VERSION "eCMP INFO-DIV vehicle review 2026-11-03; 125000 bit/s; PSA-RE 67f7581e7622410efdbb29c7eda3b86982b9b450; Apache-2.0"

NS_ :

BS_:

BU_: AAS AMPLI AVP BCM BGP BSG BSI BTA BTEL BTT CDC CMB CRT DIAG_TOOL EDP_C EMF FMUX IC ICSV IDVR IVC_D MATT MDS OVIP PDS_C RAD RBG SDCM VTH WLC

BO_ 1894 BSI_DiagRequestToWLC: 8 BSI
 SG_ FlowPadding5 m3 : 63|8@0+ (1,0) [0|255] "raw"  WLC
 SG_ FirstData6 m1 : 63|8@0+ (1,0) [0|255] "raw"  WLC
 SG_ UnknownData7 m4 : 63|8@0+ (1,0) [0|255] "raw"  WLC
 SG_ ConsecutiveData7 m2 : 63|8@0+ (1,0) [0|255] "raw"  WLC
 SG_ SingleData7 m0 : 63|8@0+ (1,0) [0|255] "raw"  WLC
 SG_ FlowPadding4 m3 : 55|8@0+ (1,0) [0|255] "raw"  WLC
 SG_ FirstData5 m1 : 55|8@0+ (1,0) [0|255] "raw"  WLC
 SG_ UnknownData6 m4 : 55|8@0+ (1,0) [0|255] "raw"  WLC
 SG_ ConsecutiveData6 m2 : 55|8@0+ (1,0) [0|255] "raw"  WLC
 SG_ SingleData6 m0 : 55|8@0+ (1,0) [0|255] "raw"  WLC
 SG_ FlowPadding3 m3 : 47|8@0+ (1,0) [0|255] "raw"  WLC
 SG_ FirstData4 m1 : 47|8@0+ (1,0) [0|255] "raw"  WLC
 SG_ UnknownData5 m4 : 47|8@0+ (1,0) [0|255] "raw"  WLC
 SG_ ConsecutiveData5 m2 : 47|8@0+ (1,0) [0|255] "raw"  WLC
 SG_ SingleData5 m0 : 47|8@0+ (1,0) [0|255] "raw"  WLC
 SG_ FlowPadding2 m3 : 39|8@0+ (1,0) [0|255] "raw"  WLC
 SG_ FirstData3 m1 : 39|8@0+ (1,0) [0|255] "raw"  WLC
 SG_ UnknownData4 m4 : 39|8@0+ (1,0) [0|255] "raw"  WLC
 SG_ ConsecutiveData4 m2 : 39|8@0+ (1,0) [0|255] "raw"  WLC
 SG_ SingleData4 m0 : 39|8@0+ (1,0) [0|255] "raw"  WLC
 SG_ FlowPadding1 m3 : 31|8@0+ (1,0) [0|255] "raw"  WLC
 SG_ FirstData2 m1 : 31|8@0+ (1,0) [0|255] "raw"  WLC
 SG_ UnknownData3 m4 : 31|8@0+ (1,0) [0|255] "raw"  WLC
 SG_ ConsecutiveData3 m2 : 31|8@0+ (1,0) [0|255] "raw"  WLC
 SG_ SingleData3 m0 : 31|8@0+ (1,0) [0|255] "raw"  WLC
 SG_ FirstData1 m1 : 23|8@0+ (1,0) [0|255] "raw"  WLC
 SG_ UnknownData2 m4 : 23|8@0+ (1,0) [0|255] "raw"  WLC
 SG_ ConsecutiveData2 m2 : 23|8@0+ (1,0) [0|255] "raw"  WLC
 SG_ SingleData2 m0 : 23|8@0+ (1,0) [0|255] "raw"  WLC
 SG_ SeparationTimeRaw m3 : 23|8@0+ (1,0) [0|255] "raw"  WLC
 SG_ UnknownData1 m4 : 15|8@0+ (1,0) [0|255] "raw"  WLC
 SG_ ConsecutiveData1 m2 : 15|8@0+ (1,0) [0|255] "raw"  WLC
 SG_ SingleData1 m0 : 15|8@0+ (1,0) [0|255] "raw"  WLC
 SG_ BlockSize m3 : 15|8@0+ (1,0) [0|255] "raw"  WLC
 SG_ UnknownPciLow m4 : 3|4@0+ (1,0) [0|15] "raw"  WLC
 SG_ FlowStatus m3 : 3|4@0+ (1,0) [0|15] "raw"  WLC
 SG_ ConsecutiveSequence m2 : 3|4@0+ (1,0) [0|15] "raw"  WLC
 SG_ FirstFrameLength m1 : 3|12@0+ (1,0) [0|4095] "raw"  WLC
 SG_ SingleFrameLength m0 : 3|4@0+ (1,0) [0|15] "raw"  WLC
 SG_ IsoTpFrameType M : 7|4@0+ (1,0) [0|15] ""  WLC

BO_ 1899 MDS_DiagRequestToBSI_20: 8 MDS
 SG_ FlowPadding5 m3 : 63|8@0+ (1,0) [0|255] "raw"  BSI
 SG_ FirstData6 m1 : 63|8@0+ (1,0) [0|255] "raw"  BSI
 SG_ UnknownData7 m4 : 63|8@0+ (1,0) [0|255] "raw"  BSI
 SG_ ConsecutiveData7 m2 : 63|8@0+ (1,0) [0|255] "raw"  BSI
 SG_ SingleData7 m0 : 63|8@0+ (1,0) [0|255] "raw"  BSI
 SG_ FlowPadding4 m3 : 55|8@0+ (1,0) [0|255] "raw"  BSI
 SG_ FirstData5 m1 : 55|8@0+ (1,0) [0|255] "raw"  BSI
 SG_ UnknownData6 m4 : 55|8@0+ (1,0) [0|255] "raw"  BSI
 SG_ ConsecutiveData6 m2 : 55|8@0+ (1,0) [0|255] "raw"  BSI
 SG_ SingleData6 m0 : 55|8@0+ (1,0) [0|255] "raw"  BSI
 SG_ FlowPadding3 m3 : 47|8@0+ (1,0) [0|255] "raw"  BSI
 SG_ FirstData4 m1 : 47|8@0+ (1,0) [0|255] "raw"  BSI
 SG_ UnknownData5 m4 : 47|8@0+ (1,0) [0|255] "raw"  BSI
 SG_ ConsecutiveData5 m2 : 47|8@0+ (1,0) [0|255] "raw"  BSI
 SG_ SingleData5 m0 : 47|8@0+ (1,0) [0|255] "raw"  BSI
 SG_ FlowPadding2 m3 : 39|8@0+ (1,0) [0|255] "raw"  BSI
 SG_ FirstData3 m1 : 39|8@0+ (1,0) [0|255] "raw"  BSI
 SG_ UnknownData4 m4 : 39|8@0+ (1,0) [0|255] "raw"  BSI
 SG_ ConsecutiveData4 m2 : 39|8@0+ (1,0) [0|255] "raw"  BSI
 SG_ SingleData4 m0 : 39|8@0+ (1,0) [0|255] "raw"  BSI
 SG_ FlowPadding1 m3 : 31|8@0+ (1,0) [0|255] "raw"  BSI
 SG_ FirstData2 m1 : 31|8@0+ (1,0) [0|255] "raw"  BSI
 SG_ UnknownData3 m4 : 31|8@0+ (1,0) [0|255] "raw"  BSI
 SG_ ConsecutiveData3 m2 : 31|8@0+ (1,0) [0|255] "raw"  BSI
 SG_ SingleData3 m0 : 31|8@0+ (1,0) [0|255] "raw"  BSI
 SG_ FirstData1 m1 : 23|8@0+ (1,0) [0|255] "raw"  BSI
 SG_ UnknownData2 m4 : 23|8@0+ (1,0) [0|255] "raw"  BSI
 SG_ ConsecutiveData2 m2 : 23|8@0+ (1,0) [0|255] "raw"  BSI
 SG_ SingleData2 m0 : 23|8@0+ (1,0) [0|255] "raw"  BSI
 SG_ SeparationTimeRaw m3 : 23|8@0+ (1,0) [0|255] "raw"  BSI
 SG_ UnknownData1 m4 : 15|8@0+ (1,0) [0|255] "raw"  BSI
 SG_ ConsecutiveData1 m2 : 15|8@0+ (1,0) [0|255] "raw"  BSI
 SG_ SingleData1 m0 : 15|8@0+ (1,0) [0|255] "raw"  BSI
 SG_ BlockSize m3 : 15|8@0+ (1,0) [0|255] "raw"  BSI
 SG_ UnknownPciLow m4 : 3|4@0+ (1,0) [0|15] "raw"  BSI
 SG_ FlowStatus m3 : 3|4@0+ (1,0) [0|15] "raw"  BSI
 SG_ ConsecutiveSequence m2 : 3|4@0+ (1,0) [0|15] "raw"  BSI
 SG_ FirstFrameLength m1 : 3|12@0+ (1,0) [0|4095] "raw"  BSI
 SG_ SingleFrameLength m0 : 3|4@0+ (1,0) [0|15] "raw"  BSI
 SG_ IsoTpFrameType M : 7|4@0+ (1,0) [0|15] ""  BSI

BO_ 1900 MDS_DiagRequestToBSI_21: 8 MDS
 SG_ FlowPadding5 m3 : 63|8@0+ (1,0) [0|255] "raw"  BSI
 SG_ FirstData6 m1 : 63|8@0+ (1,0) [0|255] "raw"  BSI
 SG_ UnknownData7 m4 : 63|8@0+ (1,0) [0|255] "raw"  BSI
 SG_ ConsecutiveData7 m2 : 63|8@0+ (1,0) [0|255] "raw"  BSI
 SG_ SingleData7 m0 : 63|8@0+ (1,0) [0|255] "raw"  BSI
 SG_ FlowPadding4 m3 : 55|8@0+ (1,0) [0|255] "raw"  BSI
 SG_ FirstData5 m1 : 55|8@0+ (1,0) [0|255] "raw"  BSI
 SG_ UnknownData6 m4 : 55|8@0+ (1,0) [0|255] "raw"  BSI
 SG_ ConsecutiveData6 m2 : 55|8@0+ (1,0) [0|255] "raw"  BSI
 SG_ SingleData6 m0 : 55|8@0+ (1,0) [0|255] "raw"  BSI
 SG_ FlowPadding3 m3 : 47|8@0+ (1,0) [0|255] "raw"  BSI
 SG_ FirstData4 m1 : 47|8@0+ (1,0) [0|255] "raw"  BSI
 SG_ UnknownData5 m4 : 47|8@0+ (1,0) [0|255] "raw"  BSI
 SG_ ConsecutiveData5 m2 : 47|8@0+ (1,0) [0|255] "raw"  BSI
 SG_ SingleData5 m0 : 47|8@0+ (1,0) [0|255] "raw"  BSI
 SG_ FlowPadding2 m3 : 39|8@0+ (1,0) [0|255] "raw"  BSI
 SG_ FirstData3 m1 : 39|8@0+ (1,0) [0|255] "raw"  BSI
 SG_ UnknownData4 m4 : 39|8@0+ (1,0) [0|255] "raw"  BSI
 SG_ ConsecutiveData4 m2 : 39|8@0+ (1,0) [0|255] "raw"  BSI
 SG_ SingleData4 m0 : 39|8@0+ (1,0) [0|255] "raw"  BSI
 SG_ FlowPadding1 m3 : 31|8@0+ (1,0) [0|255] "raw"  BSI
 SG_ FirstData2 m1 : 31|8@0+ (1,0) [0|255] "raw"  BSI
 SG_ UnknownData3 m4 : 31|8@0+ (1,0) [0|255] "raw"  BSI
 SG_ ConsecutiveData3 m2 : 31|8@0+ (1,0) [0|255] "raw"  BSI
 SG_ SingleData3 m0 : 31|8@0+ (1,0) [0|255] "raw"  BSI
 SG_ FirstData1 m1 : 23|8@0+ (1,0) [0|255] "raw"  BSI
 SG_ UnknownData2 m4 : 23|8@0+ (1,0) [0|255] "raw"  BSI
 SG_ ConsecutiveData2 m2 : 23|8@0+ (1,0) [0|255] "raw"  BSI
 SG_ SingleData2 m0 : 23|8@0+ (1,0) [0|255] "raw"  BSI
 SG_ SeparationTimeRaw m3 : 23|8@0+ (1,0) [0|255] "raw"  BSI
 SG_ UnknownData1 m4 : 15|8@0+ (1,0) [0|255] "raw"  BSI
 SG_ ConsecutiveData1 m2 : 15|8@0+ (1,0) [0|255] "raw"  BSI
 SG_ SingleData1 m0 : 15|8@0+ (1,0) [0|255] "raw"  BSI
 SG_ BlockSize m3 : 15|8@0+ (1,0) [0|255] "raw"  BSI
 SG_ UnknownPciLow m4 : 3|4@0+ (1,0) [0|15] "raw"  BSI
 SG_ FlowStatus m3 : 3|4@0+ (1,0) [0|15] "raw"  BSI
 SG_ ConsecutiveSequence m2 : 3|4@0+ (1,0) [0|15] "raw"  BSI
 SG_ FirstFrameLength m1 : 3|12@0+ (1,0) [0|4095] "raw"  BSI
 SG_ SingleFrameLength m0 : 3|4@0+ (1,0) [0|15] "raw"  BSI
 SG_ IsoTpFrameType M : 7|4@0+ (1,0) [0|15] ""  BSI

BO_ 1901 MDS_DiagRequestToBSI_22: 8 MDS
 SG_ FlowPadding5 m3 : 63|8@0+ (1,0) [0|255] "raw"  BSI
 SG_ FirstData6 m1 : 63|8@0+ (1,0) [0|255] "raw"  BSI
 SG_ UnknownData7 m4 : 63|8@0+ (1,0) [0|255] "raw"  BSI
 SG_ ConsecutiveData7 m2 : 63|8@0+ (1,0) [0|255] "raw"  BSI
 SG_ SingleData7 m0 : 63|8@0+ (1,0) [0|255] "raw"  BSI
 SG_ FlowPadding4 m3 : 55|8@0+ (1,0) [0|255] "raw"  BSI
 SG_ FirstData5 m1 : 55|8@0+ (1,0) [0|255] "raw"  BSI
 SG_ UnknownData6 m4 : 55|8@0+ (1,0) [0|255] "raw"  BSI
 SG_ ConsecutiveData6 m2 : 55|8@0+ (1,0) [0|255] "raw"  BSI
 SG_ SingleData6 m0 : 55|8@0+ (1,0) [0|255] "raw"  BSI
 SG_ FlowPadding3 m3 : 47|8@0+ (1,0) [0|255] "raw"  BSI
 SG_ FirstData4 m1 : 47|8@0+ (1,0) [0|255] "raw"  BSI
 SG_ UnknownData5 m4 : 47|8@0+ (1,0) [0|255] "raw"  BSI
 SG_ ConsecutiveData5 m2 : 47|8@0+ (1,0) [0|255] "raw"  BSI
 SG_ SingleData5 m0 : 47|8@0+ (1,0) [0|255] "raw"  BSI
 SG_ FlowPadding2 m3 : 39|8@0+ (1,0) [0|255] "raw"  BSI
 SG_ FirstData3 m1 : 39|8@0+ (1,0) [0|255] "raw"  BSI
 SG_ UnknownData4 m4 : 39|8@0+ (1,0) [0|255] "raw"  BSI
 SG_ ConsecutiveData4 m2 : 39|8@0+ (1,0) [0|255] "raw"  BSI
 SG_ SingleData4 m0 : 39|8@0+ (1,0) [0|255] "raw"  BSI
 SG_ FlowPadding1 m3 : 31|8@0+ (1,0) [0|255] "raw"  BSI
 SG_ FirstData2 m1 : 31|8@0+ (1,0) [0|255] "raw"  BSI
 SG_ UnknownData3 m4 : 31|8@0+ (1,0) [0|255] "raw"  BSI
 SG_ ConsecutiveData3 m2 : 31|8@0+ (1,0) [0|255] "raw"  BSI
 SG_ SingleData3 m0 : 31|8@0+ (1,0) [0|255] "raw"  BSI
 SG_ FirstData1 m1 : 23|8@0+ (1,0) [0|255] "raw"  BSI
 SG_ UnknownData2 m4 : 23|8@0+ (1,0) [0|255] "raw"  BSI
 SG_ ConsecutiveData2 m2 : 23|8@0+ (1,0) [0|255] "raw"  BSI
 SG_ SingleData2 m0 : 23|8@0+ (1,0) [0|255] "raw"  BSI
 SG_ SeparationTimeRaw m3 : 23|8@0+ (1,0) [0|255] "raw"  BSI
 SG_ UnknownData1 m4 : 15|8@0+ (1,0) [0|255] "raw"  BSI
 SG_ ConsecutiveData1 m2 : 15|8@0+ (1,0) [0|255] "raw"  BSI
 SG_ SingleData1 m0 : 15|8@0+ (1,0) [0|255] "raw"  BSI
 SG_ BlockSize m3 : 15|8@0+ (1,0) [0|255] "raw"  BSI
 SG_ UnknownPciLow m4 : 3|4@0+ (1,0) [0|15] "raw"  BSI
 SG_ FlowStatus m3 : 3|4@0+ (1,0) [0|15] "raw"  BSI
 SG_ ConsecutiveSequence m2 : 3|4@0+ (1,0) [0|15] "raw"  BSI
 SG_ FirstFrameLength m1 : 3|12@0+ (1,0) [0|4095] "raw"  BSI
 SG_ SingleFrameLength m0 : 3|4@0+ (1,0) [0|15] "raw"  BSI
 SG_ IsoTpFrameType M : 7|4@0+ (1,0) [0|15] ""  BSI

BO_ 1902 MDS_DiagRequestToBSI_23: 8 MDS
 SG_ FlowPadding5 m3 : 63|8@0+ (1,0) [0|255] "raw"  BSI
 SG_ FirstData6 m1 : 63|8@0+ (1,0) [0|255] "raw"  BSI
 SG_ UnknownData7 m4 : 63|8@0+ (1,0) [0|255] "raw"  BSI
 SG_ ConsecutiveData7 m2 : 63|8@0+ (1,0) [0|255] "raw"  BSI
 SG_ SingleData7 m0 : 63|8@0+ (1,0) [0|255] "raw"  BSI
 SG_ FlowPadding4 m3 : 55|8@0+ (1,0) [0|255] "raw"  BSI
 SG_ FirstData5 m1 : 55|8@0+ (1,0) [0|255] "raw"  BSI
 SG_ UnknownData6 m4 : 55|8@0+ (1,0) [0|255] "raw"  BSI
 SG_ ConsecutiveData6 m2 : 55|8@0+ (1,0) [0|255] "raw"  BSI
 SG_ SingleData6 m0 : 55|8@0+ (1,0) [0|255] "raw"  BSI
 SG_ FlowPadding3 m3 : 47|8@0+ (1,0) [0|255] "raw"  BSI
 SG_ FirstData4 m1 : 47|8@0+ (1,0) [0|255] "raw"  BSI
 SG_ UnknownData5 m4 : 47|8@0+ (1,0) [0|255] "raw"  BSI
 SG_ ConsecutiveData5 m2 : 47|8@0+ (1,0) [0|255] "raw"  BSI
 SG_ SingleData5 m0 : 47|8@0+ (1,0) [0|255] "raw"  BSI
 SG_ FlowPadding2 m3 : 39|8@0+ (1,0) [0|255] "raw"  BSI
 SG_ FirstData3 m1 : 39|8@0+ (1,0) [0|255] "raw"  BSI
 SG_ UnknownData4 m4 : 39|8@0+ (1,0) [0|255] "raw"  BSI
 SG_ ConsecutiveData4 m2 : 39|8@0+ (1,0) [0|255] "raw"  BSI
 SG_ SingleData4 m0 : 39|8@0+ (1,0) [0|255] "raw"  BSI
 SG_ FlowPadding1 m3 : 31|8@0+ (1,0) [0|255] "raw"  BSI
 SG_ FirstData2 m1 : 31|8@0+ (1,0) [0|255] "raw"  BSI
 SG_ UnknownData3 m4 : 31|8@0+ (1,0) [0|255] "raw"  BSI
 SG_ ConsecutiveData3 m2 : 31|8@0+ (1,0) [0|255] "raw"  BSI
 SG_ SingleData3 m0 : 31|8@0+ (1,0) [0|255] "raw"  BSI
 SG_ FirstData1 m1 : 23|8@0+ (1,0) [0|255] "raw"  BSI
 SG_ UnknownData2 m4 : 23|8@0+ (1,0) [0|255] "raw"  BSI
 SG_ ConsecutiveData2 m2 : 23|8@0+ (1,0) [0|255] "raw"  BSI
 SG_ SingleData2 m0 : 23|8@0+ (1,0) [0|255] "raw"  BSI
 SG_ SeparationTimeRaw m3 : 23|8@0+ (1,0) [0|255] "raw"  BSI
 SG_ UnknownData1 m4 : 15|8@0+ (1,0) [0|255] "raw"  BSI
 SG_ ConsecutiveData1 m2 : 15|8@0+ (1,0) [0|255] "raw"  BSI
 SG_ SingleData1 m0 : 15|8@0+ (1,0) [0|255] "raw"  BSI
 SG_ BlockSize m3 : 15|8@0+ (1,0) [0|255] "raw"  BSI
 SG_ UnknownPciLow m4 : 3|4@0+ (1,0) [0|15] "raw"  BSI
 SG_ FlowStatus m3 : 3|4@0+ (1,0) [0|15] "raw"  BSI
 SG_ ConsecutiveSequence m2 : 3|4@0+ (1,0) [0|15] "raw"  BSI
 SG_ FirstFrameLength m1 : 3|12@0+ (1,0) [0|4095] "raw"  BSI
 SG_ SingleFrameLength m0 : 3|4@0+ (1,0) [0|15] "raw"  BSI
 SG_ IsoTpFrameType M : 7|4@0+ (1,0) [0|15] ""  BSI

BO_ 1903 MDS_DiagRequestToBSI_24: 8 MDS
 SG_ FlowPadding5 m3 : 63|8@0+ (1,0) [0|255] "raw"  BSI
 SG_ FirstData6 m1 : 63|8@0+ (1,0) [0|255] "raw"  BSI
 SG_ UnknownData7 m4 : 63|8@0+ (1,0) [0|255] "raw"  BSI
 SG_ ConsecutiveData7 m2 : 63|8@0+ (1,0) [0|255] "raw"  BSI
 SG_ SingleData7 m0 : 63|8@0+ (1,0) [0|255] "raw"  BSI
 SG_ FlowPadding4 m3 : 55|8@0+ (1,0) [0|255] "raw"  BSI
 SG_ FirstData5 m1 : 55|8@0+ (1,0) [0|255] "raw"  BSI
 SG_ UnknownData6 m4 : 55|8@0+ (1,0) [0|255] "raw"  BSI
 SG_ ConsecutiveData6 m2 : 55|8@0+ (1,0) [0|255] "raw"  BSI
 SG_ SingleData6 m0 : 55|8@0+ (1,0) [0|255] "raw"  BSI
 SG_ FlowPadding3 m3 : 47|8@0+ (1,0) [0|255] "raw"  BSI
 SG_ FirstData4 m1 : 47|8@0+ (1,0) [0|255] "raw"  BSI
 SG_ UnknownData5 m4 : 47|8@0+ (1,0) [0|255] "raw"  BSI
 SG_ ConsecutiveData5 m2 : 47|8@0+ (1,0) [0|255] "raw"  BSI
 SG_ SingleData5 m0 : 47|8@0+ (1,0) [0|255] "raw"  BSI
 SG_ FlowPadding2 m3 : 39|8@0+ (1,0) [0|255] "raw"  BSI
 SG_ FirstData3 m1 : 39|8@0+ (1,0) [0|255] "raw"  BSI
 SG_ UnknownData4 m4 : 39|8@0+ (1,0) [0|255] "raw"  BSI
 SG_ ConsecutiveData4 m2 : 39|8@0+ (1,0) [0|255] "raw"  BSI
 SG_ SingleData4 m0 : 39|8@0+ (1,0) [0|255] "raw"  BSI
 SG_ FlowPadding1 m3 : 31|8@0+ (1,0) [0|255] "raw"  BSI
 SG_ FirstData2 m1 : 31|8@0+ (1,0) [0|255] "raw"  BSI
 SG_ UnknownData3 m4 : 31|8@0+ (1,0) [0|255] "raw"  BSI
 SG_ ConsecutiveData3 m2 : 31|8@0+ (1,0) [0|255] "raw"  BSI
 SG_ SingleData3 m0 : 31|8@0+ (1,0) [0|255] "raw"  BSI
 SG_ FirstData1 m1 : 23|8@0+ (1,0) [0|255] "raw"  BSI
 SG_ UnknownData2 m4 : 23|8@0+ (1,0) [0|255] "raw"  BSI
 SG_ ConsecutiveData2 m2 : 23|8@0+ (1,0) [0|255] "raw"  BSI
 SG_ SingleData2 m0 : 23|8@0+ (1,0) [0|255] "raw"  BSI
 SG_ SeparationTimeRaw m3 : 23|8@0+ (1,0) [0|255] "raw"  BSI
 SG_ UnknownData1 m4 : 15|8@0+ (1,0) [0|255] "raw"  BSI
 SG_ ConsecutiveData1 m2 : 15|8@0+ (1,0) [0|255] "raw"  BSI
 SG_ SingleData1 m0 : 15|8@0+ (1,0) [0|255] "raw"  BSI
 SG_ BlockSize m3 : 15|8@0+ (1,0) [0|255] "raw"  BSI
 SG_ UnknownPciLow m4 : 3|4@0+ (1,0) [0|15] "raw"  BSI
 SG_ FlowStatus m3 : 3|4@0+ (1,0) [0|15] "raw"  BSI
 SG_ ConsecutiveSequence m2 : 3|4@0+ (1,0) [0|15] "raw"  BSI
 SG_ FirstFrameLength m1 : 3|12@0+ (1,0) [0|4095] "raw"  BSI
 SG_ SingleFrameLength m0 : 3|4@0+ (1,0) [0|15] "raw"  BSI
 SG_ IsoTpFrameType M : 7|4@0+ (1,0) [0|15] ""  BSI

BO_ 1904 BSI_DiagRequestToVTH: 8 BSI
 SG_ FlowPadding5 m3 : 63|8@0+ (1,0) [0|255] "raw"  VTH
 SG_ FirstData6 m1 : 63|8@0+ (1,0) [0|255] "raw"  VTH
 SG_ UnknownData7 m4 : 63|8@0+ (1,0) [0|255] "raw"  VTH
 SG_ ConsecutiveData7 m2 : 63|8@0+ (1,0) [0|255] "raw"  VTH
 SG_ SingleData7 m0 : 63|8@0+ (1,0) [0|255] "raw"  VTH
 SG_ FlowPadding4 m3 : 55|8@0+ (1,0) [0|255] "raw"  VTH
 SG_ FirstData5 m1 : 55|8@0+ (1,0) [0|255] "raw"  VTH
 SG_ UnknownData6 m4 : 55|8@0+ (1,0) [0|255] "raw"  VTH
 SG_ ConsecutiveData6 m2 : 55|8@0+ (1,0) [0|255] "raw"  VTH
 SG_ SingleData6 m0 : 55|8@0+ (1,0) [0|255] "raw"  VTH
 SG_ FlowPadding3 m3 : 47|8@0+ (1,0) [0|255] "raw"  VTH
 SG_ FirstData4 m1 : 47|8@0+ (1,0) [0|255] "raw"  VTH
 SG_ UnknownData5 m4 : 47|8@0+ (1,0) [0|255] "raw"  VTH
 SG_ ConsecutiveData5 m2 : 47|8@0+ (1,0) [0|255] "raw"  VTH
 SG_ SingleData5 m0 : 47|8@0+ (1,0) [0|255] "raw"  VTH
 SG_ FlowPadding2 m3 : 39|8@0+ (1,0) [0|255] "raw"  VTH
 SG_ FirstData3 m1 : 39|8@0+ (1,0) [0|255] "raw"  VTH
 SG_ UnknownData4 m4 : 39|8@0+ (1,0) [0|255] "raw"  VTH
 SG_ ConsecutiveData4 m2 : 39|8@0+ (1,0) [0|255] "raw"  VTH
 SG_ SingleData4 m0 : 39|8@0+ (1,0) [0|255] "raw"  VTH
 SG_ FlowPadding1 m3 : 31|8@0+ (1,0) [0|255] "raw"  VTH
 SG_ FirstData2 m1 : 31|8@0+ (1,0) [0|255] "raw"  VTH
 SG_ UnknownData3 m4 : 31|8@0+ (1,0) [0|255] "raw"  VTH
 SG_ ConsecutiveData3 m2 : 31|8@0+ (1,0) [0|255] "raw"  VTH
 SG_ SingleData3 m0 : 31|8@0+ (1,0) [0|255] "raw"  VTH
 SG_ FirstData1 m1 : 23|8@0+ (1,0) [0|255] "raw"  VTH
 SG_ UnknownData2 m4 : 23|8@0+ (1,0) [0|255] "raw"  VTH
 SG_ ConsecutiveData2 m2 : 23|8@0+ (1,0) [0|255] "raw"  VTH
 SG_ SingleData2 m0 : 23|8@0+ (1,0) [0|255] "raw"  VTH
 SG_ SeparationTimeRaw m3 : 23|8@0+ (1,0) [0|255] "raw"  VTH
 SG_ UnknownData1 m4 : 15|8@0+ (1,0) [0|255] "raw"  VTH
 SG_ ConsecutiveData1 m2 : 15|8@0+ (1,0) [0|255] "raw"  VTH
 SG_ SingleData1 m0 : 15|8@0+ (1,0) [0|255] "raw"  VTH
 SG_ BlockSize m3 : 15|8@0+ (1,0) [0|255] "raw"  VTH
 SG_ UnknownPciLow m4 : 3|4@0+ (1,0) [0|15] "raw"  VTH
 SG_ FlowStatus m3 : 3|4@0+ (1,0) [0|15] "raw"  VTH
 SG_ ConsecutiveSequence m2 : 3|4@0+ (1,0) [0|15] "raw"  VTH
 SG_ FirstFrameLength m1 : 3|12@0+ (1,0) [0|4095] "raw"  VTH
 SG_ SingleFrameLength m0 : 3|4@0+ (1,0) [0|15] "raw"  VTH
 SG_ IsoTpFrameType M : 7|4@0+ (1,0) [0|15] ""  VTH

BO_ 1905 BSI_DiagRequestToCDC: 8 BSI
 SG_ FlowPadding5 m3 : 63|8@0+ (1,0) [0|255] "raw"  CDC
 SG_ FirstData6 m1 : 63|8@0+ (1,0) [0|255] "raw"  CDC
 SG_ UnknownData7 m4 : 63|8@0+ (1,0) [0|255] "raw"  CDC
 SG_ ConsecutiveData7 m2 : 63|8@0+ (1,0) [0|255] "raw"  CDC
 SG_ SingleData7 m0 : 63|8@0+ (1,0) [0|255] "raw"  CDC
 SG_ FlowPadding4 m3 : 55|8@0+ (1,0) [0|255] "raw"  CDC
 SG_ FirstData5 m1 : 55|8@0+ (1,0) [0|255] "raw"  CDC
 SG_ UnknownData6 m4 : 55|8@0+ (1,0) [0|255] "raw"  CDC
 SG_ ConsecutiveData6 m2 : 55|8@0+ (1,0) [0|255] "raw"  CDC
 SG_ SingleData6 m0 : 55|8@0+ (1,0) [0|255] "raw"  CDC
 SG_ FlowPadding3 m3 : 47|8@0+ (1,0) [0|255] "raw"  CDC
 SG_ FirstData4 m1 : 47|8@0+ (1,0) [0|255] "raw"  CDC
 SG_ UnknownData5 m4 : 47|8@0+ (1,0) [0|255] "raw"  CDC
 SG_ ConsecutiveData5 m2 : 47|8@0+ (1,0) [0|255] "raw"  CDC
 SG_ SingleData5 m0 : 47|8@0+ (1,0) [0|255] "raw"  CDC
 SG_ FlowPadding2 m3 : 39|8@0+ (1,0) [0|255] "raw"  CDC
 SG_ FirstData3 m1 : 39|8@0+ (1,0) [0|255] "raw"  CDC
 SG_ UnknownData4 m4 : 39|8@0+ (1,0) [0|255] "raw"  CDC
 SG_ ConsecutiveData4 m2 : 39|8@0+ (1,0) [0|255] "raw"  CDC
 SG_ SingleData4 m0 : 39|8@0+ (1,0) [0|255] "raw"  CDC
 SG_ FlowPadding1 m3 : 31|8@0+ (1,0) [0|255] "raw"  CDC
 SG_ FirstData2 m1 : 31|8@0+ (1,0) [0|255] "raw"  CDC
 SG_ UnknownData3 m4 : 31|8@0+ (1,0) [0|255] "raw"  CDC
 SG_ ConsecutiveData3 m2 : 31|8@0+ (1,0) [0|255] "raw"  CDC
 SG_ SingleData3 m0 : 31|8@0+ (1,0) [0|255] "raw"  CDC
 SG_ FirstData1 m1 : 23|8@0+ (1,0) [0|255] "raw"  CDC
 SG_ UnknownData2 m4 : 23|8@0+ (1,0) [0|255] "raw"  CDC
 SG_ ConsecutiveData2 m2 : 23|8@0+ (1,0) [0|255] "raw"  CDC
 SG_ SingleData2 m0 : 23|8@0+ (1,0) [0|255] "raw"  CDC
 SG_ SeparationTimeRaw m3 : 23|8@0+ (1,0) [0|255] "raw"  CDC
 SG_ UnknownData1 m4 : 15|8@0+ (1,0) [0|255] "raw"  CDC
 SG_ ConsecutiveData1 m2 : 15|8@0+ (1,0) [0|255] "raw"  CDC
 SG_ SingleData1 m0 : 15|8@0+ (1,0) [0|255] "raw"  CDC
 SG_ BlockSize m3 : 15|8@0+ (1,0) [0|255] "raw"  CDC
 SG_ UnknownPciLow m4 : 3|4@0+ (1,0) [0|15] "raw"  CDC
 SG_ FlowStatus m3 : 3|4@0+ (1,0) [0|15] "raw"  CDC
 SG_ ConsecutiveSequence m2 : 3|4@0+ (1,0) [0|15] "raw"  CDC
 SG_ FirstFrameLength m1 : 3|12@0+ (1,0) [0|4095] "raw"  CDC
 SG_ SingleFrameLength m0 : 3|4@0+ (1,0) [0|15] "raw"  CDC
 SG_ IsoTpFrameType M : 7|4@0+ (1,0) [0|15] ""  CDC

BO_ 1906 BSI_DiagRequestToMATT: 8 BSI
 SG_ FlowPadding5 m3 : 63|8@0+ (1,0) [0|255] "raw"  MATT
 SG_ FirstData6 m1 : 63|8@0+ (1,0) [0|255] "raw"  MATT
 SG_ UnknownData7 m4 : 63|8@0+ (1,0) [0|255] "raw"  MATT
 SG_ ConsecutiveData7 m2 : 63|8@0+ (1,0) [0|255] "raw"  MATT
 SG_ SingleData7 m0 : 63|8@0+ (1,0) [0|255] "raw"  MATT
 SG_ FlowPadding4 m3 : 55|8@0+ (1,0) [0|255] "raw"  MATT
 SG_ FirstData5 m1 : 55|8@0+ (1,0) [0|255] "raw"  MATT
 SG_ UnknownData6 m4 : 55|8@0+ (1,0) [0|255] "raw"  MATT
 SG_ ConsecutiveData6 m2 : 55|8@0+ (1,0) [0|255] "raw"  MATT
 SG_ SingleData6 m0 : 55|8@0+ (1,0) [0|255] "raw"  MATT
 SG_ FlowPadding3 m3 : 47|8@0+ (1,0) [0|255] "raw"  MATT
 SG_ FirstData4 m1 : 47|8@0+ (1,0) [0|255] "raw"  MATT
 SG_ UnknownData5 m4 : 47|8@0+ (1,0) [0|255] "raw"  MATT
 SG_ ConsecutiveData5 m2 : 47|8@0+ (1,0) [0|255] "raw"  MATT
 SG_ SingleData5 m0 : 47|8@0+ (1,0) [0|255] "raw"  MATT
 SG_ FlowPadding2 m3 : 39|8@0+ (1,0) [0|255] "raw"  MATT
 SG_ FirstData3 m1 : 39|8@0+ (1,0) [0|255] "raw"  MATT
 SG_ UnknownData4 m4 : 39|8@0+ (1,0) [0|255] "raw"  MATT
 SG_ ConsecutiveData4 m2 : 39|8@0+ (1,0) [0|255] "raw"  MATT
 SG_ SingleData4 m0 : 39|8@0+ (1,0) [0|255] "raw"  MATT
 SG_ FlowPadding1 m3 : 31|8@0+ (1,0) [0|255] "raw"  MATT
 SG_ FirstData2 m1 : 31|8@0+ (1,0) [0|255] "raw"  MATT
 SG_ UnknownData3 m4 : 31|8@0+ (1,0) [0|255] "raw"  MATT
 SG_ ConsecutiveData3 m2 : 31|8@0+ (1,0) [0|255] "raw"  MATT
 SG_ SingleData3 m0 : 31|8@0+ (1,0) [0|255] "raw"  MATT
 SG_ FirstData1 m1 : 23|8@0+ (1,0) [0|255] "raw"  MATT
 SG_ UnknownData2 m4 : 23|8@0+ (1,0) [0|255] "raw"  MATT
 SG_ ConsecutiveData2 m2 : 23|8@0+ (1,0) [0|255] "raw"  MATT
 SG_ SingleData2 m0 : 23|8@0+ (1,0) [0|255] "raw"  MATT
 SG_ SeparationTimeRaw m3 : 23|8@0+ (1,0) [0|255] "raw"  MATT
 SG_ UnknownData1 m4 : 15|8@0+ (1,0) [0|255] "raw"  MATT
 SG_ ConsecutiveData1 m2 : 15|8@0+ (1,0) [0|255] "raw"  MATT
 SG_ SingleData1 m0 : 15|8@0+ (1,0) [0|255] "raw"  MATT
 SG_ BlockSize m3 : 15|8@0+ (1,0) [0|255] "raw"  MATT
 SG_ UnknownPciLow m4 : 3|4@0+ (1,0) [0|15] "raw"  MATT
 SG_ FlowStatus m3 : 3|4@0+ (1,0) [0|15] "raw"  MATT
 SG_ ConsecutiveSequence m2 : 3|4@0+ (1,0) [0|15] "raw"  MATT
 SG_ FirstFrameLength m1 : 3|12@0+ (1,0) [0|4095] "raw"  MATT
 SG_ SingleFrameLength m0 : 3|4@0+ (1,0) [0|15] "raw"  MATT
 SG_ IsoTpFrameType M : 7|4@0+ (1,0) [0|15] ""  MATT

BO_ 1907 BSI_DiagRequestToAVP: 8 BSI
 SG_ FlowPadding5 m3 : 63|8@0+ (1,0) [0|255] "raw"  AVP
 SG_ FirstData6 m1 : 63|8@0+ (1,0) [0|255] "raw"  AVP
 SG_ UnknownData7 m4 : 63|8@0+ (1,0) [0|255] "raw"  AVP
 SG_ ConsecutiveData7 m2 : 63|8@0+ (1,0) [0|255] "raw"  AVP
 SG_ SingleData7 m0 : 63|8@0+ (1,0) [0|255] "raw"  AVP
 SG_ FlowPadding4 m3 : 55|8@0+ (1,0) [0|255] "raw"  AVP
 SG_ FirstData5 m1 : 55|8@0+ (1,0) [0|255] "raw"  AVP
 SG_ UnknownData6 m4 : 55|8@0+ (1,0) [0|255] "raw"  AVP
 SG_ ConsecutiveData6 m2 : 55|8@0+ (1,0) [0|255] "raw"  AVP
 SG_ SingleData6 m0 : 55|8@0+ (1,0) [0|255] "raw"  AVP
 SG_ FlowPadding3 m3 : 47|8@0+ (1,0) [0|255] "raw"  AVP
 SG_ FirstData4 m1 : 47|8@0+ (1,0) [0|255] "raw"  AVP
 SG_ UnknownData5 m4 : 47|8@0+ (1,0) [0|255] "raw"  AVP
 SG_ ConsecutiveData5 m2 : 47|8@0+ (1,0) [0|255] "raw"  AVP
 SG_ SingleData5 m0 : 47|8@0+ (1,0) [0|255] "raw"  AVP
 SG_ FlowPadding2 m3 : 39|8@0+ (1,0) [0|255] "raw"  AVP
 SG_ FirstData3 m1 : 39|8@0+ (1,0) [0|255] "raw"  AVP
 SG_ UnknownData4 m4 : 39|8@0+ (1,0) [0|255] "raw"  AVP
 SG_ ConsecutiveData4 m2 : 39|8@0+ (1,0) [0|255] "raw"  AVP
 SG_ SingleData4 m0 : 39|8@0+ (1,0) [0|255] "raw"  AVP
 SG_ FlowPadding1 m3 : 31|8@0+ (1,0) [0|255] "raw"  AVP
 SG_ FirstData2 m1 : 31|8@0+ (1,0) [0|255] "raw"  AVP
 SG_ UnknownData3 m4 : 31|8@0+ (1,0) [0|255] "raw"  AVP
 SG_ ConsecutiveData3 m2 : 31|8@0+ (1,0) [0|255] "raw"  AVP
 SG_ SingleData3 m0 : 31|8@0+ (1,0) [0|255] "raw"  AVP
 SG_ FirstData1 m1 : 23|8@0+ (1,0) [0|255] "raw"  AVP
 SG_ UnknownData2 m4 : 23|8@0+ (1,0) [0|255] "raw"  AVP
 SG_ ConsecutiveData2 m2 : 23|8@0+ (1,0) [0|255] "raw"  AVP
 SG_ SingleData2 m0 : 23|8@0+ (1,0) [0|255] "raw"  AVP
 SG_ SeparationTimeRaw m3 : 23|8@0+ (1,0) [0|255] "raw"  AVP
 SG_ UnknownData1 m4 : 15|8@0+ (1,0) [0|255] "raw"  AVP
 SG_ ConsecutiveData1 m2 : 15|8@0+ (1,0) [0|255] "raw"  AVP
 SG_ SingleData1 m0 : 15|8@0+ (1,0) [0|255] "raw"  AVP
 SG_ BlockSize m3 : 15|8@0+ (1,0) [0|255] "raw"  AVP
 SG_ UnknownPciLow m4 : 3|4@0+ (1,0) [0|15] "raw"  AVP
 SG_ FlowStatus m3 : 3|4@0+ (1,0) [0|15] "raw"  AVP
 SG_ ConsecutiveSequence m2 : 3|4@0+ (1,0) [0|15] "raw"  AVP
 SG_ FirstFrameLength m1 : 3|12@0+ (1,0) [0|4095] "raw"  AVP
 SG_ SingleFrameLength m0 : 3|4@0+ (1,0) [0|15] "raw"  AVP
 SG_ IsoTpFrameType M : 7|4@0+ (1,0) [0|15] ""  AVP

BO_ 1908 MDS_DiagRequestToBSI_25: 8 MDS
 SG_ FlowPadding5 m3 : 63|8@0+ (1,0) [0|255] "raw"  BSI
 SG_ FirstData6 m1 : 63|8@0+ (1,0) [0|255] "raw"  BSI
 SG_ UnknownData7 m4 : 63|8@0+ (1,0) [0|255] "raw"  BSI
 SG_ ConsecutiveData7 m2 : 63|8@0+ (1,0) [0|255] "raw"  BSI
 SG_ SingleData7 m0 : 63|8@0+ (1,0) [0|255] "raw"  BSI
 SG_ FlowPadding4 m3 : 55|8@0+ (1,0) [0|255] "raw"  BSI
 SG_ FirstData5 m1 : 55|8@0+ (1,0) [0|255] "raw"  BSI
 SG_ UnknownData6 m4 : 55|8@0+ (1,0) [0|255] "raw"  BSI
 SG_ ConsecutiveData6 m2 : 55|8@0+ (1,0) [0|255] "raw"  BSI
 SG_ SingleData6 m0 : 55|8@0+ (1,0) [0|255] "raw"  BSI
 SG_ FlowPadding3 m3 : 47|8@0+ (1,0) [0|255] "raw"  BSI
 SG_ FirstData4 m1 : 47|8@0+ (1,0) [0|255] "raw"  BSI
 SG_ UnknownData5 m4 : 47|8@0+ (1,0) [0|255] "raw"  BSI
 SG_ ConsecutiveData5 m2 : 47|8@0+ (1,0) [0|255] "raw"  BSI
 SG_ SingleData5 m0 : 47|8@0+ (1,0) [0|255] "raw"  BSI
 SG_ FlowPadding2 m3 : 39|8@0+ (1,0) [0|255] "raw"  BSI
 SG_ FirstData3 m1 : 39|8@0+ (1,0) [0|255] "raw"  BSI
 SG_ UnknownData4 m4 : 39|8@0+ (1,0) [0|255] "raw"  BSI
 SG_ ConsecutiveData4 m2 : 39|8@0+ (1,0) [0|255] "raw"  BSI
 SG_ SingleData4 m0 : 39|8@0+ (1,0) [0|255] "raw"  BSI
 SG_ FlowPadding1 m3 : 31|8@0+ (1,0) [0|255] "raw"  BSI
 SG_ FirstData2 m1 : 31|8@0+ (1,0) [0|255] "raw"  BSI
 SG_ UnknownData3 m4 : 31|8@0+ (1,0) [0|255] "raw"  BSI
 SG_ ConsecutiveData3 m2 : 31|8@0+ (1,0) [0|255] "raw"  BSI
 SG_ SingleData3 m0 : 31|8@0+ (1,0) [0|255] "raw"  BSI
 SG_ FirstData1 m1 : 23|8@0+ (1,0) [0|255] "raw"  BSI
 SG_ UnknownData2 m4 : 23|8@0+ (1,0) [0|255] "raw"  BSI
 SG_ ConsecutiveData2 m2 : 23|8@0+ (1,0) [0|255] "raw"  BSI
 SG_ SingleData2 m0 : 23|8@0+ (1,0) [0|255] "raw"  BSI
 SG_ SeparationTimeRaw m3 : 23|8@0+ (1,0) [0|255] "raw"  BSI
 SG_ UnknownData1 m4 : 15|8@0+ (1,0) [0|255] "raw"  BSI
 SG_ ConsecutiveData1 m2 : 15|8@0+ (1,0) [0|255] "raw"  BSI
 SG_ SingleData1 m0 : 15|8@0+ (1,0) [0|255] "raw"  BSI
 SG_ BlockSize m3 : 15|8@0+ (1,0) [0|255] "raw"  BSI
 SG_ UnknownPciLow m4 : 3|4@0+ (1,0) [0|15] "raw"  BSI
 SG_ FlowStatus m3 : 3|4@0+ (1,0) [0|15] "raw"  BSI
 SG_ ConsecutiveSequence m2 : 3|4@0+ (1,0) [0|15] "raw"  BSI
 SG_ FirstFrameLength m1 : 3|12@0+ (1,0) [0|4095] "raw"  BSI
 SG_ SingleFrameLength m0 : 3|4@0+ (1,0) [0|15] "raw"  BSI
 SG_ IsoTpFrameType M : 7|4@0+ (1,0) [0|15] ""  BSI

BO_ 1910 BSI_FaultLogArtiv: 8 BSI
 SG_ DiagnosticData : 7|64@0+ (1,0) [0|18446744073709551615] ""  BSG

BO_ 1912 MDS_DiagRequestToBSI_26: 8 MDS
 SG_ FlowPadding5 m3 : 63|8@0+ (1,0) [0|255] "raw"  BSI
 SG_ FirstData6 m1 : 63|8@0+ (1,0) [0|255] "raw"  BSI
 SG_ UnknownData7 m4 : 63|8@0+ (1,0) [0|255] "raw"  BSI
 SG_ ConsecutiveData7 m2 : 63|8@0+ (1,0) [0|255] "raw"  BSI
 SG_ SingleData7 m0 : 63|8@0+ (1,0) [0|255] "raw"  BSI
 SG_ FlowPadding4 m3 : 55|8@0+ (1,0) [0|255] "raw"  BSI
 SG_ FirstData5 m1 : 55|8@0+ (1,0) [0|255] "raw"  BSI
 SG_ UnknownData6 m4 : 55|8@0+ (1,0) [0|255] "raw"  BSI
 SG_ ConsecutiveData6 m2 : 55|8@0+ (1,0) [0|255] "raw"  BSI
 SG_ SingleData6 m0 : 55|8@0+ (1,0) [0|255] "raw"  BSI
 SG_ FlowPadding3 m3 : 47|8@0+ (1,0) [0|255] "raw"  BSI
 SG_ FirstData4 m1 : 47|8@0+ (1,0) [0|255] "raw"  BSI
 SG_ UnknownData5 m4 : 47|8@0+ (1,0) [0|255] "raw"  BSI
 SG_ ConsecutiveData5 m2 : 47|8@0+ (1,0) [0|255] "raw"  BSI
 SG_ SingleData5 m0 : 47|8@0+ (1,0) [0|255] "raw"  BSI
 SG_ FlowPadding2 m3 : 39|8@0+ (1,0) [0|255] "raw"  BSI
 SG_ FirstData3 m1 : 39|8@0+ (1,0) [0|255] "raw"  BSI
 SG_ UnknownData4 m4 : 39|8@0+ (1,0) [0|255] "raw"  BSI
 SG_ ConsecutiveData4 m2 : 39|8@0+ (1,0) [0|255] "raw"  BSI
 SG_ SingleData4 m0 : 39|8@0+ (1,0) [0|255] "raw"  BSI
 SG_ FlowPadding1 m3 : 31|8@0+ (1,0) [0|255] "raw"  BSI
 SG_ FirstData2 m1 : 31|8@0+ (1,0) [0|255] "raw"  BSI
 SG_ UnknownData3 m4 : 31|8@0+ (1,0) [0|255] "raw"  BSI
 SG_ ConsecutiveData3 m2 : 31|8@0+ (1,0) [0|255] "raw"  BSI
 SG_ SingleData3 m0 : 31|8@0+ (1,0) [0|255] "raw"  BSI
 SG_ FirstData1 m1 : 23|8@0+ (1,0) [0|255] "raw"  BSI
 SG_ UnknownData2 m4 : 23|8@0+ (1,0) [0|255] "raw"  BSI
 SG_ ConsecutiveData2 m2 : 23|8@0+ (1,0) [0|255] "raw"  BSI
 SG_ SingleData2 m0 : 23|8@0+ (1,0) [0|255] "raw"  BSI
 SG_ SeparationTimeRaw m3 : 23|8@0+ (1,0) [0|255] "raw"  BSI
 SG_ UnknownData1 m4 : 15|8@0+ (1,0) [0|255] "raw"  BSI
 SG_ ConsecutiveData1 m2 : 15|8@0+ (1,0) [0|255] "raw"  BSI
 SG_ SingleData1 m0 : 15|8@0+ (1,0) [0|255] "raw"  BSI
 SG_ BlockSize m3 : 15|8@0+ (1,0) [0|255] "raw"  BSI
 SG_ UnknownPciLow m4 : 3|4@0+ (1,0) [0|15] "raw"  BSI
 SG_ FlowStatus m3 : 3|4@0+ (1,0) [0|15] "raw"  BSI
 SG_ ConsecutiveSequence m2 : 3|4@0+ (1,0) [0|15] "raw"  BSI
 SG_ FirstFrameLength m1 : 3|12@0+ (1,0) [0|4095] "raw"  BSI
 SG_ SingleFrameLength m0 : 3|4@0+ (1,0) [0|15] "raw"  BSI
 SG_ IsoTpFrameType M : 7|4@0+ (1,0) [0|15] ""  BSI

BO_ 1915 BSI_DiagRequestToFMUX_2: 8 BSI
 SG_ FlowPadding5 m3 : 63|8@0+ (1,0) [0|255] "raw"  FMUX
 SG_ FirstData6 m1 : 63|8@0+ (1,0) [0|255] "raw"  FMUX
 SG_ UnknownData7 m4 : 63|8@0+ (1,0) [0|255] "raw"  FMUX
 SG_ ConsecutiveData7 m2 : 63|8@0+ (1,0) [0|255] "raw"  FMUX
 SG_ SingleData7 m0 : 63|8@0+ (1,0) [0|255] "raw"  FMUX
 SG_ FlowPadding4 m3 : 55|8@0+ (1,0) [0|255] "raw"  FMUX
 SG_ FirstData5 m1 : 55|8@0+ (1,0) [0|255] "raw"  FMUX
 SG_ UnknownData6 m4 : 55|8@0+ (1,0) [0|255] "raw"  FMUX
 SG_ ConsecutiveData6 m2 : 55|8@0+ (1,0) [0|255] "raw"  FMUX
 SG_ SingleData6 m0 : 55|8@0+ (1,0) [0|255] "raw"  FMUX
 SG_ FlowPadding3 m3 : 47|8@0+ (1,0) [0|255] "raw"  FMUX
 SG_ FirstData4 m1 : 47|8@0+ (1,0) [0|255] "raw"  FMUX
 SG_ UnknownData5 m4 : 47|8@0+ (1,0) [0|255] "raw"  FMUX
 SG_ ConsecutiveData5 m2 : 47|8@0+ (1,0) [0|255] "raw"  FMUX
 SG_ SingleData5 m0 : 47|8@0+ (1,0) [0|255] "raw"  FMUX
 SG_ FlowPadding2 m3 : 39|8@0+ (1,0) [0|255] "raw"  FMUX
 SG_ FirstData3 m1 : 39|8@0+ (1,0) [0|255] "raw"  FMUX
 SG_ UnknownData4 m4 : 39|8@0+ (1,0) [0|255] "raw"  FMUX
 SG_ ConsecutiveData4 m2 : 39|8@0+ (1,0) [0|255] "raw"  FMUX
 SG_ SingleData4 m0 : 39|8@0+ (1,0) [0|255] "raw"  FMUX
 SG_ FlowPadding1 m3 : 31|8@0+ (1,0) [0|255] "raw"  FMUX
 SG_ FirstData2 m1 : 31|8@0+ (1,0) [0|255] "raw"  FMUX
 SG_ UnknownData3 m4 : 31|8@0+ (1,0) [0|255] "raw"  FMUX
 SG_ ConsecutiveData3 m2 : 31|8@0+ (1,0) [0|255] "raw"  FMUX
 SG_ SingleData3 m0 : 31|8@0+ (1,0) [0|255] "raw"  FMUX
 SG_ FirstData1 m1 : 23|8@0+ (1,0) [0|255] "raw"  FMUX
 SG_ UnknownData2 m4 : 23|8@0+ (1,0) [0|255] "raw"  FMUX
 SG_ ConsecutiveData2 m2 : 23|8@0+ (1,0) [0|255] "raw"  FMUX
 SG_ SingleData2 m0 : 23|8@0+ (1,0) [0|255] "raw"  FMUX
 SG_ SeparationTimeRaw m3 : 23|8@0+ (1,0) [0|255] "raw"  FMUX
 SG_ UnknownData1 m4 : 15|8@0+ (1,0) [0|255] "raw"  FMUX
 SG_ ConsecutiveData1 m2 : 15|8@0+ (1,0) [0|255] "raw"  FMUX
 SG_ SingleData1 m0 : 15|8@0+ (1,0) [0|255] "raw"  FMUX
 SG_ BlockSize m3 : 15|8@0+ (1,0) [0|255] "raw"  FMUX
 SG_ UnknownPciLow m4 : 3|4@0+ (1,0) [0|15] "raw"  FMUX
 SG_ FlowStatus m3 : 3|4@0+ (1,0) [0|15] "raw"  FMUX
 SG_ ConsecutiveSequence m2 : 3|4@0+ (1,0) [0|15] "raw"  FMUX
 SG_ FirstFrameLength m1 : 3|12@0+ (1,0) [0|4095] "raw"  FMUX
 SG_ SingleFrameLength m0 : 3|4@0+ (1,0) [0|15] "raw"  FMUX
 SG_ IsoTpFrameType M : 7|4@0+ (1,0) [0|15] ""  FMUX

BO_ 1916 BSI_DiagRequestToMDS: 8 BSI
 SG_ FlowPadding5 m3 : 63|8@0+ (1,0) [0|255] "raw"  MDS
 SG_ FirstData6 m1 : 63|8@0+ (1,0) [0|255] "raw"  MDS
 SG_ UnknownData7 m4 : 63|8@0+ (1,0) [0|255] "raw"  MDS
 SG_ ConsecutiveData7 m2 : 63|8@0+ (1,0) [0|255] "raw"  MDS
 SG_ SingleData7 m0 : 63|8@0+ (1,0) [0|255] "raw"  MDS
 SG_ FlowPadding4 m3 : 55|8@0+ (1,0) [0|255] "raw"  MDS
 SG_ FirstData5 m1 : 55|8@0+ (1,0) [0|255] "raw"  MDS
 SG_ UnknownData6 m4 : 55|8@0+ (1,0) [0|255] "raw"  MDS
 SG_ ConsecutiveData6 m2 : 55|8@0+ (1,0) [0|255] "raw"  MDS
 SG_ SingleData6 m0 : 55|8@0+ (1,0) [0|255] "raw"  MDS
 SG_ FlowPadding3 m3 : 47|8@0+ (1,0) [0|255] "raw"  MDS
 SG_ FirstData4 m1 : 47|8@0+ (1,0) [0|255] "raw"  MDS
 SG_ UnknownData5 m4 : 47|8@0+ (1,0) [0|255] "raw"  MDS
 SG_ ConsecutiveData5 m2 : 47|8@0+ (1,0) [0|255] "raw"  MDS
 SG_ SingleData5 m0 : 47|8@0+ (1,0) [0|255] "raw"  MDS
 SG_ FlowPadding2 m3 : 39|8@0+ (1,0) [0|255] "raw"  MDS
 SG_ FirstData3 m1 : 39|8@0+ (1,0) [0|255] "raw"  MDS
 SG_ UnknownData4 m4 : 39|8@0+ (1,0) [0|255] "raw"  MDS
 SG_ ConsecutiveData4 m2 : 39|8@0+ (1,0) [0|255] "raw"  MDS
 SG_ SingleData4 m0 : 39|8@0+ (1,0) [0|255] "raw"  MDS
 SG_ FlowPadding1 m3 : 31|8@0+ (1,0) [0|255] "raw"  MDS
 SG_ FirstData2 m1 : 31|8@0+ (1,0) [0|255] "raw"  MDS
 SG_ UnknownData3 m4 : 31|8@0+ (1,0) [0|255] "raw"  MDS
 SG_ ConsecutiveData3 m2 : 31|8@0+ (1,0) [0|255] "raw"  MDS
 SG_ SingleData3 m0 : 31|8@0+ (1,0) [0|255] "raw"  MDS
 SG_ FirstData1 m1 : 23|8@0+ (1,0) [0|255] "raw"  MDS
 SG_ UnknownData2 m4 : 23|8@0+ (1,0) [0|255] "raw"  MDS
 SG_ ConsecutiveData2 m2 : 23|8@0+ (1,0) [0|255] "raw"  MDS
 SG_ SingleData2 m0 : 23|8@0+ (1,0) [0|255] "raw"  MDS
 SG_ SeparationTimeRaw m3 : 23|8@0+ (1,0) [0|255] "raw"  MDS
 SG_ UnknownData1 m4 : 15|8@0+ (1,0) [0|255] "raw"  MDS
 SG_ ConsecutiveData1 m2 : 15|8@0+ (1,0) [0|255] "raw"  MDS
 SG_ SingleData1 m0 : 15|8@0+ (1,0) [0|255] "raw"  MDS
 SG_ BlockSize m3 : 15|8@0+ (1,0) [0|255] "raw"  MDS
 SG_ UnknownPciLow m4 : 3|4@0+ (1,0) [0|15] "raw"  MDS
 SG_ FlowStatus m3 : 3|4@0+ (1,0) [0|15] "raw"  MDS
 SG_ ConsecutiveSequence m2 : 3|4@0+ (1,0) [0|15] "raw"  MDS
 SG_ FirstFrameLength m1 : 3|12@0+ (1,0) [0|4095] "raw"  MDS
 SG_ SingleFrameLength m0 : 3|4@0+ (1,0) [0|15] "raw"  MDS
 SG_ IsoTpFrameType M : 7|4@0+ (1,0) [0|15] ""  MDS

BO_ 1917 BSI_DiagRequestToAMPLI: 8 BSI
 SG_ FlowPadding5 m3 : 63|8@0+ (1,0) [0|255] "raw"  AMPLI
 SG_ FirstData6 m1 : 63|8@0+ (1,0) [0|255] "raw"  AMPLI
 SG_ UnknownData7 m4 : 63|8@0+ (1,0) [0|255] "raw"  AMPLI
 SG_ ConsecutiveData7 m2 : 63|8@0+ (1,0) [0|255] "raw"  AMPLI
 SG_ SingleData7 m0 : 63|8@0+ (1,0) [0|255] "raw"  AMPLI
 SG_ FlowPadding4 m3 : 55|8@0+ (1,0) [0|255] "raw"  AMPLI
 SG_ FirstData5 m1 : 55|8@0+ (1,0) [0|255] "raw"  AMPLI
 SG_ UnknownData6 m4 : 55|8@0+ (1,0) [0|255] "raw"  AMPLI
 SG_ ConsecutiveData6 m2 : 55|8@0+ (1,0) [0|255] "raw"  AMPLI
 SG_ SingleData6 m0 : 55|8@0+ (1,0) [0|255] "raw"  AMPLI
 SG_ FlowPadding3 m3 : 47|8@0+ (1,0) [0|255] "raw"  AMPLI
 SG_ FirstData4 m1 : 47|8@0+ (1,0) [0|255] "raw"  AMPLI
 SG_ UnknownData5 m4 : 47|8@0+ (1,0) [0|255] "raw"  AMPLI
 SG_ ConsecutiveData5 m2 : 47|8@0+ (1,0) [0|255] "raw"  AMPLI
 SG_ SingleData5 m0 : 47|8@0+ (1,0) [0|255] "raw"  AMPLI
 SG_ FlowPadding2 m3 : 39|8@0+ (1,0) [0|255] "raw"  AMPLI
 SG_ FirstData3 m1 : 39|8@0+ (1,0) [0|255] "raw"  AMPLI
 SG_ UnknownData4 m4 : 39|8@0+ (1,0) [0|255] "raw"  AMPLI
 SG_ ConsecutiveData4 m2 : 39|8@0+ (1,0) [0|255] "raw"  AMPLI
 SG_ SingleData4 m0 : 39|8@0+ (1,0) [0|255] "raw"  AMPLI
 SG_ FlowPadding1 m3 : 31|8@0+ (1,0) [0|255] "raw"  AMPLI
 SG_ FirstData2 m1 : 31|8@0+ (1,0) [0|255] "raw"  AMPLI
 SG_ UnknownData3 m4 : 31|8@0+ (1,0) [0|255] "raw"  AMPLI
 SG_ ConsecutiveData3 m2 : 31|8@0+ (1,0) [0|255] "raw"  AMPLI
 SG_ SingleData3 m0 : 31|8@0+ (1,0) [0|255] "raw"  AMPLI
 SG_ FirstData1 m1 : 23|8@0+ (1,0) [0|255] "raw"  AMPLI
 SG_ UnknownData2 m4 : 23|8@0+ (1,0) [0|255] "raw"  AMPLI
 SG_ ConsecutiveData2 m2 : 23|8@0+ (1,0) [0|255] "raw"  AMPLI
 SG_ SingleData2 m0 : 23|8@0+ (1,0) [0|255] "raw"  AMPLI
 SG_ SeparationTimeRaw m3 : 23|8@0+ (1,0) [0|255] "raw"  AMPLI
 SG_ UnknownData1 m4 : 15|8@0+ (1,0) [0|255] "raw"  AMPLI
 SG_ ConsecutiveData1 m2 : 15|8@0+ (1,0) [0|255] "raw"  AMPLI
 SG_ SingleData1 m0 : 15|8@0+ (1,0) [0|255] "raw"  AMPLI
 SG_ BlockSize m3 : 15|8@0+ (1,0) [0|255] "raw"  AMPLI
 SG_ UnknownPciLow m4 : 3|4@0+ (1,0) [0|15] "raw"  AMPLI
 SG_ FlowStatus m3 : 3|4@0+ (1,0) [0|15] "raw"  AMPLI
 SG_ ConsecutiveSequence m2 : 3|4@0+ (1,0) [0|15] "raw"  AMPLI
 SG_ FirstFrameLength m1 : 3|12@0+ (1,0) [0|4095] "raw"  AMPLI
 SG_ SingleFrameLength m0 : 3|4@0+ (1,0) [0|15] "raw"  AMPLI
 SG_ IsoTpFrameType M : 7|4@0+ (1,0) [0|15] ""  AMPLI

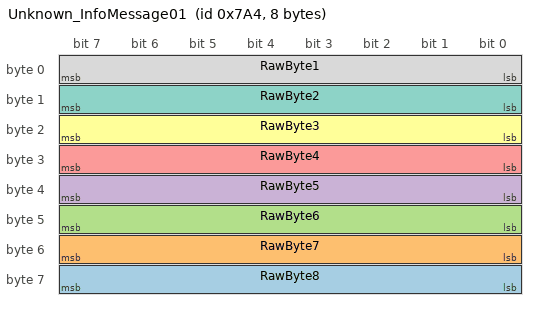
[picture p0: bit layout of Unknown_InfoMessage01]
BO_ 1956 Unknown_InfoMessage01: 8 Vector__XXX
 SG_ RawByte8 : 63|8@0+ (1,0) [0|255] "raw" Vector__XXX
 SG_ RawByte7 : 55|8@0+ (1,0) [0|255] "raw" Vector__XXX
 SG_ RawByte6 : 47|8@0+ (1,0) [0|255] "raw" Vector__XXX
 SG_ RawByte5 : 39|8@0+ (1,0) [0|255] "raw" Vector__XXX
 SG_ RawByte4 : 31|8@0+ (1,0) [0|255] "raw" Vector__XXX
 SG_ RawByte3 : 23|8@0+ (1,0) [0|255] "raw" Vector__XXX
 SG_ RawByte2 : 15|8@0+ (1,0) [0|255] "raw" Vector__XXX
 SG_ RawByte1 : 7|8@0+ (1,0) [0|255] "raw" Vector__XXX

BO_ 2047 BSI_UdsDiagnosticRequest: 8 BSI
 SG_ FlowPadding5 m3 : 63|8@0+ (1,0) [0|255] "raw"  CRT,BTEL,AMPLI,AAS,CDC,CMB,EMF,FMUX,MATT,MDS,RAD,VTH,AVP,OVIP
 SG_ FirstData6 m1 : 63|8@0+ (1,0) [0|255] "raw"  CRT,BTEL,AMPLI,AAS,CDC,CMB,EMF,FMUX,MATT,MDS,RAD,VTH,AVP,OVIP
 SG_ UnknownData7 m4 : 63|8@0+ (1,0) [0|255] "raw"  CRT,BTEL,AMPLI,AAS,CDC,CMB,EMF,FMUX,MATT,MDS,RAD,VTH,AVP,OVIP
 SG_ ConsecutiveData7 m2 : 63|8@0+ (1,0) [0|255] "raw"  CRT,BTEL,AMPLI,AAS,CDC,CMB,EMF,FMUX,MATT,MDS,RAD,VTH,AVP,OVIP
 SG_ SingleData7 m0 : 63|8@0+ (1,0) [0|255] "raw"  CRT,BTEL,AMPLI,AAS,CDC,CMB,EMF,FMUX,MATT,MDS,RAD,VTH,AVP,OVIP
 SG_ FlowPadding4 m3 : 55|8@0+ (1,0) [0|255] "raw"  CRT,BTEL,AMPLI,AAS,CDC,CMB,EMF,FMUX,MATT,MDS,RAD,VTH,AVP,OVIP
 SG_ FirstData5 m1 : 55|8@0+ (1,0) [0|255] "raw"  CRT,BTEL,AMPLI,AAS,CDC,CMB,EMF,FMUX,MATT,MDS,RAD,VTH,AVP,OVIP
 SG_ UnknownData6 m4 : 55|8@0+ (1,0) [0|255] "raw"  CRT,BTEL,AMPLI,AAS,CDC,CMB,EMF,FMUX,MATT,MDS,RAD,VTH,AVP,OVIP
 SG_ ConsecutiveData6 m2 : 55|8@0+ (1,0) [0|255] "raw"  CRT,BTEL,AMPLI,AAS,CDC,CMB,EMF,FMUX,MATT,MDS,RAD,VTH,AVP,OVIP
 SG_ SingleData6 m0 : 55|8@0+ (1,0) [0|255] "raw"  CRT,BTEL,AMPLI,AAS,CDC,CMB,EMF,FMUX,MATT,MDS,RAD,VTH,AVP,OVIP
 SG_ FlowPadding3 m3 : 47|8@0+ (1,0) [0|255] "raw"  CRT,BTEL,AMPLI,AAS,CDC,CMB,EMF,FMUX,MATT,MDS,RAD,VTH,AVP,OVIP
 SG_ FirstData4 m1 : 47|8@0+ (1,0) [0|255] "raw"  CRT,BTEL,AMPLI,AAS,CDC,CMB,EMF,FMUX,MATT,MDS,RAD,VTH,AVP,OVIP
 SG_ UnknownData5 m4 : 47|8@0+ (1,0) [0|255] "raw"  CRT,BTEL,AMPLI,AAS,CDC,CMB,EMF,FMUX,MATT,MDS,RAD,VTH,AVP,OVIP
 SG_ ConsecutiveData5 m2 : 47|8@0+ (1,0) [0|255] "raw"  CRT,BTEL,AMPLI,AAS,CDC,CMB,EMF,FMUX,MATT,MDS,RAD,VTH,AVP,OVIP
 SG_ SingleData5 m0 : 47|8@0+ (1,0) [0|255] "raw"  CRT,BTEL,AMPLI,AAS,CDC,CMB,EMF,FMUX,MATT,MDS,RAD,VTH,AVP,OVIP
 SG_ FlowPadding2 m3 : 39|8@0+ (1,0) [0|255] "raw"  CRT,BTEL,AMPLI,AAS,CDC,CMB,EMF,FMUX,MATT,MDS,RAD,VTH,AVP,OVIP
 SG_ FirstData3 m1 : 39|8@0+ (1,0) [0|255] "raw"  CRT,BTEL,AMPLI,AAS,CDC,CMB,EMF,FMUX,MATT,MDS,RAD,VTH,AVP,OVIP
 SG_ UnknownData4 m4 : 39|8@0+ (1,0) [0|255] "raw"  CRT,BTEL,AMPLI,AAS,CDC,CMB,EMF,FMUX,MATT,MDS,RAD,VTH,AVP,OVIP
 SG_ ConsecutiveData4 m2 : 39|8@0+ (1,0) [0|255] "raw"  CRT,BTEL,AMPLI,AAS,CDC,CMB,EMF,FMUX,MATT,MDS,RAD,VTH,AVP,OVIP
 SG_ SingleData4 m0 : 39|8@0+ (1,0) [0|255] "raw"  CRT,BTEL,AMPLI,AAS,CDC,CMB,EMF,FMUX,MATT,MDS,RAD,VTH,AVP,OVIP
 SG_ FlowPadding1 m3 : 31|8@0+ (1,0) [0|255] "raw"  CRT,BTEL,AMPLI,AAS,CDC,CMB,EMF,FMUX,MATT,MDS,RAD,VTH,AVP,OVIP
 SG_ FirstData2 m1 : 31|8@0+ (1,0) [0|255] "raw"  CRT,BTEL,AMPLI,AAS,CDC,CMB,EMF,FMUX,MATT,MDS,RAD,VTH,AVP,OVIP
 SG_ UnknownData3 m4 : 31|8@0+ (1,0) [0|255] "raw"  CRT,BTEL,AMPLI,AAS,CDC,CMB,EMF,FMUX,MATT,MDS,RAD,VTH,AVP,OVIP
 SG_ ConsecutiveData3 m2 : 31|8@0+ (1,0) [0|255] "raw"  CRT,BTEL,AMPLI,AAS,CDC,CMB,EMF,FMUX,MATT,MDS,RAD,VTH,AVP,OVIP
 SG_ SingleData3 m0 : 31|8@0+ (1,0) [0|255] "raw"  CRT,BTEL,AMPLI,AAS,CDC,CMB,EMF,FMUX,MATT,MDS,RAD,VTH,AVP,OVIP
 SG_ FirstData1 m1 : 23|8@0+ (1,0) [0|255] "raw"  CRT,BTEL,AMPLI,AAS,CDC,CMB,EMF,FMUX,MATT,MDS,RAD,VTH,AVP,OVIP
 SG_ UnknownData2 m4 : 23|8@0+ (1,0) [0|255] "raw"  CRT,BTEL,AMPLI,AAS,CDC,CMB,EMF,FMUX,MATT,MDS,RAD,VTH,AVP,OVIP
 SG_ ConsecutiveData2 m2 : 23|8@0+ (1,0) [0|255] "raw"  CRT,BTEL,AMPLI,AAS,CDC,CMB,EMF,FMUX,MATT,MDS,RAD,VTH,AVP,OVIP
 SG_ SingleData2 m0 : 23|8@0+ (1,0) [0|255] "raw"  CRT,BTEL,AMPLI,AAS,CDC,CMB,EMF,FMUX,MATT,MDS,RAD,VTH,AVP,OVIP
 SG_ SeparationTimeRaw m3 : 23|8@0+ (1,0) [0|255] "raw"  CRT,BTEL,AMPLI,AAS,CDC,CMB,EMF,FMUX,MATT,MDS,RAD,VTH,AVP,OVIP
 SG_ UnknownData1 m4 : 15|8@0+ (1,0) [0|255] "raw"  CRT,BTEL,AMPLI,AAS,CDC,CMB,EMF,FMUX,MATT,MDS,RAD,VTH,AVP,OVIP
 SG_ ConsecutiveData1 m2 : 15|8@0+ (1,0) [0|255] "raw"  CRT,BTEL,AMPLI,AAS,CDC,CMB,EMF,FMUX,MATT,MDS,RAD,VTH,AVP,OVIP
 SG_ SingleData1 m0 : 15|8@0+ (1,0) [0|255] "raw"  CRT,BTEL,AMPLI,AAS,CDC,CMB,EMF,FMUX,MATT,MDS,RAD,VTH,AVP,OVIP
 SG_ BlockSize m3 : 15|8@0+ (1,0) [0|255] "raw"  CRT,BTEL,AMPLI,AAS,CDC,CMB,EMF,FMUX,MATT,MDS,RAD,VTH,AVP,OVIP
 SG_ UnknownPciLow m4 : 3|4@0+ (1,0) [0|15] "raw"  CRT,BTEL,AMPLI,AAS,CDC,CMB,EMF,FMUX,MATT,MDS,RAD,VTH,AVP,OVIP
 SG_ FlowStatus m3 : 3|4@0+ (1,0) [0|15] "raw"  CRT,BTEL,AMPLI,AAS,CDC,CMB,EMF,FMUX,MATT,MDS,RAD,VTH,AVP,OVIP
 SG_ ConsecutiveSequence m2 : 3|4@0+ (1,0) [0|15] "raw"  CRT,BTEL,AMPLI,AAS,CDC,CMB,EMF,FMUX,MATT,MDS,RAD,VTH,AVP,OVIP
 SG_ FirstFrameLength m1 : 3|12@0+ (1,0) [0|4095] "raw"  CRT,BTEL,AMPLI,AAS,CDC,CMB,EMF,FMUX,MATT,MDS,RAD,VTH,AVP,OVIP
 SG_ SingleFrameLength m0 : 3|4@0+ (1,0) [0|15] "raw"  CRT,BTEL,AMPLI,AAS,CDC,CMB,EMF,FMUX,MATT,MDS,RAD,VTH,AVP,OVIP
 SG_ IsoTpFrameType M : 7|4@0+ (1,0) [0|15] ""  CRT,BTEL,AMPLI,AAS,CDC,CMB,EMF,FMUX,MATT,MDS,RAD,VTH,AVP,OVIP

BO_ 2415919104 BSI_ArtivAndHybridStatus2: 8 BSI
 SG_ LpaHaloDisplay : 56|1@0+ (1,0) [0|1] ""  BTEL,CMB,MATT,MDS,OVIP,ICSV,VTH
 SG_ ZtepPowerRatio : 63|7@0+ (1,0) [0|100] "%"  BTEL,CMB,MATT,MDS,OVIP,ICSV,VTH
 SG_ DaaLateralControlState : 48|1@0+ (1,0) [0|1] ""  BTEL,CMB,MATT,MDS,OVIP,ICSV,VTH
 SG_ LpaReadyWhenSelected : 49|1@0+ (1,0) [0|1] ""  BTEL,CMB,MATT,MDS,OVIP,ICSV,VTH
 SG_ LpaStateStatus : 51|2@0+ (1,0) [0|3] ""  BTEL,CMB,MATT,MDS,OVIP,ICSV,VTH
 SG_ PlugIndicatorLampRequest : 53|2@0+ (1,0) [0|3] ""  BTEL,CMB,MATT,MDS,OVIP,ICSV,VTH
 SG_ LkaStateStatus : 55|2@0+ (1,0) [0|3] ""  BTEL,CMB,MATT,MDS,OVIP,ICSV,VTH
 SG_ LkaLeftLineStatus : 41|2@0+ (1,0) [0|3] ""  BTEL,CMB,MATT,MDS,OVIP,ICSV,VTH
 SG_ LkaRightLineStatus : 43|2@0+ (1,0) [0|3] ""  BTEL,CMB,MATT,MDS,OVIP,ICSV,VTH
 SG_ DaaLateralControlLevel : 47|4@0+ (1,0) [0|15] ""  BTEL,CMB,MATT,MDS,OVIP,ICSV,VTH
 SG_ HybridPowerTraction : 24|9@0+ (0.5,-50) [-50|200] "W"  BTEL,CMB,MATT,MDS,OVIP,ICSV,VTH
 SG_ PowerBatteryHt : 31|7@0+ (1,-50) [-50|50] "kW"  BTEL,CMB,MATT,MDS,OVIP,ICSV,VTH
 SG_ TivTarget : 23|8@0+ (0.1,0) [0|25.3] "s"  BTEL,CMB,MATT,MDS,OVIP,ICSV,VTH
 SG_ TivSetpoint : 15|8@0+ (0.1,0) [0|25.3] "s"  BTEL,CMB,MATT,MDS,OVIP,ICSV,VTH
 SG_ RawBits7_7 : 0|1@0+ (1,0) [0|1] "raw" Vector__XXX
 SG_ ArtivTargetDetected : 1|1@0+ (1,0) [0|1] ""  BTEL,CMB,MATT,MDS,OVIP,ICSV,VTH
 SG_ ArtivAlertAdjustment : 2|1@0+ (1,0) [0|1] ""  BTEL,CMB,MATT,MDS,OVIP,ICSV,VTH
 SG_ ArtivAlert : 3|1@0+ (1,0) [0|1] ""  BTEL,CMB,MATT,MDS,OVIP,ICSV,VTH
 SG_ IhmArtivStatus : 5|2@0+ (1,0) [0|3] ""  BTEL,CMB,MATT,MDS,OVIP,ICSV,VTH
 SG_ ArtivSelectionStatus : 7|2@0+ (1,0) [0|3] ""  BTEL,CMB,MATT,MDS,OVIP,ICSV,VTH

BO_TX_BU_ 1904 : BSI,MDS;
BO_TX_BU_ 1905 : BSI,MDS;
BO_TX_BU_ 1906 : BSI,MDS;
BO_TX_BU_ 1907 : BSI,MDS;
BO_TX_BU_ 1910 : BSI,MDS;
BO_TX_BU_ 1915 : BSI,MDS;
BO_TX_BU_ 1917 : BSI,MDS;
BO_TX_BU_ 2047 : BSI,ICSV;
CM_ BO_ 1894 "DATABASE_CANDIDATE: physical interpretation unverified; capture/layout evidence reported separately. INFO-DIV CAN, 125000 bit/s; CAN ID 0x766. PSA-RE title: FAULT_LOG_HCU2. Diagnostic session request frame addressed to this module Source: https://github.com/prototux/PSA-RE/blob/67f7581e7622410efdbb29c7eda3b86982b9b450/buses/AEE2010.full/LS.INFO-DIV/766.yml. Source sender alternatives: BSI; physical TX/gateway forwarding not verified. WIRE ISO-TP ONLY: normal addressing candidate, maximum Classical CAN DLC 8; actual DLC may be shorter. Data includes padding. No reassembly, text, DID or application-layer decoding. Original application layouts are preserved in source JSON; do not decode them at wire offsets. ";
CM_ SG_ 1894 FlowPadding5 "TRANSPORT_CANDIDATE: normal-addressing ISO-TP. PSA-RE bits 8.7-8.0. ";
CM_ SG_ 1894 FirstData6 "TRANSPORT_CANDIDATE: normal-addressing ISO-TP. PSA-RE bits 8.7-8.0. ";
CM_ SG_ 1894 UnknownData7 "TRANSPORT_CANDIDATE: normal-addressing ISO-TP. PSA-RE bits 8.7-8.0. ";
CM_ SG_ 1894 ConsecutiveData7 "TRANSPORT_CANDIDATE: normal-addressing ISO-TP. PSA-RE bits 8.7-8.0. ";
CM_ SG_ 1894 SingleData7 "TRANSPORT_CANDIDATE: normal-addressing ISO-TP. PSA-RE bits 8.7-8.0. ";
CM_ SG_ 1894 FlowPadding4 "TRANSPORT_CANDIDATE: normal-addressing ISO-TP. PSA-RE bits 7.7-7.0. ";
CM_ SG_ 1894 FirstData5 "TRANSPORT_CANDIDATE: normal-addressing ISO-TP. PSA-RE bits 7.7-7.0. ";
CM_ SG_ 1894 UnknownData6 "TRANSPORT_CANDIDATE: normal-addressing ISO-TP. PSA-RE bits 7.7-7.0. ";
CM_ SG_ 1894 ConsecutiveData6 "TRANSPORT_CANDIDATE: normal-addressing ISO-TP. PSA-RE bits 7.7-7.0. ";
CM_ SG_ 1894 SingleData6 "TRANSPORT_CANDIDATE: normal-addressing ISO-TP. PSA-RE bits 7.7-7.0. ";
CM_ SG_ 1894 FlowPadding3 "TRANSPORT_CANDIDATE: normal-addressing ISO-TP. PSA-RE bits 6.7-6.0. ";
CM_ SG_ 1894 FirstData4 "TRANSPORT_CANDIDATE: normal-addressing ISO-TP. PSA-RE bits 6.7-6.0. ";
CM_ SG_ 1894 UnknownData5 "TRANSPORT_CANDIDATE: normal-addressing ISO-TP. PSA-RE bits 6.7-6.0. ";
CM_ SG_ 1894 ConsecutiveData5 "TRANSPORT_CANDIDATE: normal-addressing ISO-TP. PSA-RE bits 6.7-6.0. ";
CM_ SG_ 1894 SingleData5 "TRANSPORT_CANDIDATE: normal-addressing ISO-TP. PSA-RE bits 6.7-6.0. ";
CM_ SG_ 1894 FlowPadding2 "TRANSPORT_CANDIDATE: normal-addressing ISO-TP. PSA-RE bits 5.7-5.0. ";
CM_ SG_ 1894 FirstData3 "TRANSPORT_CANDIDATE: normal-addressing ISO-TP. PSA-RE bits 5.7-5.0. ";
CM_ SG_ 1894 UnknownData4 "TRANSPORT_CANDIDATE: normal-addressing ISO-TP. PSA-RE bits 5.7-5.0. ";
CM_ SG_ 1894 ConsecutiveData4 "TRANSPORT_CANDIDATE: normal-addressing ISO-TP. PSA-RE bits 5.7-5.0. ";
CM_ SG_ 1894 SingleData4 "TRANSPORT_CANDIDATE: normal-addressing ISO-TP. PSA-RE bits 5.7-5.0. ";
CM_ SG_ 1894 FlowPadding1 "TRANSPORT_CANDIDATE: normal-addressing ISO-TP. PSA-RE bits 4.7-4.0. ";
CM_ SG_ 1894 FirstData2 "TRANSPORT_CANDIDATE: normal-addressing ISO-TP. PSA-RE bits 4.7-4.0. ";
CM_ SG_ 1894 UnknownData3 "TRANSPORT_CANDIDATE: normal-addressing ISO-TP. PSA-RE bits 4.7-4.0. ";
CM_ SG_ 1894 ConsecutiveData3 "TRANSPORT_CANDIDATE: normal-addressing ISO-TP. PSA-RE bits 4.7-4.0. ";
CM_ SG_ 1894 SingleData3 "TRANSPORT_CANDIDATE: normal-addressing ISO-TP. PSA-RE bits 4.7-4.0. ";
CM_ SG_ 1894 FirstData1 "TRANSPORT_CANDIDATE: normal-addressing ISO-TP. PSA-RE bits 3.7-3.0. ";
CM_ SG_ 1894 UnknownData2 "TRANSPORT_CANDIDATE: normal-addressing ISO-TP. PSA-RE bits 3.7-3.0. ";
CM_ SG_ 1894 ConsecutiveData2 "TRANSPORT_CANDIDATE: normal-addressing ISO-TP. PSA-RE bits 3.7-3.0. ";
CM_ SG_ 1894 SingleData2 "TRANSPORT_CANDIDATE: normal-addressing ISO-TP. PSA-RE bits 3.7-3.0. ";
CM_ SG_ 1894 SeparationTimeRaw "TRANSPORT_CANDIDATE: normal-addressing ISO-TP. PSA-RE bits 3.7-3.0. Raw STmin code; 0xF1..0xF9 are not milliseconds.";
CM_ SG_ 1894 UnknownData1 "TRANSPORT_CANDIDATE: normal-addressing ISO-TP. PSA-RE bits 2.7-2.0. ";
CM_ SG_ 1894 ConsecutiveData1 "TRANSPORT_CANDIDATE: normal-addressing ISO-TP. PSA-RE bits 2.7-2.0. ";
CM_ SG_ 1894 SingleData1 "TRANSPORT_CANDIDATE: normal-addressing ISO-TP. PSA-RE bits 2.7-2.0. ";
CM_ SG_ 1894 BlockSize "TRANSPORT_CANDIDATE: normal-addressing ISO-TP. PSA-RE bits 2.7-2.0. ";
CM_ SG_ 1894 UnknownPciLow "TRANSPORT_CANDIDATE: normal-addressing ISO-TP. PSA-RE bits 1.3-1.0. ";
CM_ SG_ 1894 FlowStatus "TRANSPORT_CANDIDATE: normal-addressing ISO-TP. PSA-RE bits 1.3-1.0. ";
CM_ SG_ 1894 ConsecutiveSequence "TRANSPORT_CANDIDATE: normal-addressing ISO-TP. PSA-RE bits 1.3-1.0. ";
CM_ SG_ 1894 FirstFrameLength "TRANSPORT_CANDIDATE: normal-addressing ISO-TP. PSA-RE bits 1.3-2.0. 12-bit declared PDU length; not a reassembled value.";
CM_ SG_ 1894 SingleFrameLength "TRANSPORT_CANDIDATE: normal-addressing ISO-TP. PSA-RE bits 1.3-1.0. Declared data length; not a validity check.";
CM_ SG_ 1894 IsoTpFrameType "TRANSPORT_CANDIDATE: normal-addressing ISO-TP. PSA-RE bits 1.7-1.4. PCI high nibble; normal addressing candidate.";
CM_ BO_ 1899 "DATABASE_CANDIDATE: physical interpretation unverified; capture/layout evidence reported separately. INFO-DIV CAN, 125000 bit/s; CAN ID 0x76B. PSA-RE title: CATVM_DIAG_REQUEST. Diagnostic request addressed to the CATVM ECU. Source: https://github.com/prototux/PSA-RE/blob/67f7581e7622410efdbb29c7eda3b86982b9b450/buses/AEE2010.full/LS.INFO-DIV/76B.yml. Source sender alternatives: MDS; physical TX/gateway forwarding not verified. WIRE ISO-TP ONLY: normal addressing candidate, maximum Classical CAN DLC 8; actual DLC may be shorter. Data includes padding. No reassembly, text, DID or application-layer decoding. Original application layouts are preserved in source JSON; do not decode them at wire offsets. ";
CM_ SG_ 1899 FlowPadding5 "TRANSPORT_CANDIDATE: normal-addressing ISO-TP. PSA-RE bits 8.7-8.0. ";
CM_ SG_ 1899 FirstData6 "TRANSPORT_CANDIDATE: normal-addressing ISO-TP. PSA-RE bits 8.7-8.0. ";
CM_ SG_ 1899 UnknownData7 "TRANSPORT_CANDIDATE: normal-addressing ISO-TP. PSA-RE bits 8.7-8.0. ";
CM_ SG_ 1899 ConsecutiveData7 "TRANSPORT_CANDIDATE: normal-addressing ISO-TP. PSA-RE bits 8.7-8.0. ";
CM_ SG_ 1899 SingleData7 "TRANSPORT_CANDIDATE: normal-addressing ISO-TP. PSA-RE bits 8.7-8.0. ";
CM_ SG_ 1899 FlowPadding4 "TRANSPORT_CANDIDATE: normal-addressing ISO-TP. PSA-RE bits 7.7-7.0. ";
CM_ SG_ 1899 FirstData5 "TRANSPORT_CANDIDATE: normal-addressing ISO-TP. PSA-RE bits 7.7-7.0. ";
CM_ SG_ 1899 UnknownData6 "TRANSPORT_CANDIDATE: normal-addressing ISO-TP. PSA-RE bits 7.7-7.0. ";
CM_ SG_ 1899 ConsecutiveData6 "TRANSPORT_CANDIDATE: normal-addressing ISO-TP. PSA-RE bits 7.7-7.0. ";
CM_ SG_ 1899 SingleData6 "TRANSPORT_CANDIDATE: normal-addressing ISO-TP. PSA-RE bits 7.7-7.0. ";
CM_ SG_ 1899 FlowPadding3 "TRANSPORT_CANDIDATE: normal-addressing ISO-TP. PSA-RE bits 6.7-6.0. ";
CM_ SG_ 1899 FirstData4 "TRANSPORT_CANDIDATE: normal-addressing ISO-TP. PSA-RE bits 6.7-6.0. ";
CM_ SG_ 1899 UnknownData5 "TRANSPORT_CANDIDATE: normal-addressing ISO-TP. PSA-RE bits 6.7-6.0. ";
CM_ SG_ 1899 ConsecutiveData5 "TRANSPORT_CANDIDATE: normal-addressing ISO-TP. PSA-RE bits 6.7-6.0. ";
CM_ SG_ 1899 SingleData5 "TRANSPORT_CANDIDATE: normal-addressing ISO-TP. PSA-RE bits 6.7-6.0. ";
CM_ SG_ 1899 FlowPadding2 "TRANSPORT_CANDIDATE: normal-addressing ISO-TP. PSA-RE bits 5.7-5.0. ";
CM_ SG_ 1899 FirstData3 "TRANSPORT_CANDIDATE: normal-addressing ISO-TP. PSA-RE bits 5.7-5.0. ";
CM_ SG_ 1899 UnknownData4 "TRANSPORT_CANDIDATE: normal-addressing ISO-TP. PSA-RE bits 5.7-5.0. ";
CM_ SG_ 1899 ConsecutiveData4 "TRANSPORT_CANDIDATE: normal-addressing ISO-TP. PSA-RE bits 5.7-5.0. ";
CM_ SG_ 1899 SingleData4 "TRANSPORT_CANDIDATE: normal-addressing ISO-TP. PSA-RE bits 5.7-5.0. ";
CM_ SG_ 1899 FlowPadding1 "TRANSPORT_CANDIDATE: normal-addressing ISO-TP. PSA-RE bits 4.7-4.0. ";
CM_ SG_ 1899 FirstData2 "TRANSPORT_CANDIDATE: normal-addressing ISO-TP. PSA-RE bits 4.7-4.0. ";
CM_ SG_ 1899 UnknownData3 "TRANSPORT_CANDIDATE: normal-addressing ISO-TP. PSA-RE bits 4.7-4.0. ";
CM_ SG_ 1899 ConsecutiveData3 "TRANSPORT_CANDIDATE: normal-addressing ISO-TP. PSA-RE bits 4.7-4.0. ";
CM_ SG_ 1899 SingleData3 "TRANSPORT_CANDIDATE: normal-addressing ISO-TP. PSA-RE bits 4.7-4.0. ";
CM_ SG_ 1899 FirstData1 "TRANSPORT_CANDIDATE: normal-addressing ISO-TP. PSA-RE bits 3.7-3.0. ";
CM_ SG_ 1899 UnknownData2 "TRANSPORT_CANDIDATE: normal-addressing ISO-TP. PSA-RE bits 3.7-3.0. ";
CM_ SG_ 1899 ConsecutiveData2 "TRANSPORT_CANDIDATE: normal-addressing ISO-TP. PSA-RE bits 3.7-3.0. ";
CM_ SG_ 1899 SingleData2 "TRANSPORT_CANDIDATE: normal-addressing ISO-TP. PSA-RE bits 3.7-3.0. ";
CM_ SG_ 1899 SeparationTimeRaw "TRANSPORT_CANDIDATE: normal-addressing ISO-TP. PSA-RE bits 3.7-3.0. Raw STmin code; 0xF1..0xF9 are not milliseconds.";
CM_ SG_ 1899 UnknownData1 "TRANSPORT_CANDIDATE: normal-addressing ISO-TP. PSA-RE bits 2.7-2.0. ";
CM_ SG_ 1899 ConsecutiveData1 "TRANSPORT_CANDIDATE: normal-addressing ISO-TP. PSA-RE bits 2.7-2.0. ";
CM_ SG_ 1899 SingleData1 "TRANSPORT_CANDIDATE: normal-addressing ISO-TP. PSA-RE bits 2.7-2.0. ";
CM_ SG_ 1899 BlockSize "TRANSPORT_CANDIDATE: normal-addressing ISO-TP. PSA-RE bits 2.7-2.0. ";
CM_ SG_ 1899 UnknownPciLow "TRANSPORT_CANDIDATE: normal-addressing ISO-TP. PSA-RE bits 1.3-1.0. ";
CM_ SG_ 1899 FlowStatus "TRANSPORT_CANDIDATE: normal-addressing ISO-TP. PSA-RE bits 1.3-1.0. ";
CM_ SG_ 1899 ConsecutiveSequence "TRANSPORT_CANDIDATE: normal-addressing ISO-TP. PSA-RE bits 1.3-1.0. ";
CM_ SG_ 1899 FirstFrameLength "TRANSPORT_CANDIDATE: normal-addressing ISO-TP. PSA-RE bits 1.3-2.0. 12-bit declared PDU length; not a reassembled value.";
CM_ SG_ 1899 SingleFrameLength "TRANSPORT_CANDIDATE: normal-addressing ISO-TP. PSA-RE bits 1.3-1.0. Declared data length; not a validity check.";
CM_ SG_ 1899 IsoTpFrameType "TRANSPORT_CANDIDATE: normal-addressing ISO-TP. PSA-RE bits 1.7-1.4. PCI high nibble; normal addressing candidate.";
CM_ BO_ 1900 "DATABASE_CANDIDATE: physical interpretation unverified; capture/layout evidence reported separately. INFO-DIV CAN, 125000 bit/s; CAN ID 0x76C. PSA-RE title: BRQ_DIAG_REQUEST. Diagnostic request addressed to the BRQ ECU. Source: https://github.com/prototux/PSA-RE/blob/67f7581e7622410efdbb29c7eda3b86982b9b450/buses/AEE2010.full/LS.INFO-DIV/76C.yml. Source sender alternatives: MDS; physical TX/gateway forwarding not verified. WIRE ISO-TP ONLY: normal addressing candidate, maximum Classical CAN DLC 8; actual DLC may be shorter. Data includes padding. No reassembly, text, DID or application-layer decoding. Original application layouts are preserved in source JSON; do not decode them at wire offsets. ";
CM_ SG_ 1900 FlowPadding5 "TRANSPORT_CANDIDATE: normal-addressing ISO-TP. PSA-RE bits 8.7-8.0. ";
CM_ SG_ 1900 FirstData6 "TRANSPORT_CANDIDATE: normal-addressing ISO-TP. PSA-RE bits 8.7-8.0. ";
CM_ SG_ 1900 UnknownData7 "TRANSPORT_CANDIDATE: normal-addressing ISO-TP. PSA-RE bits 8.7-8.0. ";
CM_ SG_ 1900 ConsecutiveData7 "TRANSPORT_CANDIDATE: normal-addressing ISO-TP. PSA-RE bits 8.7-8.0. ";
CM_ SG_ 1900 SingleData7 "TRANSPORT_CANDIDATE: normal-addressing ISO-TP. PSA-RE bits 8.7-8.0. ";
CM_ SG_ 1900 FlowPadding4 "TRANSPORT_CANDIDATE: normal-addressing ISO-TP. PSA-RE bits 7.7-7.0. ";
CM_ SG_ 1900 FirstData5 "TRANSPORT_CANDIDATE: normal-addressing ISO-TP. PSA-RE bits 7.7-7.0. ";
CM_ SG_ 1900 UnknownData6 "TRANSPORT_CANDIDATE: normal-addressing ISO-TP. PSA-RE bits 7.7-7.0. ";
CM_ SG_ 1900 ConsecutiveData6 "TRANSPORT_CANDIDATE: normal-addressing ISO-TP. PSA-RE bits 7.7-7.0. ";
CM_ SG_ 1900 SingleData6 "TRANSPORT_CANDIDATE: normal-addressing ISO-TP. PSA-RE bits 7.7-7.0. ";
CM_ SG_ 1900 FlowPadding3 "TRANSPORT_CANDIDATE: normal-addressing ISO-TP. PSA-RE bits 6.7-6.0. ";
CM_ SG_ 1900 FirstData4 "TRANSPORT_CANDIDATE: normal-addressing ISO-TP. PSA-RE bits 6.7-6.0. ";
CM_ SG_ 1900 UnknownData5 "TRANSPORT_CANDIDATE: normal-addressing ISO-TP. PSA-RE bits 6.7-6.0. ";
CM_ SG_ 1900 ConsecutiveData5 "TRANSPORT_CANDIDATE: normal-addressing ISO-TP. PSA-RE bits 6.7-6.0. ";
CM_ SG_ 1900 SingleData5 "TRANSPORT_CANDIDATE: normal-addressing ISO-TP. PSA-RE bits 6.7-6.0. ";
CM_ SG_ 1900 FlowPadding2 "TRANSPORT_CANDIDATE: normal-addressing ISO-TP. PSA-RE bits 5.7-5.0. ";
CM_ SG_ 1900 FirstData3 "TRANSPORT_CANDIDATE: normal-addressing ISO-TP. PSA-RE bits 5.7-5.0. ";
CM_ SG_ 1900 UnknownData4 "TRANSPORT_CANDIDATE: normal-addressing ISO-TP. PSA-RE bits 5.7-5.0. ";
CM_ SG_ 1900 ConsecutiveData4 "TRANSPORT_CANDIDATE: normal-addressing ISO-TP. PSA-RE bits 5.7-5.0. ";
CM_ SG_ 1900 SingleData4 "TRANSPORT_CANDIDATE: normal-addressing ISO-TP. PSA-RE bits 5.7-5.0. ";
CM_ SG_ 1900 FlowPadding1 "TRANSPORT_CANDIDATE: normal-addressing ISO-TP. PSA-RE bits 4.7-4.0. ";
CM_ SG_ 1900 FirstData2 "TRANSPORT_CANDIDATE: normal-addressing ISO-TP. PSA-RE bits 4.7-4.0. ";
CM_ SG_ 1900 UnknownData3 "TRANSPORT_CANDIDATE: normal-addressing ISO-TP. PSA-RE bits 4.7-4.0. ";
CM_ SG_ 1900 ConsecutiveData3 "TRANSPORT_CANDIDATE: normal-addressing ISO-TP. PSA-RE bits 4.7-4.0. ";
CM_ SG_ 1900 SingleData3 "TRANSPORT_CANDIDATE: normal-addressing ISO-TP. PSA-RE bits 4.7-4.0. ";
CM_ SG_ 1900 FirstData1 "TRANSPORT_CANDIDATE: normal-addressing ISO-TP. PSA-RE bits 3.7-3.0. ";
CM_ SG_ 1900 UnknownData2 "TRANSPORT_CANDIDATE: normal-addressing ISO-TP. PSA-RE bits 3.7-3.0. ";
CM_ SG_ 1900 ConsecutiveData2 "TRANSPORT_CANDIDATE: normal-addressing ISO-TP. PSA-RE bits 3.7-3.0. ";
CM_ SG_ 1900 SingleData2 "TRANSPORT_CANDIDATE: normal-addressing ISO-TP. PSA-RE bits 3.7-3.0. ";
CM_ SG_ 1900 SeparationTimeRaw "TRANSPORT_CANDIDATE: normal-addressing ISO-TP. PSA-RE bits 3.7-3.0. Raw STmin code; 0xF1..0xF9 are not milliseconds.";
CM_ SG_ 1900 UnknownData1 "TRANSPORT_CANDIDATE: normal-addressing ISO-TP. PSA-RE bits 2.7-2.0. ";
CM_ SG_ 1900 ConsecutiveData1 "TRANSPORT_CANDIDATE: normal-addressing ISO-TP. PSA-RE bits 2.7-2.0. ";
CM_ SG_ 1900 SingleData1 "TRANSPORT_CANDIDATE: normal-addressing ISO-TP. PSA-RE bits 2.7-2.0. ";
CM_ SG_ 1900 BlockSize "TRANSPORT_CANDIDATE: normal-addressing ISO-TP. PSA-RE bits 2.7-2.0. ";
CM_ SG_ 1900 UnknownPciLow "TRANSPORT_CANDIDATE: normal-addressing ISO-TP. PSA-RE bits 1.3-1.0. ";
CM_ SG_ 1900 FlowStatus "TRANSPORT_CANDIDATE: normal-addressing ISO-TP. PSA-RE bits 1.3-1.0. ";
CM_ SG_ 1900 ConsecutiveSequence "TRANSPORT_CANDIDATE: normal-addressing ISO-TP. PSA-RE bits 1.3-1.0. ";
CM_ SG_ 1900 FirstFrameLength "TRANSPORT_CANDIDATE: normal-addressing ISO-TP. PSA-RE bits 1.3-2.0. 12-bit declared PDU length; not a reassembled value.";
CM_ SG_ 1900 SingleFrameLength "TRANSPORT_CANDIDATE: normal-addressing ISO-TP. PSA-RE bits 1.3-1.0. Declared data length; not a validity check.";
CM_ SG_ 1900 IsoTpFrameType "TRANSPORT_CANDIDATE: normal-addressing ISO-TP. PSA-RE bits 1.7-1.4. PCI high nibble; normal addressing candidate.";
CM_ BO_ 1901 "DATABASE_CANDIDATE: physical interpretation unverified; capture/layout evidence reported separately. INFO-DIV CAN, 125000 bit/s; CAN ID 0x76D. PSA-RE title: FAULT_LOG_BRAKE_ECU. Diagnostic request addressed to the CLV ECU. Source: https://github.com/prototux/PSA-RE/blob/67f7581e7622410efdbb29c7eda3b86982b9b450/buses/AEE2010.full/LS.INFO-DIV/76D.yml. Source sender alternatives: MDS; physical TX/gateway forwarding not verified. WIRE ISO-TP ONLY: normal addressing candidate, maximum Classical CAN DLC 8; actual DLC may be shorter. Data includes padding. No reassembly, text, DID or application-layer decoding. Original application layouts are preserved in source JSON; do not decode them at wire offsets. ";
CM_ SG_ 1901 FlowPadding5 "TRANSPORT_CANDIDATE: normal-addressing ISO-TP. PSA-RE bits 8.7-8.0. ";
CM_ SG_ 1901 FirstData6 "TRANSPORT_CANDIDATE: normal-addressing ISO-TP. PSA-RE bits 8.7-8.0. ";
CM_ SG_ 1901 UnknownData7 "TRANSPORT_CANDIDATE: normal-addressing ISO-TP. PSA-RE bits 8.7-8.0. ";
CM_ SG_ 1901 ConsecutiveData7 "TRANSPORT_CANDIDATE: normal-addressing ISO-TP. PSA-RE bits 8.7-8.0. ";
CM_ SG_ 1901 SingleData7 "TRANSPORT_CANDIDATE: normal-addressing ISO-TP. PSA-RE bits 8.7-8.0. ";
CM_ SG_ 1901 FlowPadding4 "TRANSPORT_CANDIDATE: normal-addressing ISO-TP. PSA-RE bits 7.7-7.0. ";
CM_ SG_ 1901 FirstData5 "TRANSPORT_CANDIDATE: normal-addressing ISO-TP. PSA-RE bits 7.7-7.0. ";
CM_ SG_ 1901 UnknownData6 "TRANSPORT_CANDIDATE: normal-addressing ISO-TP. PSA-RE bits 7.7-7.0. ";
CM_ SG_ 1901 ConsecutiveData6 "TRANSPORT_CANDIDATE: normal-addressing ISO-TP. PSA-RE bits 7.7-7.0. ";
CM_ SG_ 1901 SingleData6 "TRANSPORT_CANDIDATE: normal-addressing ISO-TP. PSA-RE bits 7.7-7.0. ";
CM_ SG_ 1901 FlowPadding3 "TRANSPORT_CANDIDATE: normal-addressing ISO-TP. PSA-RE bits 6.7-6.0. ";
CM_ SG_ 1901 FirstData4 "TRANSPORT_CANDIDATE: normal-addressing ISO-TP. PSA-RE bits 6.7-6.0. ";
CM_ SG_ 1901 UnknownData5 "TRANSPORT_CANDIDATE: normal-addressing ISO-TP. PSA-RE bits 6.7-6.0. ";
CM_ SG_ 1901 ConsecutiveData5 "TRANSPORT_CANDIDATE: normal-addressing ISO-TP. PSA-RE bits 6.7-6.0. ";
CM_ SG_ 1901 SingleData5 "TRANSPORT_CANDIDATE: normal-addressing ISO-TP. PSA-RE bits 6.7-6.0. ";
CM_ SG_ 1901 FlowPadding2 "TRANSPORT_CANDIDATE: normal-addressing ISO-TP. PSA-RE bits 5.7-5.0. ";
CM_ SG_ 1901 FirstData3 "TRANSPORT_CANDIDATE: normal-addressing ISO-TP. PSA-RE bits 5.7-5.0. ";
CM_ SG_ 1901 UnknownData4 "TRANSPORT_CANDIDATE: normal-addressing ISO-TP. PSA-RE bits 5.7-5.0. ";
CM_ SG_ 1901 ConsecutiveData4 "TRANSPORT_CANDIDATE: normal-addressing ISO-TP. PSA-RE bits 5.7-5.0. ";
CM_ SG_ 1901 SingleData4 "TRANSPORT_CANDIDATE: normal-addressing ISO-TP. PSA-RE bits 5.7-5.0. ";
CM_ SG_ 1901 FlowPadding1 "TRANSPORT_CANDIDATE: normal-addressing ISO-TP. PSA-RE bits 4.7-4.0. ";
CM_ SG_ 1901 FirstData2 "TRANSPORT_CANDIDATE: normal-addressing ISO-TP. PSA-RE bits 4.7-4.0. ";
CM_ SG_ 1901 UnknownData3 "TRANSPORT_CANDIDATE: normal-addressing ISO-TP. PSA-RE bits 4.7-4.0. ";
CM_ SG_ 1901 ConsecutiveData3 "TRANSPORT_CANDIDATE: normal-addressing ISO-TP. PSA-RE bits 4.7-4.0. ";
CM_ SG_ 1901 SingleData3 "TRANSPORT_CANDIDATE: normal-addressing ISO-TP. PSA-RE bits 4.7-4.0. ";
CM_ SG_ 1901 FirstData1 "TRANSPORT_CANDIDATE: normal-addressing ISO-TP. PSA-RE bits 3.7-3.0. ";
CM_ SG_ 1901 UnknownData2 "TRANSPORT_CANDIDATE: normal-addressing ISO-TP. PSA-RE bits 3.7-3.0. ";
CM_ SG_ 1901 ConsecutiveData2 "TRANSPORT_CANDIDATE: normal-addressing ISO-TP. PSA-RE bits 3.7-3.0. ";
CM_ SG_ 1901 SingleData2 "TRANSPORT_CANDIDATE: normal-addressing ISO-TP. PSA-RE bits 3.7-3.0. ";
CM_ SG_ 1901 SeparationTimeRaw "TRANSPORT_CANDIDATE: normal-addressing ISO-TP. PSA-RE bits 3.7-3.0. Raw STmin code; 0xF1..0xF9 are not milliseconds.";
CM_ SG_ 1901 UnknownData1 "TRANSPORT_CANDIDATE: normal-addressing ISO-TP. PSA-RE bits 2.7-2.0. ";
CM_ SG_ 1901 ConsecutiveData1 "TRANSPORT_CANDIDATE: normal-addressing ISO-TP. PSA-RE bits 2.7-2.0. ";
CM_ SG_ 1901 SingleData1 "TRANSPORT_CANDIDATE: normal-addressing ISO-TP. PSA-RE bits 2.7-2.0. ";
CM_ SG_ 1901 BlockSize "TRANSPORT_CANDIDATE: normal-addressing ISO-TP. PSA-RE bits 2.7-2.0. ";
CM_ SG_ 1901 UnknownPciLow "TRANSPORT_CANDIDATE: normal-addressing ISO-TP. PSA-RE bits 1.3-1.0. ";
CM_ SG_ 1901 FlowStatus "TRANSPORT_CANDIDATE: normal-addressing ISO-TP. PSA-RE bits 1.3-1.0. ";
CM_ SG_ 1901 ConsecutiveSequence "TRANSPORT_CANDIDATE: normal-addressing ISO-TP. PSA-RE bits 1.3-1.0. ";
CM_ SG_ 1901 FirstFrameLength "TRANSPORT_CANDIDATE: normal-addressing ISO-TP. PSA-RE bits 1.3-2.0. 12-bit declared PDU length; not a reassembled value.";
CM_ SG_ 1901 SingleFrameLength "TRANSPORT_CANDIDATE: normal-addressing ISO-TP. PSA-RE bits 1.3-1.0. Declared data length; not a validity check.";
CM_ SG_ 1901 IsoTpFrameType "TRANSPORT_CANDIDATE: normal-addressing ISO-TP. PSA-RE bits 1.7-1.4. PCI high nibble; normal addressing candidate.";
CM_ BO_ 1902 "DATABASE_CANDIDATE: physical interpretation unverified; capture/layout evidence reported separately. INFO-DIV CAN, 125000 bit/s; CAN ID 0x76E. PSA-RE title: BDMC_DIAG_REQUEST. Diagnostic request addressed to the BDMC ECU. Source: https://github.com/prototux/PSA-RE/blob/67f7581e7622410efdbb29c7eda3b86982b9b450/buses/AEE2010.full/LS.INFO-DIV/76E.yml. Source sender alternatives: MDS; physical TX/gateway forwarding not verified. WIRE ISO-TP ONLY: normal addressing candidate, maximum Classical CAN DLC 8; actual DLC may be shorter. Data includes padding. No reassembly, text, DID or application-layer decoding. Original application layouts are preserved in source JSON; do not decode them at wire offsets. ";
CM_ SG_ 1902 FlowPadding5 "TRANSPORT_CANDIDATE: normal-addressing ISO-TP. PSA-RE bits 8.7-8.0. ";
CM_ SG_ 1902 FirstData6 "TRANSPORT_CANDIDATE: normal-addressing ISO-TP. PSA-RE bits 8.7-8.0. ";
CM_ SG_ 1902 UnknownData7 "TRANSPORT_CANDIDATE: normal-addressing ISO-TP. PSA-RE bits 8.7-8.0. ";
CM_ SG_ 1902 ConsecutiveData7 "TRANSPORT_CANDIDATE: normal-addressing ISO-TP. PSA-RE bits 8.7-8.0. ";
CM_ SG_ 1902 SingleData7 "TRANSPORT_CANDIDATE: normal-addressing ISO-TP. PSA-RE bits 8.7-8.0. ";
CM_ SG_ 1902 FlowPadding4 "TRANSPORT_CANDIDATE: normal-addressing ISO-TP. PSA-RE bits 7.7-7.0. ";
CM_ SG_ 1902 FirstData5 "TRANSPORT_CANDIDATE: normal-addressing ISO-TP. PSA-RE bits 7.7-7.0. ";
CM_ SG_ 1902 UnknownData6 "TRANSPORT_CANDIDATE: normal-addressing ISO-TP. PSA-RE bits 7.7-7.0. ";
CM_ SG_ 1902 ConsecutiveData6 "TRANSPORT_CANDIDATE: normal-addressing ISO-TP. PSA-RE bits 7.7-7.0. ";
CM_ SG_ 1902 SingleData6 "TRANSPORT_CANDIDATE: normal-addressing ISO-TP. PSA-RE bits 7.7-7.0. ";
CM_ SG_ 1902 FlowPadding3 "TRANSPORT_CANDIDATE: normal-addressing ISO-TP. PSA-RE bits 6.7-6.0. ";
CM_ SG_ 1902 FirstData4 "TRANSPORT_CANDIDATE: normal-addressing ISO-TP. PSA-RE bits 6.7-6.0. ";
CM_ SG_ 1902 UnknownData5 "TRANSPORT_CANDIDATE: normal-addressing ISO-TP. PSA-RE bits 6.7-6.0. ";
CM_ SG_ 1902 ConsecutiveData5 "TRANSPORT_CANDIDATE: normal-addressing ISO-TP. PSA-RE bits 6.7-6.0. ";
CM_ SG_ 1902 SingleData5 "TRANSPORT_CANDIDATE: normal-addressing ISO-TP. PSA-RE bits 6.7-6.0. ";
CM_ SG_ 1902 FlowPadding2 "TRANSPORT_CANDIDATE: normal-addressing ISO-TP. PSA-RE bits 5.7-5.0. ";
CM_ SG_ 1902 FirstData3 "TRANSPORT_CANDIDATE: normal-addressing ISO-TP. PSA-RE bits 5.7-5.0. ";
CM_ SG_ 1902 UnknownData4 "TRANSPORT_CANDIDATE: normal-addressing ISO-TP. PSA-RE bits 5.7-5.0. ";
CM_ SG_ 1902 ConsecutiveData4 "TRANSPORT_CANDIDATE: normal-addressing ISO-TP. PSA-RE bits 5.7-5.0. ";
CM_ SG_ 1902 SingleData4 "TRANSPORT_CANDIDATE: normal-addressing ISO-TP. PSA-RE bits 5.7-5.0. ";
CM_ SG_ 1902 FlowPadding1 "TRANSPORT_CANDIDATE: normal-addressing ISO-TP. PSA-RE bits 4.7-4.0. ";
CM_ SG_ 1902 FirstData2 "TRANSPORT_CANDIDATE: normal-addressing ISO-TP. PSA-RE bits 4.7-4.0. ";
CM_ SG_ 1902 UnknownData3 "TRANSPORT_CANDIDATE: normal-addressing ISO-TP. PSA-RE bits 4.7-4.0. ";
CM_ SG_ 1902 ConsecutiveData3 "TRANSPORT_CANDIDATE: normal-addressing ISO-TP. PSA-RE bits 4.7-4.0. ";
CM_ SG_ 1902 SingleData3 "TRANSPORT_CANDIDATE: normal-addressing ISO-TP. PSA-RE bits 4.7-4.0. ";
CM_ SG_ 1902 FirstData1 "TRANSPORT_CANDIDATE: normal-addressing ISO-TP. PSA-RE bits 3.7-3.0. ";
CM_ SG_ 1902 UnknownData2 "TRANSPORT_CANDIDATE: normal-addressing ISO-TP. PSA-RE bits 3.7-3.0. ";
CM_ SG_ 1902 ConsecutiveData2 "TRANSPORT_CANDIDATE: normal-addressing ISO-TP. PSA-RE bits 3.7-3.0. ";
CM_ SG_ 1902 SingleData2 "TRANSPORT_CANDIDATE: normal-addressing ISO-TP. PSA-RE bits 3.7-3.0. ";
CM_ SG_ 1902 SeparationTimeRaw "TRANSPORT_CANDIDATE: normal-addressing ISO-TP. PSA-RE bits 3.7-3.0. Raw STmin code; 0xF1..0xF9 are not milliseconds.";
CM_ SG_ 1902 UnknownData1 "TRANSPORT_CANDIDATE: normal-addressing ISO-TP. PSA-RE bits 2.7-2.0. ";
CM_ SG_ 1902 ConsecutiveData1 "TRANSPORT_CANDIDATE: normal-addressing ISO-TP. PSA-RE bits 2.7-2.0. ";
CM_ SG_ 1902 SingleData1 "TRANSPORT_CANDIDATE: normal-addressing ISO-TP. PSA-RE bits 2.7-2.0. ";
CM_ SG_ 1902 BlockSize "TRANSPORT_CANDIDATE: normal-addressing ISO-TP. PSA-RE bits 2.7-2.0. ";
CM_ SG_ 1902 UnknownPciLow "TRANSPORT_CANDIDATE: normal-addressing ISO-TP. PSA-RE bits 1.3-1.0. ";
CM_ SG_ 1902 FlowStatus "TRANSPORT_CANDIDATE: normal-addressing ISO-TP. PSA-RE bits 1.3-1.0. ";
CM_ SG_ 1902 ConsecutiveSequence "TRANSPORT_CANDIDATE: normal-addressing ISO-TP. PSA-RE bits 1.3-1.0. ";
CM_ SG_ 1902 FirstFrameLength "TRANSPORT_CANDIDATE: normal-addressing ISO-TP. PSA-RE bits 1.3-2.0. 12-bit declared PDU length; not a reassembled value.";
CM_ SG_ 1902 SingleFrameLength "TRANSPORT_CANDIDATE: normal-addressing ISO-TP. PSA-RE bits 1.3-1.0. Declared data length; not a validity check.";
CM_ SG_ 1902 IsoTpFrameType "TRANSPORT_CANDIDATE: normal-addressing ISO-TP. PSA-RE bits 1.7-1.4. PCI high nibble; normal addressing candidate.";
CM_ BO_ 1903 "DATABASE_CANDIDATE: physical interpretation unverified; capture/layout evidence reported separately. INFO-DIV CAN, 125000 bit/s; CAN ID 0x76F. PSA-RE title: FAULT_LOG_DSG_RAW. Diagnostic request addressed to the BDMP ECU. Source: https://github.com/prototux/PSA-RE/blob/67f7581e7622410efdbb29c7eda3b86982b9b450/buses/AEE2010.full/LS.INFO-DIV/76F.yml. Source sender alternatives: MDS; physical TX/gateway forwarding not verified. WIRE ISO-TP ONLY: normal addressing candidate, maximum Classical CAN DLC 8; actual DLC may be shorter. Data includes padding. No reassembly, text, DID or application-layer decoding. Original application layouts are preserved in source JSON; do not decode them at wire offsets. ";
CM_ SG_ 1903 FlowPadding5 "TRANSPORT_CANDIDATE: normal-addressing ISO-TP. PSA-RE bits 8.7-8.0. ";
CM_ SG_ 1903 FirstData6 "TRANSPORT_CANDIDATE: normal-addressing ISO-TP. PSA-RE bits 8.7-8.0. ";
CM_ SG_ 1903 UnknownData7 "TRANSPORT_CANDIDATE: normal-addressing ISO-TP. PSA-RE bits 8.7-8.0. ";
CM_ SG_ 1903 ConsecutiveData7 "TRANSPORT_CANDIDATE: normal-addressing ISO-TP. PSA-RE bits 8.7-8.0. ";
CM_ SG_ 1903 SingleData7 "TRANSPORT_CANDIDATE: normal-addressing ISO-TP. PSA-RE bits 8.7-8.0. ";
CM_ SG_ 1903 FlowPadding4 "TRANSPORT_CANDIDATE: normal-addressing ISO-TP. PSA-RE bits 7.7-7.0. ";
CM_ SG_ 1903 FirstData5 "TRANSPORT_CANDIDATE: normal-addressing ISO-TP. PSA-RE bits 7.7-7.0. ";
CM_ SG_ 1903 UnknownData6 "TRANSPORT_CANDIDATE: normal-addressing ISO-TP. PSA-RE bits 7.7-7.0. ";
CM_ SG_ 1903 ConsecutiveData6 "TRANSPORT_CANDIDATE: normal-addressing ISO-TP. PSA-RE bits 7.7-7.0. ";
CM_ SG_ 1903 SingleData6 "TRANSPORT_CANDIDATE: normal-addressing ISO-TP. PSA-RE bits 7.7-7.0. ";
CM_ SG_ 1903 FlowPadding3 "TRANSPORT_CANDIDATE: normal-addressing ISO-TP. PSA-RE bits 6.7-6.0. ";
CM_ SG_ 1903 FirstData4 "TRANSPORT_CANDIDATE: normal-addressing ISO-TP. PSA-RE bits 6.7-6.0. ";
CM_ SG_ 1903 UnknownData5 "TRANSPORT_CANDIDATE: normal-addressing ISO-TP. PSA-RE bits 6.7-6.0. ";
CM_ SG_ 1903 ConsecutiveData5 "TRANSPORT_CANDIDATE: normal-addressing ISO-TP. PSA-RE bits 6.7-6.0. ";
CM_ SG_ 1903 SingleData5 "TRANSPORT_CANDIDATE: normal-addressing ISO-TP. PSA-RE bits 6.7-6.0. ";
CM_ SG_ 1903 FlowPadding2 "TRANSPORT_CANDIDATE: normal-addressing ISO-TP. PSA-RE bits 5.7-5.0. ";
CM_ SG_ 1903 FirstData3 "TRANSPORT_CANDIDATE: normal-addressing ISO-TP. PSA-RE bits 5.7-5.0. ";
CM_ SG_ 1903 UnknownData4 "TRANSPORT_CANDIDATE: normal-addressing ISO-TP. PSA-RE bits 5.7-5.0. ";
CM_ SG_ 1903 ConsecutiveData4 "TRANSPORT_CANDIDATE: normal-addressing ISO-TP. PSA-RE bits 5.7-5.0. ";
CM_ SG_ 1903 SingleData4 "TRANSPORT_CANDIDATE: normal-addressing ISO-TP. PSA-RE bits 5.7-5.0. ";
CM_ SG_ 1903 FlowPadding1 "TRANSPORT_CANDIDATE: normal-addressing ISO-TP. PSA-RE bits 4.7-4.0. ";
CM_ SG_ 1903 FirstData2 "TRANSPORT_CANDIDATE: normal-addressing ISO-TP. PSA-RE bits 4.7-4.0. ";
CM_ SG_ 1903 UnknownData3 "TRANSPORT_CANDIDATE: normal-addressing ISO-TP. PSA-RE bits 4.7-4.0. ";
CM_ SG_ 1903 ConsecutiveData3 "TRANSPORT_CANDIDATE: normal-addressing ISO-TP. PSA-RE bits 4.7-4.0. ";
CM_ SG_ 1903 SingleData3 "TRANSPORT_CANDIDATE: normal-addressing ISO-TP. PSA-RE bits 4.7-4.0. ";
CM_ SG_ 1903 FirstData1 "TRANSPORT_CANDIDATE: normal-addressing ISO-TP. PSA-RE bits 3.7-3.0. ";
CM_ SG_ 1903 UnknownData2 "TRANSPORT_CANDIDATE: normal-addressing ISO-TP. PSA-RE bits 3.7-3.0. ";
CM_ SG_ 1903 ConsecutiveData2 "TRANSPORT_CANDIDATE: normal-addressing ISO-TP. PSA-RE bits 3.7-3.0. ";
CM_ SG_ 1903 SingleData2 "TRANSPORT_CANDIDATE: normal-addressing ISO-TP. PSA-RE bits 3.7-3.0. ";
CM_ SG_ 1903 SeparationTimeRaw "TRANSPORT_CANDIDATE: normal-addressing ISO-TP. PSA-RE bits 3.7-3.0. Raw STmin code; 0xF1..0xF9 are not milliseconds.";
CM_ SG_ 1903 UnknownData1 "TRANSPORT_CANDIDATE: normal-addressing ISO-TP. PSA-RE bits 2.7-2.0. ";
CM_ SG_ 1903 ConsecutiveData1 "TRANSPORT_CANDIDATE: normal-addressing ISO-TP. PSA-RE bits 2.7-2.0. ";
CM_ SG_ 1903 SingleData1 "TRANSPORT_CANDIDATE: normal-addressing ISO-TP. PSA-RE bits 2.7-2.0. ";
CM_ SG_ 1903 BlockSize "TRANSPORT_CANDIDATE: normal-addressing ISO-TP. PSA-RE bits 2.7-2.0. ";
CM_ SG_ 1903 UnknownPciLow "TRANSPORT_CANDIDATE: normal-addressing ISO-TP. PSA-RE bits 1.3-1.0. ";
CM_ SG_ 1903 FlowStatus "TRANSPORT_CANDIDATE: normal-addressing ISO-TP. PSA-RE bits 1.3-1.0. ";
CM_ SG_ 1903 ConsecutiveSequence "TRANSPORT_CANDIDATE: normal-addressing ISO-TP. PSA-RE bits 1.3-1.0. ";
CM_ SG_ 1903 FirstFrameLength "TRANSPORT_CANDIDATE: normal-addressing ISO-TP. PSA-RE bits 1.3-2.0. 12-bit declared PDU length; not a reassembled value.";
CM_ SG_ 1903 SingleFrameLength "TRANSPORT_CANDIDATE: normal-addressing ISO-TP. PSA-RE bits 1.3-1.0. Declared data length; not a validity check.";
CM_ SG_ 1903 IsoTpFrameType "TRANSPORT_CANDIDATE: normal-addressing ISO-TP. PSA-RE bits 1.7-1.4. PCI high nibble; normal addressing candidate.";
CM_ BO_ 1904 "DATABASE_CANDIDATE: physical interpretation unverified; capture/layout evidence reported separately. INFO-DIV CAN, 125000 bit/s; CAN ID 0x770. PSA-RE title: FAULT_LOG_CSS. Diagnostic session request frame addressed to this module Source: https://github.com/prototux/PSA-RE/blob/67f7581e7622410efdbb29c7eda3b86982b9b450/buses/AEE2010.full/LS.INFO-DIV/770.yml. Source sender alternatives: BSI,MDS; physical TX/gateway forwarding not verified. WIRE ISO-TP ONLY: normal addressing candidate, maximum Classical CAN DLC 8; actual DLC may be shorter. Data includes padding. No reassembly, text, DID or application-layer decoding. Original application layouts are preserved in source JSON; do not decode them at wire offsets. ";
CM_ SG_ 1904 FlowPadding5 "TRANSPORT_CANDIDATE: normal-addressing ISO-TP. PSA-RE bits 8.7-8.0. ";
CM_ SG_ 1904 FirstData6 "TRANSPORT_CANDIDATE: normal-addressing ISO-TP. PSA-RE bits 8.7-8.0. ";
CM_ SG_ 1904 UnknownData7 "TRANSPORT_CANDIDATE: normal-addressing ISO-TP. PSA-RE bits 8.7-8.0. ";
CM_ SG_ 1904 ConsecutiveData7 "TRANSPORT_CANDIDATE: normal-addressing ISO-TP. PSA-RE bits 8.7-8.0. ";
CM_ SG_ 1904 SingleData7 "TRANSPORT_CANDIDATE: normal-addressing ISO-TP. PSA-RE bits 8.7-8.0. ";
CM_ SG_ 1904 FlowPadding4 "TRANSPORT_CANDIDATE: normal-addressing ISO-TP. PSA-RE bits 7.7-7.0. ";
CM_ SG_ 1904 FirstData5 "TRANSPORT_CANDIDATE: normal-addressing ISO-TP. PSA-RE bits 7.7-7.0. ";
CM_ SG_ 1904 UnknownData6 "TRANSPORT_CANDIDATE: normal-addressing ISO-TP. PSA-RE bits 7.7-7.0. ";
CM_ SG_ 1904 ConsecutiveData6 "TRANSPORT_CANDIDATE: normal-addressing ISO-TP. PSA-RE bits 7.7-7.0. ";
CM_ SG_ 1904 SingleData6 "TRANSPORT_CANDIDATE: normal-addressing ISO-TP. PSA-RE bits 7.7-7.0. ";
CM_ SG_ 1904 FlowPadding3 "TRANSPORT_CANDIDATE: normal-addressing ISO-TP. PSA-RE bits 6.7-6.0. ";
CM_ SG_ 1904 FirstData4 "TRANSPORT_CANDIDATE: normal-addressing ISO-TP. PSA-RE bits 6.7-6.0. ";
CM_ SG_ 1904 UnknownData5 "TRANSPORT_CANDIDATE: normal-addressing ISO-TP. PSA-RE bits 6.7-6.0. ";
CM_ SG_ 1904 ConsecutiveData5 "TRANSPORT_CANDIDATE: normal-addressing ISO-TP. PSA-RE bits 6.7-6.0. ";
CM_ SG_ 1904 SingleData5 "TRANSPORT_CANDIDATE: normal-addressing ISO-TP. PSA-RE bits 6.7-6.0. ";
CM_ SG_ 1904 FlowPadding2 "TRANSPORT_CANDIDATE: normal-addressing ISO-TP. PSA-RE bits 5.7-5.0. ";
CM_ SG_ 1904 FirstData3 "TRANSPORT_CANDIDATE: normal-addressing ISO-TP. PSA-RE bits 5.7-5.0. ";
CM_ SG_ 1904 UnknownData4 "TRANSPORT_CANDIDATE: normal-addressing ISO-TP. PSA-RE bits 5.7-5.0. ";
CM_ SG_ 1904 ConsecutiveData4 "TRANSPORT_CANDIDATE: normal-addressing ISO-TP. PSA-RE bits 5.7-5.0. ";
CM_ SG_ 1904 SingleData4 "TRANSPORT_CANDIDATE: normal-addressing ISO-TP. PSA-RE bits 5.7-5.0. ";
CM_ SG_ 1904 FlowPadding1 "TRANSPORT_CANDIDATE: normal-addressing ISO-TP. PSA-RE bits 4.7-4.0. ";
CM_ SG_ 1904 FirstData2 "TRANSPORT_CANDIDATE: normal-addressing ISO-TP. PSA-RE bits 4.7-4.0. ";
CM_ SG_ 1904 UnknownData3 "TRANSPORT_CANDIDATE: normal-addressing ISO-TP. PSA-RE bits 4.7-4.0. ";
CM_ SG_ 1904 ConsecutiveData3 "TRANSPORT_CANDIDATE: normal-addressing ISO-TP. PSA-RE bits 4.7-4.0. ";
CM_ SG_ 1904 SingleData3 "TRANSPORT_CANDIDATE: normal-addressing ISO-TP. PSA-RE bits 4.7-4.0. ";
CM_ SG_ 1904 FirstData1 "TRANSPORT_CANDIDATE: normal-addressing ISO-TP. PSA-RE bits 3.7-3.0. ";
CM_ SG_ 1904 UnknownData2 "TRANSPORT_CANDIDATE: normal-addressing ISO-TP. PSA-RE bits 3.7-3.0. ";
CM_ SG_ 1904 ConsecutiveData2 "TRANSPORT_CANDIDATE: normal-addressing ISO-TP. PSA-RE bits 3.7-3.0. ";
CM_ SG_ 1904 SingleData2 "TRANSPORT_CANDIDATE: normal-addressing ISO-TP. PSA-RE bits 3.7-3.0. ";
CM_ SG_ 1904 SeparationTimeRaw "TRANSPORT_CANDIDATE: normal-addressing ISO-TP. PSA-RE bits 3.7-3.0. Raw STmin code; 0xF1..0xF9 are not milliseconds.";
CM_ SG_ 1904 UnknownData1 "TRANSPORT_CANDIDATE: normal-addressing ISO-TP. PSA-RE bits 2.7-2.0. ";
CM_ SG_ 1904 ConsecutiveData1 "TRANSPORT_CANDIDATE: normal-addressing ISO-TP. PSA-RE bits 2.7-2.0. ";
CM_ SG_ 1904 SingleData1 "TRANSPORT_CANDIDATE: normal-addressing ISO-TP. PSA-RE bits 2.7-2.0. ";
CM_ SG_ 1904 BlockSize "TRANSPORT_CANDIDATE: normal-addressing ISO-TP. PSA-RE bits 2.7-2.0. ";
CM_ SG_ 1904 UnknownPciLow "TRANSPORT_CANDIDATE: normal-addressing ISO-TP. PSA-RE bits 1.3-1.0. ";
CM_ SG_ 1904 FlowStatus "TRANSPORT_CANDIDATE: normal-addressing ISO-TP. PSA-RE bits 1.3-1.0. ";
CM_ SG_ 1904 ConsecutiveSequence "TRANSPORT_CANDIDATE: normal-addressing ISO-TP. PSA-RE bits 1.3-1.0. ";
CM_ SG_ 1904 FirstFrameLength "TRANSPORT_CANDIDATE: normal-addressing ISO-TP. PSA-RE bits 1.3-2.0. 12-bit declared PDU length; not a reassembled value.";
CM_ SG_ 1904 SingleFrameLength "TRANSPORT_CANDIDATE: normal-addressing ISO-TP. PSA-RE bits 1.3-1.0. Declared data length; not a validity check.";
CM_ SG_ 1904 IsoTpFrameType "TRANSPORT_CANDIDATE: normal-addressing ISO-TP. PSA-RE bits 1.7-1.4. PCI high nibble; normal addressing candidate.";
CM_ BO_ 1905 "DATABASE_CANDIDATE: physical interpretation unverified; capture/layout evidence reported separately. INFO-DIV CAN, 125000 bit/s; CAN ID 0x771. PSA-RE title: FAULT_LOG_BHI_RAW. Diagnostic request frame sent on the bus. Source: https://github.com/prototux/PSA-RE/blob/67f7581e7622410efdbb29c7eda3b86982b9b450/buses/AEE2010.full/LS.INFO-DIV/771.yml. Source sender alternatives: BSI,MDS; physical TX/gateway forwarding not verified. WIRE ISO-TP ONLY: normal addressing candidate, maximum Classical CAN DLC 8; actual DLC may be shorter. Data includes padding. No reassembly, text, DID or application-layer decoding. Original application layouts are preserved in source JSON; do not decode them at wire offsets. ";
CM_ SG_ 1905 FlowPadding5 "TRANSPORT_CANDIDATE: normal-addressing ISO-TP. PSA-RE bits 8.7-8.0. ";
CM_ SG_ 1905 FirstData6 "TRANSPORT_CANDIDATE: normal-addressing ISO-TP. PSA-RE bits 8.7-8.0. ";
CM_ SG_ 1905 UnknownData7 "TRANSPORT_CANDIDATE: normal-addressing ISO-TP. PSA-RE bits 8.7-8.0. ";
CM_ SG_ 1905 ConsecutiveData7 "TRANSPORT_CANDIDATE: normal-addressing ISO-TP. PSA-RE bits 8.7-8.0. ";
CM_ SG_ 1905 SingleData7 "TRANSPORT_CANDIDATE: normal-addressing ISO-TP. PSA-RE bits 8.7-8.0. ";
CM_ SG_ 1905 FlowPadding4 "TRANSPORT_CANDIDATE: normal-addressing ISO-TP. PSA-RE bits 7.7-7.0. ";
CM_ SG_ 1905 FirstData5 "TRANSPORT_CANDIDATE: normal-addressing ISO-TP. PSA-RE bits 7.7-7.0. ";
CM_ SG_ 1905 UnknownData6 "TRANSPORT_CANDIDATE: normal-addressing ISO-TP. PSA-RE bits 7.7-7.0. ";
CM_ SG_ 1905 ConsecutiveData6 "TRANSPORT_CANDIDATE: normal-addressing ISO-TP. PSA-RE bits 7.7-7.0. ";
CM_ SG_ 1905 SingleData6 "TRANSPORT_CANDIDATE: normal-addressing ISO-TP. PSA-RE bits 7.7-7.0. ";
CM_ SG_ 1905 FlowPadding3 "TRANSPORT_CANDIDATE: normal-addressing ISO-TP. PSA-RE bits 6.7-6.0. ";
CM_ SG_ 1905 FirstData4 "TRANSPORT_CANDIDATE: normal-addressing ISO-TP. PSA-RE bits 6.7-6.0. ";
CM_ SG_ 1905 UnknownData5 "TRANSPORT_CANDIDATE: normal-addressing ISO-TP. PSA-RE bits 6.7-6.0. ";
CM_ SG_ 1905 ConsecutiveData5 "TRANSPORT_CANDIDATE: normal-addressing ISO-TP. PSA-RE bits 6.7-6.0. ";
CM_ SG_ 1905 SingleData5 "TRANSPORT_CANDIDATE: normal-addressing ISO-TP. PSA-RE bits 6.7-6.0. ";
CM_ SG_ 1905 FlowPadding2 "TRANSPORT_CANDIDATE: normal-addressing ISO-TP. PSA-RE bits 5.7-5.0. ";
CM_ SG_ 1905 FirstData3 "TRANSPORT_CANDIDATE: normal-addressing ISO-TP. PSA-RE bits 5.7-5.0. ";
CM_ SG_ 1905 UnknownData4 "TRANSPORT_CANDIDATE: normal-addressing ISO-TP. PSA-RE bits 5.7-5.0. ";
CM_ SG_ 1905 ConsecutiveData4 "TRANSPORT_CANDIDATE: normal-addressing ISO-TP. PSA-RE bits 5.7-5.0. ";
CM_ SG_ 1905 SingleData4 "TRANSPORT_CANDIDATE: normal-addressing ISO-TP. PSA-RE bits 5.7-5.0. ";
CM_ SG_ 1905 FlowPadding1 "TRANSPORT_CANDIDATE: normal-addressing ISO-TP. PSA-RE bits 4.7-4.0. ";
CM_ SG_ 1905 FirstData2 "TRANSPORT_CANDIDATE: normal-addressing ISO-TP. PSA-RE bits 4.7-4.0. ";
CM_ SG_ 1905 UnknownData3 "TRANSPORT_CANDIDATE: normal-addressing ISO-TP. PSA-RE bits 4.7-4.0. ";
CM_ SG_ 1905 ConsecutiveData3 "TRANSPORT_CANDIDATE: normal-addressing ISO-TP. PSA-RE bits 4.7-4.0. ";
CM_ SG_ 1905 SingleData3 "TRANSPORT_CANDIDATE: normal-addressing ISO-TP. PSA-RE bits 4.7-4.0. ";
CM_ SG_ 1905 FirstData1 "TRANSPORT_CANDIDATE: normal-addressing ISO-TP. PSA-RE bits 3.7-3.0. ";
CM_ SG_ 1905 UnknownData2 "TRANSPORT_CANDIDATE: normal-addressing ISO-TP. PSA-RE bits 3.7-3.0. ";
CM_ SG_ 1905 ConsecutiveData2 "TRANSPORT_CANDIDATE: normal-addressing ISO-TP. PSA-RE bits 3.7-3.0. ";
CM_ SG_ 1905 SingleData2 "TRANSPORT_CANDIDATE: normal-addressing ISO-TP. PSA-RE bits 3.7-3.0. ";
CM_ SG_ 1905 SeparationTimeRaw "TRANSPORT_CANDIDATE: normal-addressing ISO-TP. PSA-RE bits 3.7-3.0. Raw STmin code; 0xF1..0xF9 are not milliseconds.";
CM_ SG_ 1905 UnknownData1 "TRANSPORT_CANDIDATE: normal-addressing ISO-TP. PSA-RE bits 2.7-2.0. ";
CM_ SG_ 1905 ConsecutiveData1 "TRANSPORT_CANDIDATE: normal-addressing ISO-TP. PSA-RE bits 2.7-2.0. ";
CM_ SG_ 1905 SingleData1 "TRANSPORT_CANDIDATE: normal-addressing ISO-TP. PSA-RE bits 2.7-2.0. ";
CM_ SG_ 1905 BlockSize "TRANSPORT_CANDIDATE: normal-addressing ISO-TP. PSA-RE bits 2.7-2.0. ";
CM_ SG_ 1905 UnknownPciLow "TRANSPORT_CANDIDATE: normal-addressing ISO-TP. PSA-RE bits 1.3-1.0. ";
CM_ SG_ 1905 FlowStatus "TRANSPORT_CANDIDATE: normal-addressing ISO-TP. PSA-RE bits 1.3-1.0. ";
CM_ SG_ 1905 ConsecutiveSequence "TRANSPORT_CANDIDATE: normal-addressing ISO-TP. PSA-RE bits 1.3-1.0. ";
CM_ SG_ 1905 FirstFrameLength "TRANSPORT_CANDIDATE: normal-addressing ISO-TP. PSA-RE bits 1.3-2.0. 12-bit declared PDU length; not a reassembled value.";
CM_ SG_ 1905 SingleFrameLength "TRANSPORT_CANDIDATE: normal-addressing ISO-TP. PSA-RE bits 1.3-1.0. Declared data length; not a validity check.";
CM_ SG_ 1905 IsoTpFrameType "TRANSPORT_CANDIDATE: normal-addressing ISO-TP. PSA-RE bits 1.7-1.4. PCI high nibble; normal addressing candidate.";
CM_ BO_ 1906 "DATABASE_CANDIDATE: physical interpretation unverified; capture/layout evidence reported separately. INFO-DIV CAN, 125000 bit/s; CAN ID 0x772. PSA-RE title: BSI_FAULT_LOG_ACK_2. Diagnostic request addressed to the MATT ECU. Source: https://github.com/prototux/PSA-RE/blob/67f7581e7622410efdbb29c7eda3b86982b9b450/buses/AEE2010.full/LS.INFO-DIV/772.yml. Source sender alternatives: BSI,MDS; physical TX/gateway forwarding not verified. WIRE ISO-TP ONLY: normal addressing candidate, maximum Classical CAN DLC 8; actual DLC may be shorter. Data includes padding. No reassembly, text, DID or application-layer decoding. Original application layouts are preserved in source JSON; do not decode them at wire offsets. ";
CM_ SG_ 1906 FlowPadding5 "TRANSPORT_CANDIDATE: normal-addressing ISO-TP. PSA-RE bits 8.7-8.0. ";
CM_ SG_ 1906 FirstData6 "TRANSPORT_CANDIDATE: normal-addressing ISO-TP. PSA-RE bits 8.7-8.0. ";
CM_ SG_ 1906 UnknownData7 "TRANSPORT_CANDIDATE: normal-addressing ISO-TP. PSA-RE bits 8.7-8.0. ";
CM_ SG_ 1906 ConsecutiveData7 "TRANSPORT_CANDIDATE: normal-addressing ISO-TP. PSA-RE bits 8.7-8.0. ";
CM_ SG_ 1906 SingleData7 "TRANSPORT_CANDIDATE: normal-addressing ISO-TP. PSA-RE bits 8.7-8.0. ";
CM_ SG_ 1906 FlowPadding4 "TRANSPORT_CANDIDATE: normal-addressing ISO-TP. PSA-RE bits 7.7-7.0. ";
CM_ SG_ 1906 FirstData5 "TRANSPORT_CANDIDATE: normal-addressing ISO-TP. PSA-RE bits 7.7-7.0. ";
CM_ SG_ 1906 UnknownData6 "TRANSPORT_CANDIDATE: normal-addressing ISO-TP. PSA-RE bits 7.7-7.0. ";
CM_ SG_ 1906 ConsecutiveData6 "TRANSPORT_CANDIDATE: normal-addressing ISO-TP. PSA-RE bits 7.7-7.0. ";
CM_ SG_ 1906 SingleData6 "TRANSPORT_CANDIDATE: normal-addressing ISO-TP. PSA-RE bits 7.7-7.0. ";
CM_ SG_ 1906 FlowPadding3 "TRANSPORT_CANDIDATE: normal-addressing ISO-TP. PSA-RE bits 6.7-6.0. ";
CM_ SG_ 1906 FirstData4 "TRANSPORT_CANDIDATE: normal-addressing ISO-TP. PSA-RE bits 6.7-6.0. ";
CM_ SG_ 1906 UnknownData5 "TRANSPORT_CANDIDATE: normal-addressing ISO-TP. PSA-RE bits 6.7-6.0. ";
CM_ SG_ 1906 ConsecutiveData5 "TRANSPORT_CANDIDATE: normal-addressing ISO-TP. PSA-RE bits 6.7-6.0. ";
CM_ SG_ 1906 SingleData5 "TRANSPORT_CANDIDATE: normal-addressing ISO-TP. PSA-RE bits 6.7-6.0. ";
CM_ SG_ 1906 FlowPadding2 "TRANSPORT_CANDIDATE: normal-addressing ISO-TP. PSA-RE bits 5.7-5.0. ";
CM_ SG_ 1906 FirstData3 "TRANSPORT_CANDIDATE: normal-addressing ISO-TP. PSA-RE bits 5.7-5.0. ";
CM_ SG_ 1906 UnknownData4 "TRANSPORT_CANDIDATE: normal-addressing ISO-TP. PSA-RE bits 5.7-5.0. ";
CM_ SG_ 1906 ConsecutiveData4 "TRANSPORT_CANDIDATE: normal-addressing ISO-TP. PSA-RE bits 5.7-5.0. ";
CM_ SG_ 1906 SingleData4 "TRANSPORT_CANDIDATE: normal-addressing ISO-TP. PSA-RE bits 5.7-5.0. ";
CM_ SG_ 1906 FlowPadding1 "TRANSPORT_CANDIDATE: normal-addressing ISO-TP. PSA-RE bits 4.7-4.0. ";
CM_ SG_ 1906 FirstData2 "TRANSPORT_CANDIDATE: normal-addressing ISO-TP. PSA-RE bits 4.7-4.0. ";
CM_ SG_ 1906 UnknownData3 "TRANSPORT_CANDIDATE: normal-addressing ISO-TP. PSA-RE bits 4.7-4.0. ";
CM_ SG_ 1906 ConsecutiveData3 "TRANSPORT_CANDIDATE: normal-addressing ISO-TP. PSA-RE bits 4.7-4.0. ";
CM_ SG_ 1906 SingleData3 "TRANSPORT_CANDIDATE: normal-addressing ISO-TP. PSA-RE bits 4.7-4.0. ";
CM_ SG_ 1906 FirstData1 "TRANSPORT_CANDIDATE: normal-addressing ISO-TP. PSA-RE bits 3.7-3.0. ";
CM_ SG_ 1906 UnknownData2 "TRANSPORT_CANDIDATE: normal-addressing ISO-TP. PSA-RE bits 3.7-3.0. ";
CM_ SG_ 1906 ConsecutiveData2 "TRANSPORT_CANDIDATE: normal-addressing ISO-TP. PSA-RE bits 3.7-3.0. ";
CM_ SG_ 1906 SingleData2 "TRANSPORT_CANDIDATE: normal-addressing ISO-TP. PSA-RE bits 3.7-3.0. ";
CM_ SG_ 1906 SeparationTimeRaw "TRANSPORT_CANDIDATE: normal-addressing ISO-TP. PSA-RE bits 3.7-3.0. Raw STmin code; 0xF1..0xF9 are not milliseconds.";
CM_ SG_ 1906 UnknownData1 "TRANSPORT_CANDIDATE: normal-addressing ISO-TP. PSA-RE bits 2.7-2.0. ";
CM_ SG_ 1906 ConsecutiveData1 "TRANSPORT_CANDIDATE: normal-addressing ISO-TP. PSA-RE bits 2.7-2.0. ";
CM_ SG_ 1906 SingleData1 "TRANSPORT_CANDIDATE: normal-addressing ISO-TP. PSA-RE bits 2.7-2.0. ";
CM_ SG_ 1906 BlockSize "TRANSPORT_CANDIDATE: normal-addressing ISO-TP. PSA-RE bits 2.7-2.0. ";
CM_ SG_ 1906 UnknownPciLow "TRANSPORT_CANDIDATE: normal-addressing ISO-TP. PSA-RE bits 1.3-1.0. ";
CM_ SG_ 1906 FlowStatus "TRANSPORT_CANDIDATE: normal-addressing ISO-TP. PSA-RE bits 1.3-1.0. ";
CM_ SG_ 1906 ConsecutiveSequence "TRANSPORT_CANDIDATE: normal-addressing ISO-TP. PSA-RE bits 1.3-1.0. ";
CM_ SG_ 1906 FirstFrameLength "TRANSPORT_CANDIDATE: normal-addressing ISO-TP. PSA-RE bits 1.3-2.0. 12-bit declared PDU length; not a reassembled value.";
CM_ SG_ 1906 SingleFrameLength "TRANSPORT_CANDIDATE: normal-addressing ISO-TP. PSA-RE bits 1.3-1.0. Declared data length; not a validity check.";
CM_ SG_ 1906 IsoTpFrameType "TRANSPORT_CANDIDATE: normal-addressing ISO-TP. PSA-RE bits 1.7-1.4. PCI high nibble; normal addressing candidate.";
CM_ BO_ 1907 "DATABASE_CANDIDATE: physical interpretation unverified; capture/layout evidence reported separately. INFO-DIV CAN, 125000 bit/s; CAN ID 0x773. PSA-RE title: FAULT_LOG_EPB_RAW. Diagnostic request addressed to the AVP ECU. Source: https://github.com/prototux/PSA-RE/blob/67f7581e7622410efdbb29c7eda3b86982b9b450/buses/AEE2010.full/LS.INFO-DIV/773.yml. Source sender alternatives: BSI,MDS; physical TX/gateway forwarding not verified. WIRE ISO-TP ONLY: normal addressing candidate, maximum Classical CAN DLC 8; actual DLC may be shorter. Data includes padding. No reassembly, text, DID or application-layer decoding. Original application layouts are preserved in source JSON; do not decode them at wire offsets. ";
CM_ SG_ 1907 FlowPadding5 "TRANSPORT_CANDIDATE: normal-addressing ISO-TP. PSA-RE bits 8.7-8.0. ";
CM_ SG_ 1907 FirstData6 "TRANSPORT_CANDIDATE: normal-addressing ISO-TP. PSA-RE bits 8.7-8.0. ";
CM_ SG_ 1907 UnknownData7 "TRANSPORT_CANDIDATE: normal-addressing ISO-TP. PSA-RE bits 8.7-8.0. ";
CM_ SG_ 1907 ConsecutiveData7 "TRANSPORT_CANDIDATE: normal-addressing ISO-TP. PSA-RE bits 8.7-8.0. ";
CM_ SG_ 1907 SingleData7 "TRANSPORT_CANDIDATE: normal-addressing ISO-TP. PSA-RE bits 8.7-8.0. ";
CM_ SG_ 1907 FlowPadding4 "TRANSPORT_CANDIDATE: normal-addressing ISO-TP. PSA-RE bits 7.7-7.0. ";
CM_ SG_ 1907 FirstData5 "TRANSPORT_CANDIDATE: normal-addressing ISO-TP. PSA-RE bits 7.7-7.0. ";
CM_ SG_ 1907 UnknownData6 "TRANSPORT_CANDIDATE: normal-addressing ISO-TP. PSA-RE bits 7.7-7.0. ";
CM_ SG_ 1907 ConsecutiveData6 "TRANSPORT_CANDIDATE: normal-addressing ISO-TP. PSA-RE bits 7.7-7.0. ";
CM_ SG_ 1907 SingleData6 "TRANSPORT_CANDIDATE: normal-addressing ISO-TP. PSA-RE bits 7.7-7.0. ";
CM_ SG_ 1907 FlowPadding3 "TRANSPORT_CANDIDATE: normal-addressing ISO-TP. PSA-RE bits 6.7-6.0. ";
CM_ SG_ 1907 FirstData4 "TRANSPORT_CANDIDATE: normal-addressing ISO-TP. PSA-RE bits 6.7-6.0. ";
CM_ SG_ 1907 UnknownData5 "TRANSPORT_CANDIDATE: normal-addressing ISO-TP. PSA-RE bits 6.7-6.0. ";
CM_ SG_ 1907 ConsecutiveData5 "TRANSPORT_CANDIDATE: normal-addressing ISO-TP. PSA-RE bits 6.7-6.0. ";
CM_ SG_ 1907 SingleData5 "TRANSPORT_CANDIDATE: normal-addressing ISO-TP. PSA-RE bits 6.7-6.0. ";
CM_ SG_ 1907 FlowPadding2 "TRANSPORT_CANDIDATE: normal-addressing ISO-TP. PSA-RE bits 5.7-5.0. ";
CM_ SG_ 1907 FirstData3 "TRANSPORT_CANDIDATE: normal-addressing ISO-TP. PSA-RE bits 5.7-5.0. ";
CM_ SG_ 1907 UnknownData4 "TRANSPORT_CANDIDATE: normal-addressing ISO-TP. PSA-RE bits 5.7-5.0. ";
CM_ SG_ 1907 ConsecutiveData4 "TRANSPORT_CANDIDATE: normal-addressing ISO-TP. PSA-RE bits 5.7-5.0. ";
CM_ SG_ 1907 SingleData4 "TRANSPORT_CANDIDATE: normal-addressing ISO-TP. PSA-RE bits 5.7-5.0. ";
CM_ SG_ 1907 FlowPadding1 "TRANSPORT_CANDIDATE: normal-addressing ISO-TP. PSA-RE bits 4.7-4.0. ";
CM_ SG_ 1907 FirstData2 "TRANSPORT_CANDIDATE: normal-addressing ISO-TP. PSA-RE bits 4.7-4.0. ";
CM_ SG_ 1907 UnknownData3 "TRANSPORT_CANDIDATE: normal-addressing ISO-TP. PSA-RE bits 4.7-4.0. ";
CM_ SG_ 1907 ConsecutiveData3 "TRANSPORT_CANDIDATE: normal-addressing ISO-TP. PSA-RE bits 4.7-4.0. ";
CM_ SG_ 1907 SingleData3 "TRANSPORT_CANDIDATE: normal-addressing ISO-TP. PSA-RE bits 4.7-4.0. ";
CM_ SG_ 1907 FirstData1 "TRANSPORT_CANDIDATE: normal-addressing ISO-TP. PSA-RE bits 3.7-3.0. ";
CM_ SG_ 1907 UnknownData2 "TRANSPORT_CANDIDATE: normal-addressing ISO-TP. PSA-RE bits 3.7-3.0. ";
CM_ SG_ 1907 ConsecutiveData2 "TRANSPORT_CANDIDATE: normal-addressing ISO-TP. PSA-RE bits 3.7-3.0. ";
CM_ SG_ 1907 SingleData2 "TRANSPORT_CANDIDATE: normal-addressing ISO-TP. PSA-RE bits 3.7-3.0. ";
CM_ SG_ 1907 SeparationTimeRaw "TRANSPORT_CANDIDATE: normal-addressing ISO-TP. PSA-RE bits 3.7-3.0. Raw STmin code; 0xF1..0xF9 are not milliseconds.";
CM_ SG_ 1907 UnknownData1 "TRANSPORT_CANDIDATE: normal-addressing ISO-TP. PSA-RE bits 2.7-2.0. ";
CM_ SG_ 1907 ConsecutiveData1 "TRANSPORT_CANDIDATE: normal-addressing ISO-TP. PSA-RE bits 2.7-2.0. ";
CM_ SG_ 1907 SingleData1 "TRANSPORT_CANDIDATE: normal-addressing ISO-TP. PSA-RE bits 2.7-2.0. ";
CM_ SG_ 1907 BlockSize "TRANSPORT_CANDIDATE: normal-addressing ISO-TP. PSA-RE bits 2.7-2.0. ";
CM_ SG_ 1907 UnknownPciLow "TRANSPORT_CANDIDATE: normal-addressing ISO-TP. PSA-RE bits 1.3-1.0. ";
CM_ SG_ 1907 FlowStatus "TRANSPORT_CANDIDATE: normal-addressing ISO-TP. PSA-RE bits 1.3-1.0. ";
CM_ SG_ 1907 ConsecutiveSequence "TRANSPORT_CANDIDATE: normal-addressing ISO-TP. PSA-RE bits 1.3-1.0. ";
CM_ SG_ 1907 FirstFrameLength "TRANSPORT_CANDIDATE: normal-addressing ISO-TP. PSA-RE bits 1.3-2.0. 12-bit declared PDU length; not a reassembled value.";
CM_ SG_ 1907 SingleFrameLength "TRANSPORT_CANDIDATE: normal-addressing ISO-TP. PSA-RE bits 1.3-1.0. Declared data length; not a validity check.";
CM_ SG_ 1907 IsoTpFrameType "TRANSPORT_CANDIDATE: normal-addressing ISO-TP. PSA-RE bits 1.7-1.4. PCI high nibble; normal addressing candidate.";
CM_ BO_ 1908 "DATABASE_CANDIDATE: physical interpretation unverified; capture/layout evidence reported separately. INFO-DIV CAN, 125000 bit/s; CAN ID 0x774. PSA-RE title: FAULT_LOG_TBMU. Diagnostic request frame sent on the bus. Source: https://github.com/prototux/PSA-RE/blob/67f7581e7622410efdbb29c7eda3b86982b9b450/buses/AEE2010.full/LS.INFO-DIV/774.yml. Source sender alternatives: MDS; physical TX/gateway forwarding not verified. WIRE ISO-TP ONLY: normal addressing candidate, maximum Classical CAN DLC 8; actual DLC may be shorter. Data includes padding. No reassembly, text, DID or application-layer decoding. Original application layouts are preserved in source JSON; do not decode them at wire offsets. ";
CM_ SG_ 1908 FlowPadding5 "TRANSPORT_CANDIDATE: normal-addressing ISO-TP. PSA-RE bits 8.7-8.0. ";
CM_ SG_ 1908 FirstData6 "TRANSPORT_CANDIDATE: normal-addressing ISO-TP. PSA-RE bits 8.7-8.0. ";
CM_ SG_ 1908 UnknownData7 "TRANSPORT_CANDIDATE: normal-addressing ISO-TP. PSA-RE bits 8.7-8.0. ";
CM_ SG_ 1908 ConsecutiveData7 "TRANSPORT_CANDIDATE: normal-addressing ISO-TP. PSA-RE bits 8.7-8.0. ";
CM_ SG_ 1908 SingleData7 "TRANSPORT_CANDIDATE: normal-addressing ISO-TP. PSA-RE bits 8.7-8.0. ";
CM_ SG_ 1908 FlowPadding4 "TRANSPORT_CANDIDATE: normal-addressing ISO-TP. PSA-RE bits 7.7-7.0. ";
CM_ SG_ 1908 FirstData5 "TRANSPORT_CANDIDATE: normal-addressing ISO-TP. PSA-RE bits 7.7-7.0. ";
CM_ SG_ 1908 UnknownData6 "TRANSPORT_CANDIDATE: normal-addressing ISO-TP. PSA-RE bits 7.7-7.0. ";
CM_ SG_ 1908 ConsecutiveData6 "TRANSPORT_CANDIDATE: normal-addressing ISO-TP. PSA-RE bits 7.7-7.0. ";
CM_ SG_ 1908 SingleData6 "TRANSPORT_CANDIDATE: normal-addressing ISO-TP. PSA-RE bits 7.7-7.0. ";
CM_ SG_ 1908 FlowPadding3 "TRANSPORT_CANDIDATE: normal-addressing ISO-TP. PSA-RE bits 6.7-6.0. ";
CM_ SG_ 1908 FirstData4 "TRANSPORT_CANDIDATE: normal-addressing ISO-TP. PSA-RE bits 6.7-6.0. ";
CM_ SG_ 1908 UnknownData5 "TRANSPORT_CANDIDATE: normal-addressing ISO-TP. PSA-RE bits 6.7-6.0. ";
CM_ SG_ 1908 ConsecutiveData5 "TRANSPORT_CANDIDATE: normal-addressing ISO-TP. PSA-RE bits 6.7-6.0. ";
CM_ SG_ 1908 SingleData5 "TRANSPORT_CANDIDATE: normal-addressing ISO-TP. PSA-RE bits 6.7-6.0. ";
CM_ SG_ 1908 FlowPadding2 "TRANSPORT_CANDIDATE: normal-addressing ISO-TP. PSA-RE bits 5.7-5.0. ";
CM_ SG_ 1908 FirstData3 "TRANSPORT_CANDIDATE: normal-addressing ISO-TP. PSA-RE bits 5.7-5.0. ";
CM_ SG_ 1908 UnknownData4 "TRANSPORT_CANDIDATE: normal-addressing ISO-TP. PSA-RE bits 5.7-5.0. ";
CM_ SG_ 1908 ConsecutiveData4 "TRANSPORT_CANDIDATE: normal-addressing ISO-TP. PSA-RE bits 5.7-5.0. ";
CM_ SG_ 1908 SingleData4 "TRANSPORT_CANDIDATE: normal-addressing ISO-TP. PSA-RE bits 5.7-5.0. ";
CM_ SG_ 1908 FlowPadding1 "TRANSPORT_CANDIDATE: normal-addressing ISO-TP. PSA-RE bits 4.7-4.0. ";
CM_ SG_ 1908 FirstData2 "TRANSPORT_CANDIDATE: normal-addressing ISO-TP. PSA-RE bits 4.7-4.0. ";
CM_ SG_ 1908 UnknownData3 "TRANSPORT_CANDIDATE: normal-addressing ISO-TP. PSA-RE bits 4.7-4.0. ";
CM_ SG_ 1908 ConsecutiveData3 "TRANSPORT_CANDIDATE: normal-addressing ISO-TP. PSA-RE bits 4.7-4.0. ";
CM_ SG_ 1908 SingleData3 "TRANSPORT_CANDIDATE: normal-addressing ISO-TP. PSA-RE bits 4.7-4.0. ";
CM_ SG_ 1908 FirstData1 "TRANSPORT_CANDIDATE: normal-addressing ISO-TP. PSA-RE bits 3.7-3.0. ";
CM_ SG_ 1908 UnknownData2 "TRANSPORT_CANDIDATE: normal-addressing ISO-TP. PSA-RE bits 3.7-3.0. ";
CM_ SG_ 1908 ConsecutiveData2 "TRANSPORT_CANDIDATE: normal-addressing ISO-TP. PSA-RE bits 3.7-3.0. ";
CM_ SG_ 1908 SingleData2 "TRANSPORT_CANDIDATE: normal-addressing ISO-TP. PSA-RE bits 3.7-3.0. ";
CM_ SG_ 1908 SeparationTimeRaw "TRANSPORT_CANDIDATE: normal-addressing ISO-TP. PSA-RE bits 3.7-3.0. Raw STmin code; 0xF1..0xF9 are not milliseconds.";
CM_ SG_ 1908 UnknownData1 "TRANSPORT_CANDIDATE: normal-addressing ISO-TP. PSA-RE bits 2.7-2.0. ";
CM_ SG_ 1908 ConsecutiveData1 "TRANSPORT_CANDIDATE: normal-addressing ISO-TP. PSA-RE bits 2.7-2.0. ";
CM_ SG_ 1908 SingleData1 "TRANSPORT_CANDIDATE: normal-addressing ISO-TP. PSA-RE bits 2.7-2.0. ";
CM_ SG_ 1908 BlockSize "TRANSPORT_CANDIDATE: normal-addressing ISO-TP. PSA-RE bits 2.7-2.0. ";
CM_ SG_ 1908 UnknownPciLow "TRANSPORT_CANDIDATE: normal-addressing ISO-TP. PSA-RE bits 1.3-1.0. ";
CM_ SG_ 1908 FlowStatus "TRANSPORT_CANDIDATE: normal-addressing ISO-TP. PSA-RE bits 1.3-1.0. ";
CM_ SG_ 1908 ConsecutiveSequence "TRANSPORT_CANDIDATE: normal-addressing ISO-TP. PSA-RE bits 1.3-1.0. ";
CM_ SG_ 1908 FirstFrameLength "TRANSPORT_CANDIDATE: normal-addressing ISO-TP. PSA-RE bits 1.3-2.0. 12-bit declared PDU length; not a reassembled value.";
CM_ SG_ 1908 SingleFrameLength "TRANSPORT_CANDIDATE: normal-addressing ISO-TP. PSA-RE bits 1.3-1.0. Declared data length; not a validity check.";
CM_ SG_ 1908 IsoTpFrameType "TRANSPORT_CANDIDATE: normal-addressing ISO-TP. PSA-RE bits 1.7-1.4. PCI high nibble; normal addressing candidate.";
CM_ BO_ 1910 "DATABASE_CANDIDATE: physical interpretation unverified; capture/layout evidence reported separately. INFO-DIV CAN, 125000 bit/s; CAN ID 0x776. PSA-RE title: FAULT_LOG_ARTIV. Diagnostic request sent to the BTT module by the body computer or the diagnostic socket interface module (MDS). Source: https://github.com/prototux/PSA-RE/blob/67f7581e7622410efdbb29c7eda3b86982b9b450/buses/AEE2010.full/LS.INFO-DIV/776.yml. Source sender alternatives: BSI,MDS; physical TX/gateway forwarding not verified. ";
CM_ SG_ 1910 DiagnosticData "DATABASE_CANDIDATE: physical interpretation unverified; capture/layout evidence reported separately. PSA-RE bits 1.7-8.0. Diagnostic data";
CM_ BO_ 1912 "DATABASE_CANDIDATE: physical interpretation unverified; capture/layout evidence reported separately. INFO-DIV CAN, 125000 bit/s; CAN ID 0x778. PSA-RE title: FAULT_LOG_CAAR_RAW. Diagnostic request addressed to the CLR ECU. Source: https://github.com/prototux/PSA-RE/blob/67f7581e7622410efdbb29c7eda3b86982b9b450/buses/AEE2010.full/LS.INFO-DIV/778.yml. Source sender alternatives: MDS; physical TX/gateway forwarding not verified. WIRE ISO-TP ONLY: normal addressing candidate, maximum Classical CAN DLC 8; actual DLC may be shorter. Data includes padding. No reassembly, text, DID or application-layer decoding. Original application layouts are preserved in source JSON; do not decode them at wire offsets. ";
CM_ SG_ 1912 FlowPadding5 "TRANSPORT_CANDIDATE: normal-addressing ISO-TP. PSA-RE bits 8.7-8.0. ";
CM_ SG_ 1912 FirstData6 "TRANSPORT_CANDIDATE: normal-addressing ISO-TP. PSA-RE bits 8.7-8.0. ";
CM_ SG_ 1912 UnknownData7 "TRANSPORT_CANDIDATE: normal-addressing ISO-TP. PSA-RE bits 8.7-8.0. ";
CM_ SG_ 1912 ConsecutiveData7 "TRANSPORT_CANDIDATE: normal-addressing ISO-TP. PSA-RE bits 8.7-8.0. ";
CM_ SG_ 1912 SingleData7 "TRANSPORT_CANDIDATE: normal-addressing ISO-TP. PSA-RE bits 8.7-8.0. ";
CM_ SG_ 1912 FlowPadding4 "TRANSPORT_CANDIDATE: normal-addressing ISO-TP. PSA-RE bits 7.7-7.0. ";
CM_ SG_ 1912 FirstData5 "TRANSPORT_CANDIDATE: normal-addressing ISO-TP. PSA-RE bits 7.7-7.0. ";
CM_ SG_ 1912 UnknownData6 "TRANSPORT_CANDIDATE: normal-addressing ISO-TP. PSA-RE bits 7.7-7.0. ";
CM_ SG_ 1912 ConsecutiveData6 "TRANSPORT_CANDIDATE: normal-addressing ISO-TP. PSA-RE bits 7.7-7.0. ";
CM_ SG_ 1912 SingleData6 "TRANSPORT_CANDIDATE: normal-addressing ISO-TP. PSA-RE bits 7.7-7.0. ";
CM_ SG_ 1912 FlowPadding3 "TRANSPORT_CANDIDATE: normal-addressing ISO-TP. PSA-RE bits 6.7-6.0. ";
CM_ SG_ 1912 FirstData4 "TRANSPORT_CANDIDATE: normal-addressing ISO-TP. PSA-RE bits 6.7-6.0. ";
CM_ SG_ 1912 UnknownData5 "TRANSPORT_CANDIDATE: normal-addressing ISO-TP. PSA-RE bits 6.7-6.0. ";
CM_ SG_ 1912 ConsecutiveData5 "TRANSPORT_CANDIDATE: normal-addressing ISO-TP. PSA-RE bits 6.7-6.0. ";
CM_ SG_ 1912 SingleData5 "TRANSPORT_CANDIDATE: normal-addressing ISO-TP. PSA-RE bits 6.7-6.0. ";
CM_ SG_ 1912 FlowPadding2 "TRANSPORT_CANDIDATE: normal-addressing ISO-TP. PSA-RE bits 5.7-5.0. ";
CM_ SG_ 1912 FirstData3 "TRANSPORT_CANDIDATE: normal-addressing ISO-TP. PSA-RE bits 5.7-5.0. ";
CM_ SG_ 1912 UnknownData4 "TRANSPORT_CANDIDATE: normal-addressing ISO-TP. PSA-RE bits 5.7-5.0. ";
CM_ SG_ 1912 ConsecutiveData4 "TRANSPORT_CANDIDATE: normal-addressing ISO-TP. PSA-RE bits 5.7-5.0. ";
CM_ SG_ 1912 SingleData4 "TRANSPORT_CANDIDATE: normal-addressing ISO-TP. PSA-RE bits 5.7-5.0. ";
CM_ SG_ 1912 FlowPadding1 "TRANSPORT_CANDIDATE: normal-addressing ISO-TP. PSA-RE bits 4.7-4.0. ";
CM_ SG_ 1912 FirstData2 "TRANSPORT_CANDIDATE: normal-addressing ISO-TP. PSA-RE bits 4.7-4.0. ";
CM_ SG_ 1912 UnknownData3 "TRANSPORT_CANDIDATE: normal-addressing ISO-TP. PSA-RE bits 4.7-4.0. ";
CM_ SG_ 1912 ConsecutiveData3 "TRANSPORT_CANDIDATE: normal-addressing ISO-TP. PSA-RE bits 4.7-4.0. ";
CM_ SG_ 1912 SingleData3 "TRANSPORT_CANDIDATE: normal-addressing ISO-TP. PSA-RE bits 4.7-4.0. ";
CM_ SG_ 1912 FirstData1 "TRANSPORT_CANDIDATE: normal-addressing ISO-TP. PSA-RE bits 3.7-3.0. ";
CM_ SG_ 1912 UnknownData2 "TRANSPORT_CANDIDATE: normal-addressing ISO-TP. PSA-RE bits 3.7-3.0. ";
CM_ SG_ 1912 ConsecutiveData2 "TRANSPORT_CANDIDATE: normal-addressing ISO-TP. PSA-RE bits 3.7-3.0. ";
CM_ SG_ 1912 SingleData2 "TRANSPORT_CANDIDATE: normal-addressing ISO-TP. PSA-RE bits 3.7-3.0. ";
CM_ SG_ 1912 SeparationTimeRaw "TRANSPORT_CANDIDATE: normal-addressing ISO-TP. PSA-RE bits 3.7-3.0. Raw STmin code; 0xF1..0xF9 are not milliseconds.";
CM_ SG_ 1912 UnknownData1 "TRANSPORT_CANDIDATE: normal-addressing ISO-TP. PSA-RE bits 2.7-2.0. ";
CM_ SG_ 1912 ConsecutiveData1 "TRANSPORT_CANDIDATE: normal-addressing ISO-TP. PSA-RE bits 2.7-2.0. ";
CM_ SG_ 1912 SingleData1 "TRANSPORT_CANDIDATE: normal-addressing ISO-TP. PSA-RE bits 2.7-2.0. ";
CM_ SG_ 1912 BlockSize "TRANSPORT_CANDIDATE: normal-addressing ISO-TP. PSA-RE bits 2.7-2.0. ";
CM_ SG_ 1912 UnknownPciLow "TRANSPORT_CANDIDATE: normal-addressing ISO-TP. PSA-RE bits 1.3-1.0. ";
CM_ SG_ 1912 FlowStatus "TRANSPORT_CANDIDATE: normal-addressing ISO-TP. PSA-RE bits 1.3-1.0. ";
CM_ SG_ 1912 ConsecutiveSequence "TRANSPORT_CANDIDATE: normal-addressing ISO-TP. PSA-RE bits 1.3-1.0. ";
CM_ SG_ 1912 FirstFrameLength "TRANSPORT_CANDIDATE: normal-addressing ISO-TP. PSA-RE bits 1.3-2.0. 12-bit declared PDU length; not a reassembled value.";
CM_ SG_ 1912 SingleFrameLength "TRANSPORT_CANDIDATE: normal-addressing ISO-TP. PSA-RE bits 1.3-1.0. Declared data length; not a validity check.";
CM_ SG_ 1912 IsoTpFrameType "TRANSPORT_CANDIDATE: normal-addressing ISO-TP. PSA-RE bits 1.7-1.4. PCI high nibble; normal addressing candidate.";
CM_ BO_ 1915 "DATABASE_CANDIDATE: physical interpretation unverified; capture/layout evidence reported separately. INFO-DIV CAN, 125000 bit/s; CAN ID 0x77B. PSA-RE title: FAULT_LOG_BEBA_RAW. Diagnostic request addressed to the FMUX ECU. Source: https://github.com/prototux/PSA-RE/blob/67f7581e7622410efdbb29c7eda3b86982b9b450/buses/AEE2010.full/LS.INFO-DIV/77B.yml. Source sender alternatives: BSI,MDS; physical TX/gateway forwarding not verified. WIRE ISO-TP ONLY: normal addressing candidate, maximum Classical CAN DLC 8; actual DLC may be shorter. Data includes padding. No reassembly, text, DID or application-layer decoding. Original application layouts are preserved in source JSON; do not decode them at wire offsets. ";
CM_ SG_ 1915 FlowPadding5 "TRANSPORT_CANDIDATE: normal-addressing ISO-TP. PSA-RE bits 8.7-8.0. ";
CM_ SG_ 1915 FirstData6 "TRANSPORT_CANDIDATE: normal-addressing ISO-TP. PSA-RE bits 8.7-8.0. ";
CM_ SG_ 1915 UnknownData7 "TRANSPORT_CANDIDATE: normal-addressing ISO-TP. PSA-RE bits 8.7-8.0. ";
CM_ SG_ 1915 ConsecutiveData7 "TRANSPORT_CANDIDATE: normal-addressing ISO-TP. PSA-RE bits 8.7-8.0. ";
CM_ SG_ 1915 SingleData7 "TRANSPORT_CANDIDATE: normal-addressing ISO-TP. PSA-RE bits 8.7-8.0. ";
CM_ SG_ 1915 FlowPadding4 "TRANSPORT_CANDIDATE: normal-addressing ISO-TP. PSA-RE bits 7.7-7.0. ";
CM_ SG_ 1915 FirstData5 "TRANSPORT_CANDIDATE: normal-addressing ISO-TP. PSA-RE bits 7.7-7.0. ";
CM_ SG_ 1915 UnknownData6 "TRANSPORT_CANDIDATE: normal-addressing ISO-TP. PSA-RE bits 7.7-7.0. ";
CM_ SG_ 1915 ConsecutiveData6 "TRANSPORT_CANDIDATE: normal-addressing ISO-TP. PSA-RE bits 7.7-7.0. ";
CM_ SG_ 1915 SingleData6 "TRANSPORT_CANDIDATE: normal-addressing ISO-TP. PSA-RE bits 7.7-7.0. ";
CM_ SG_ 1915 FlowPadding3 "TRANSPORT_CANDIDATE: normal-addressing ISO-TP. PSA-RE bits 6.7-6.0. ";
CM_ SG_ 1915 FirstData4 "TRANSPORT_CANDIDATE: normal-addressing ISO-TP. PSA-RE bits 6.7-6.0. ";
CM_ SG_ 1915 UnknownData5 "TRANSPORT_CANDIDATE: normal-addressing ISO-TP. PSA-RE bits 6.7-6.0. ";
CM_ SG_ 1915 ConsecutiveData5 "TRANSPORT_CANDIDATE: normal-addressing ISO-TP. PSA-RE bits 6.7-6.0. ";
CM_ SG_ 1915 SingleData5 "TRANSPORT_CANDIDATE: normal-addressing ISO-TP. PSA-RE bits 6.7-6.0. ";
CM_ SG_ 1915 FlowPadding2 "TRANSPORT_CANDIDATE: normal-addressing ISO-TP. PSA-RE bits 5.7-5.0. ";
CM_ SG_ 1915 FirstData3 "TRANSPORT_CANDIDATE: normal-addressing ISO-TP. PSA-RE bits 5.7-5.0. ";
CM_ SG_ 1915 UnknownData4 "TRANSPORT_CANDIDATE: normal-addressing ISO-TP. PSA-RE bits 5.7-5.0. ";
CM_ SG_ 1915 ConsecutiveData4 "TRANSPORT_CANDIDATE: normal-addressing ISO-TP. PSA-RE bits 5.7-5.0. ";
CM_ SG_ 1915 SingleData4 "TRANSPORT_CANDIDATE: normal-addressing ISO-TP. PSA-RE bits 5.7-5.0. ";
CM_ SG_ 1915 FlowPadding1 "TRANSPORT_CANDIDATE: normal-addressing ISO-TP. PSA-RE bits 4.7-4.0. ";
CM_ SG_ 1915 FirstData2 "TRANSPORT_CANDIDATE: normal-addressing ISO-TP. PSA-RE bits 4.7-4.0. ";
CM_ SG_ 1915 UnknownData3 "TRANSPORT_CANDIDATE: normal-addressing ISO-TP. PSA-RE bits 4.7-4.0. ";
CM_ SG_ 1915 ConsecutiveData3 "TRANSPORT_CANDIDATE: normal-addressing ISO-TP. PSA-RE bits 4.7-4.0. ";
CM_ SG_ 1915 SingleData3 "TRANSPORT_CANDIDATE: normal-addressing ISO-TP. PSA-RE bits 4.7-4.0. ";
CM_ SG_ 1915 FirstData1 "TRANSPORT_CANDIDATE: normal-addressing ISO-TP. PSA-RE bits 3.7-3.0. ";
CM_ SG_ 1915 UnknownData2 "TRANSPORT_CANDIDATE: normal-addressing ISO-TP. PSA-RE bits 3.7-3.0. ";
CM_ SG_ 1915 ConsecutiveData2 "TRANSPORT_CANDIDATE: normal-addressing ISO-TP. PSA-RE bits 3.7-3.0. ";
CM_ SG_ 1915 SingleData2 "TRANSPORT_CANDIDATE: normal-addressing ISO-TP. PSA-RE bits 3.7-3.0. ";
CM_ SG_ 1915 SeparationTimeRaw "TRANSPORT_CANDIDATE: normal-addressing ISO-TP. PSA-RE bits 3.7-3.0. Raw STmin code; 0xF1..0xF9 are not milliseconds.";
CM_ SG_ 1915 UnknownData1 "TRANSPORT_CANDIDATE: normal-addressing ISO-TP. PSA-RE bits 2.7-2.0. ";
CM_ SG_ 1915 ConsecutiveData1 "TRANSPORT_CANDIDATE: normal-addressing ISO-TP. PSA-RE bits 2.7-2.0. ";
CM_ SG_ 1915 SingleData1 "TRANSPORT_CANDIDATE: normal-addressing ISO-TP. PSA-RE bits 2.7-2.0. ";
CM_ SG_ 1915 BlockSize "TRANSPORT_CANDIDATE: normal-addressing ISO-TP. PSA-RE bits 2.7-2.0. ";
CM_ SG_ 1915 UnknownPciLow "TRANSPORT_CANDIDATE: normal-addressing ISO-TP. PSA-RE bits 1.3-1.0. ";
CM_ SG_ 1915 FlowStatus "TRANSPORT_CANDIDATE: normal-addressing ISO-TP. PSA-RE bits 1.3-1.0. ";
CM_ SG_ 1915 ConsecutiveSequence "TRANSPORT_CANDIDATE: normal-addressing ISO-TP. PSA-RE bits 1.3-1.0. ";
CM_ SG_ 1915 FirstFrameLength "TRANSPORT_CANDIDATE: normal-addressing ISO-TP. PSA-RE bits 1.3-2.0. 12-bit declared PDU length; not a reassembled value.";
CM_ SG_ 1915 SingleFrameLength "TRANSPORT_CANDIDATE: normal-addressing ISO-TP. PSA-RE bits 1.3-1.0. Declared data length; not a validity check.";
CM_ SG_ 1915 IsoTpFrameType "TRANSPORT_CANDIDATE: normal-addressing ISO-TP. PSA-RE bits 1.7-1.4. PCI high nibble; normal addressing candidate.";
CM_ BO_ 1916 "DATABASE_CANDIDATE: physical interpretation unverified; capture/layout evidence reported separately. INFO-DIV CAN, 125000 bit/s; CAN ID 0x77C. PSA-RE title: FAULT_LOG_DMTR. Diagnostic request addressed to the MDS ECU. Source: https://github.com/prototux/PSA-RE/blob/67f7581e7622410efdbb29c7eda3b86982b9b450/buses/AEE2010.full/LS.INFO-DIV/77C.yml. Source sender alternatives: BSI; physical TX/gateway forwarding not verified. WIRE ISO-TP ONLY: normal addressing candidate, maximum Classical CAN DLC 8; actual DLC may be shorter. Data includes padding. No reassembly, text, DID or application-layer decoding. Original application layouts are preserved in source JSON; do not decode them at wire offsets. ";
CM_ SG_ 1916 FlowPadding5 "TRANSPORT_CANDIDATE: normal-addressing ISO-TP. PSA-RE bits 8.7-8.0. ";
CM_ SG_ 1916 FirstData6 "TRANSPORT_CANDIDATE: normal-addressing ISO-TP. PSA-RE bits 8.7-8.0. ";
CM_ SG_ 1916 UnknownData7 "TRANSPORT_CANDIDATE: normal-addressing ISO-TP. PSA-RE bits 8.7-8.0. ";
CM_ SG_ 1916 ConsecutiveData7 "TRANSPORT_CANDIDATE: normal-addressing ISO-TP. PSA-RE bits 8.7-8.0. ";
CM_ SG_ 1916 SingleData7 "TRANSPORT_CANDIDATE: normal-addressing ISO-TP. PSA-RE bits 8.7-8.0. ";
CM_ SG_ 1916 FlowPadding4 "TRANSPORT_CANDIDATE: normal-addressing ISO-TP. PSA-RE bits 7.7-7.0. ";
CM_ SG_ 1916 FirstData5 "TRANSPORT_CANDIDATE: normal-addressing ISO-TP. PSA-RE bits 7.7-7.0. ";
CM_ SG_ 1916 UnknownData6 "TRANSPORT_CANDIDATE: normal-addressing ISO-TP. PSA-RE bits 7.7-7.0. ";
CM_ SG_ 1916 ConsecutiveData6 "TRANSPORT_CANDIDATE: normal-addressing ISO-TP. PSA-RE bits 7.7-7.0. ";
CM_ SG_ 1916 SingleData6 "TRANSPORT_CANDIDATE: normal-addressing ISO-TP. PSA-RE bits 7.7-7.0. ";
CM_ SG_ 1916 FlowPadding3 "TRANSPORT_CANDIDATE: normal-addressing ISO-TP. PSA-RE bits 6.7-6.0. ";
CM_ SG_ 1916 FirstData4 "TRANSPORT_CANDIDATE: normal-addressing ISO-TP. PSA-RE bits 6.7-6.0. ";
CM_ SG_ 1916 UnknownData5 "TRANSPORT_CANDIDATE: normal-addressing ISO-TP. PSA-RE bits 6.7-6.0. ";
CM_ SG_ 1916 ConsecutiveData5 "TRANSPORT_CANDIDATE: normal-addressing ISO-TP. PSA-RE bits 6.7-6.0. ";
CM_ SG_ 1916 SingleData5 "TRANSPORT_CANDIDATE: normal-addressing ISO-TP. PSA-RE bits 6.7-6.0. ";
CM_ SG_ 1916 FlowPadding2 "TRANSPORT_CANDIDATE: normal-addressing ISO-TP. PSA-RE bits 5.7-5.0. ";
CM_ SG_ 1916 FirstData3 "TRANSPORT_CANDIDATE: normal-addressing ISO-TP. PSA-RE bits 5.7-5.0. ";
CM_ SG_ 1916 UnknownData4 "TRANSPORT_CANDIDATE: normal-addressing ISO-TP. PSA-RE bits 5.7-5.0. ";
CM_ SG_ 1916 ConsecutiveData4 "TRANSPORT_CANDIDATE: normal-addressing ISO-TP. PSA-RE bits 5.7-5.0. ";
CM_ SG_ 1916 SingleData4 "TRANSPORT_CANDIDATE: normal-addressing ISO-TP. PSA-RE bits 5.7-5.0. ";
CM_ SG_ 1916 FlowPadding1 "TRANSPORT_CANDIDATE: normal-addressing ISO-TP. PSA-RE bits 4.7-4.0. ";
CM_ SG_ 1916 FirstData2 "TRANSPORT_CANDIDATE: normal-addressing ISO-TP. PSA-RE bits 4.7-4.0. ";
CM_ SG_ 1916 UnknownData3 "TRANSPORT_CANDIDATE: normal-addressing ISO-TP. PSA-RE bits 4.7-4.0. ";
CM_ SG_ 1916 ConsecutiveData3 "TRANSPORT_CANDIDATE: normal-addressing ISO-TP. PSA-RE bits 4.7-4.0. ";
CM_ SG_ 1916 SingleData3 "TRANSPORT_CANDIDATE: normal-addressing ISO-TP. PSA-RE bits 4.7-4.0. ";
CM_ SG_ 1916 FirstData1 "TRANSPORT_CANDIDATE: normal-addressing ISO-TP. PSA-RE bits 3.7-3.0. ";
CM_ SG_ 1916 UnknownData2 "TRANSPORT_CANDIDATE: normal-addressing ISO-TP. PSA-RE bits 3.7-3.0. ";
CM_ SG_ 1916 ConsecutiveData2 "TRANSPORT_CANDIDATE: normal-addressing ISO-TP. PSA-RE bits 3.7-3.0. ";
CM_ SG_ 1916 SingleData2 "TRANSPORT_CANDIDATE: normal-addressing ISO-TP. PSA-RE bits 3.7-3.0. ";
CM_ SG_ 1916 SeparationTimeRaw "TRANSPORT_CANDIDATE: normal-addressing ISO-TP. PSA-RE bits 3.7-3.0. Raw STmin code; 0xF1..0xF9 are not milliseconds.";
CM_ SG_ 1916 UnknownData1 "TRANSPORT_CANDIDATE: normal-addressing ISO-TP. PSA-RE bits 2.7-2.0. ";
CM_ SG_ 1916 ConsecutiveData1 "TRANSPORT_CANDIDATE: normal-addressing ISO-TP. PSA-RE bits 2.7-2.0. ";
CM_ SG_ 1916 SingleData1 "TRANSPORT_CANDIDATE: normal-addressing ISO-TP. PSA-RE bits 2.7-2.0. ";
CM_ SG_ 1916 BlockSize "TRANSPORT_CANDIDATE: normal-addressing ISO-TP. PSA-RE bits 2.7-2.0. ";
CM_ SG_ 1916 UnknownPciLow "TRANSPORT_CANDIDATE: normal-addressing ISO-TP. PSA-RE bits 1.3-1.0. ";
CM_ SG_ 1916 FlowStatus "TRANSPORT_CANDIDATE: normal-addressing ISO-TP. PSA-RE bits 1.3-1.0. ";
CM_ SG_ 1916 ConsecutiveSequence "TRANSPORT_CANDIDATE: normal-addressing ISO-TP. PSA-RE bits 1.3-1.0. ";
CM_ SG_ 1916 FirstFrameLength "TRANSPORT_CANDIDATE: normal-addressing ISO-TP. PSA-RE bits 1.3-2.0. 12-bit declared PDU length; not a reassembled value.";
CM_ SG_ 1916 SingleFrameLength "TRANSPORT_CANDIDATE: normal-addressing ISO-TP. PSA-RE bits 1.3-1.0. Declared data length; not a validity check.";
CM_ SG_ 1916 IsoTpFrameType "TRANSPORT_CANDIDATE: normal-addressing ISO-TP. PSA-RE bits 1.7-1.4. PCI high nibble; normal addressing candidate.";
CM_ BO_ 1917 "DATABASE_CANDIDATE: physical interpretation unverified; capture/layout evidence reported separately. INFO-DIV CAN, 125000 bit/s; CAN ID 0x77D. PSA-RE title: FAULT_LOG_ASR_PLUS_RAW. Diagnostic request addressed to the AMPLI ECU. Source: https://github.com/prototux/PSA-RE/blob/67f7581e7622410efdbb29c7eda3b86982b9b450/buses/AEE2010.full/LS.INFO-DIV/77D.yml. Source sender alternatives: BSI,MDS; physical TX/gateway forwarding not verified. WIRE ISO-TP ONLY: normal addressing candidate, maximum Classical CAN DLC 8; actual DLC may be shorter. Data includes padding. No reassembly, text, DID or application-layer decoding. Original application layouts are preserved in source JSON; do not decode them at wire offsets. ";
CM_ SG_ 1917 FlowPadding5 "TRANSPORT_CANDIDATE: normal-addressing ISO-TP. PSA-RE bits 8.7-8.0. ";
CM_ SG_ 1917 FirstData6 "TRANSPORT_CANDIDATE: normal-addressing ISO-TP. PSA-RE bits 8.7-8.0. ";
CM_ SG_ 1917 UnknownData7 "TRANSPORT_CANDIDATE: normal-addressing ISO-TP. PSA-RE bits 8.7-8.0. ";
CM_ SG_ 1917 ConsecutiveData7 "TRANSPORT_CANDIDATE: normal-addressing ISO-TP. PSA-RE bits 8.7-8.0. ";
CM_ SG_ 1917 SingleData7 "TRANSPORT_CANDIDATE: normal-addressing ISO-TP. PSA-RE bits 8.7-8.0. ";
CM_ SG_ 1917 FlowPadding4 "TRANSPORT_CANDIDATE: normal-addressing ISO-TP. PSA-RE bits 7.7-7.0. ";
CM_ SG_ 1917 FirstData5 "TRANSPORT_CANDIDATE: normal-addressing ISO-TP. PSA-RE bits 7.7-7.0. ";
CM_ SG_ 1917 UnknownData6 "TRANSPORT_CANDIDATE: normal-addressing ISO-TP. PSA-RE bits 7.7-7.0. ";
CM_ SG_ 1917 ConsecutiveData6 "TRANSPORT_CANDIDATE: normal-addressing ISO-TP. PSA-RE bits 7.7-7.0. ";
CM_ SG_ 1917 SingleData6 "TRANSPORT_CANDIDATE: normal-addressing ISO-TP. PSA-RE bits 7.7-7.0. ";
CM_ SG_ 1917 FlowPadding3 "TRANSPORT_CANDIDATE: normal-addressing ISO-TP. PSA-RE bits 6.7-6.0. ";
CM_ SG_ 1917 FirstData4 "TRANSPORT_CANDIDATE: normal-addressing ISO-TP. PSA-RE bits 6.7-6.0. ";
CM_ SG_ 1917 UnknownData5 "TRANSPORT_CANDIDATE: normal-addressing ISO-TP. PSA-RE bits 6.7-6.0. ";
CM_ SG_ 1917 ConsecutiveData5 "TRANSPORT_CANDIDATE: normal-addressing ISO-TP. PSA-RE bits 6.7-6.0. ";
CM_ SG_ 1917 SingleData5 "TRANSPORT_CANDIDATE: normal-addressing ISO-TP. PSA-RE bits 6.7-6.0. ";
CM_ SG_ 1917 FlowPadding2 "TRANSPORT_CANDIDATE: normal-addressing ISO-TP. PSA-RE bits 5.7-5.0. ";
CM_ SG_ 1917 FirstData3 "TRANSPORT_CANDIDATE: normal-addressing ISO-TP. PSA-RE bits 5.7-5.0. ";
CM_ SG_ 1917 UnknownData4 "TRANSPORT_CANDIDATE: normal-addressing ISO-TP. PSA-RE bits 5.7-5.0. ";
CM_ SG_ 1917 ConsecutiveData4 "TRANSPORT_CANDIDATE: normal-addressing ISO-TP. PSA-RE bits 5.7-5.0. ";
CM_ SG_ 1917 SingleData4 "TRANSPORT_CANDIDATE: normal-addressing ISO-TP. PSA-RE bits 5.7-5.0. ";
CM_ SG_ 1917 FlowPadding1 "TRANSPORT_CANDIDATE: normal-addressing ISO-TP. PSA-RE bits 4.7-4.0. ";
CM_ SG_ 1917 FirstData2 "TRANSPORT_CANDIDATE: normal-addressing ISO-TP. PSA-RE bits 4.7-4.0. ";
CM_ SG_ 1917 UnknownData3 "TRANSPORT_CANDIDATE: normal-addressing ISO-TP. PSA-RE bits 4.7-4.0. ";
CM_ SG_ 1917 ConsecutiveData3 "TRANSPORT_CANDIDATE: normal-addressing ISO-TP. PSA-RE bits 4.7-4.0. ";
CM_ SG_ 1917 SingleData3 "TRANSPORT_CANDIDATE: normal-addressing ISO-TP. PSA-RE bits 4.7-4.0. ";
CM_ SG_ 1917 FirstData1 "TRANSPORT_CANDIDATE: normal-addressing ISO-TP. PSA-RE bits 3.7-3.0. ";
CM_ SG_ 1917 UnknownData2 "TRANSPORT_CANDIDATE: normal-addressing ISO-TP. PSA-RE bits 3.7-3.0. ";
CM_ SG_ 1917 ConsecutiveData2 "TRANSPORT_CANDIDATE: normal-addressing ISO-TP. PSA-RE bits 3.7-3.0. ";
CM_ SG_ 1917 SingleData2 "TRANSPORT_CANDIDATE: normal-addressing ISO-TP. PSA-RE bits 3.7-3.0. ";
CM_ SG_ 1917 SeparationTimeRaw "TRANSPORT_CANDIDATE: normal-addressing ISO-TP. PSA-RE bits 3.7-3.0. Raw STmin code; 0xF1..0xF9 are not milliseconds.";
CM_ SG_ 1917 UnknownData1 "TRANSPORT_CANDIDATE: normal-addressing ISO-TP. PSA-RE bits 2.7-2.0. ";
CM_ SG_ 1917 ConsecutiveData1 "TRANSPORT_CANDIDATE: normal-addressing ISO-TP. PSA-RE bits 2.7-2.0. ";
CM_ SG_ 1917 SingleData1 "TRANSPORT_CANDIDATE: normal-addressing ISO-TP. PSA-RE bits 2.7-2.0. ";
CM_ SG_ 1917 BlockSize "TRANSPORT_CANDIDATE: normal-addressing ISO-TP. PSA-RE bits 2.7-2.0. ";
CM_ SG_ 1917 UnknownPciLow "TRANSPORT_CANDIDATE: normal-addressing ISO-TP. PSA-RE bits 1.3-1.0. ";
CM_ SG_ 1917 FlowStatus "TRANSPORT_CANDIDATE: normal-addressing ISO-TP. PSA-RE bits 1.3-1.0. ";
CM_ SG_ 1917 ConsecutiveSequence "TRANSPORT_CANDIDATE: normal-addressing ISO-TP. PSA-RE bits 1.3-1.0. ";
CM_ SG_ 1917 FirstFrameLength "TRANSPORT_CANDIDATE: normal-addressing ISO-TP. PSA-RE bits 1.3-2.0. 12-bit declared PDU length; not a reassembled value.";
CM_ SG_ 1917 SingleFrameLength "TRANSPORT_CANDIDATE: normal-addressing ISO-TP. PSA-RE bits 1.3-1.0. Declared data length; not a validity check.";
CM_ SG_ 1917 IsoTpFrameType "TRANSPORT_CANDIDATE: normal-addressing ISO-TP. PSA-RE bits 1.7-1.4. PCI high nibble; normal addressing candidate.";
CM_ BO_ 1956 "DATABASE_CANDIDATE: physical interpretation unverified; capture/layout evidence reported separately. INFO-DIV CAN, 125000 bit/s; CAN ID 0x7A4. PSA-RE title: InfoMessage01. Observed INFO identifier absent from the source bus. Raw bytes only; sender and physical meaning unknown. Source: none; capture-only raw layout. Source sender alternatives: ; physical TX/gateway forwarding not verified. Observed 586 frames in info_apka.csv,info_buzeni_obc.csv,info_charging.csv,info_standby.csv,info_start_jizda.csv,infocan.csv; DLCs [8]. ";
CM_ SG_ 1956 RawByte8 "RAW. PSA-RE bits 8.7-8.0. Unmapped/padding bits, no physical interpretation.";
CM_ SG_ 1956 RawByte7 "RAW. PSA-RE bits 7.7-7.0. Unmapped/padding bits, no physical interpretation.";
CM_ SG_ 1956 RawByte6 "RAW. PSA-RE bits 6.7-6.0. Unmapped/padding bits, no physical interpretation.";
CM_ SG_ 1956 RawByte5 "RAW. PSA-RE bits 5.7-5.0. Unmapped/padding bits, no physical interpretation.";
CM_ SG_ 1956 RawByte4 "RAW. PSA-RE bits 4.7-4.0. Unmapped/padding bits, no physical interpretation.";
CM_ SG_ 1956 RawByte3 "RAW. PSA-RE bits 3.7-3.0. Unmapped/padding bits, no physical interpretation.";
CM_ SG_ 1956 RawByte2 "RAW. PSA-RE bits 2.7-2.0. Unmapped/padding bits, no physical interpretation.";
CM_ SG_ 1956 RawByte1 "RAW. PSA-RE bits 1.7-1.0. Unmapped/padding bits, no physical interpretation.";
CM_ BO_ 2047 "DATABASE_CANDIDATE: physical interpretation unverified; capture/layout evidence reported separately. INFO-DIV CAN, 125000 bit/s; CAN ID 0x7FF. PSA-RE title: UDS_DIAGNOSTIC_REQUEST. Generic UDS diagnostic request/data frame on the CAN bus. Source: https://github.com/prototux/PSA-RE/blob/67f7581e7622410efdbb29c7eda3b86982b9b450/buses/AEE2010.full/LS.INFO-DIV/7FF.yml. Source sender alternatives: BSI,ICSV; physical TX/gateway forwarding not verified. WIRE ISO-TP ONLY: normal addressing candidate, maximum Classical CAN DLC 8; actual DLC may be shorter. Data includes padding. No reassembly, text, DID or application-layer decoding. Original application layouts are preserved in source JSON; do not decode them at wire offsets. ";
CM_ SG_ 2047 FlowPadding5 "TRANSPORT_CANDIDATE: normal-addressing ISO-TP. PSA-RE bits 8.7-8.0. ";
CM_ SG_ 2047 FirstData6 "TRANSPORT_CANDIDATE: normal-addressing ISO-TP. PSA-RE bits 8.7-8.0. ";
CM_ SG_ 2047 UnknownData7 "TRANSPORT_CANDIDATE: normal-addressing ISO-TP. PSA-RE bits 8.7-8.0. ";
CM_ SG_ 2047 ConsecutiveData7 "TRANSPORT_CANDIDATE: normal-addressing ISO-TP. PSA-RE bits 8.7-8.0. ";
CM_ SG_ 2047 SingleData7 "TRANSPORT_CANDIDATE: normal-addressing ISO-TP. PSA-RE bits 8.7-8.0. ";
CM_ SG_ 2047 FlowPadding4 "TRANSPORT_CANDIDATE: normal-addressing ISO-TP. PSA-RE bits 7.7-7.0. ";
CM_ SG_ 2047 FirstData5 "TRANSPORT_CANDIDATE: normal-addressing ISO-TP. PSA-RE bits 7.7-7.0. ";
CM_ SG_ 2047 UnknownData6 "TRANSPORT_CANDIDATE: normal-addressing ISO-TP. PSA-RE bits 7.7-7.0. ";
CM_ SG_ 2047 ConsecutiveData6 "TRANSPORT_CANDIDATE: normal-addressing ISO-TP. PSA-RE bits 7.7-7.0. ";
CM_ SG_ 2047 SingleData6 "TRANSPORT_CANDIDATE: normal-addressing ISO-TP. PSA-RE bits 7.7-7.0. ";
CM_ SG_ 2047 FlowPadding3 "TRANSPORT_CANDIDATE: normal-addressing ISO-TP. PSA-RE bits 6.7-6.0. ";
CM_ SG_ 2047 FirstData4 "TRANSPORT_CANDIDATE: normal-addressing ISO-TP. PSA-RE bits 6.7-6.0. ";
CM_ SG_ 2047 UnknownData5 "TRANSPORT_CANDIDATE: normal-addressing ISO-TP. PSA-RE bits 6.7-6.0. ";
CM_ SG_ 2047 ConsecutiveData5 "TRANSPORT_CANDIDATE: normal-addressing ISO-TP. PSA-RE bits 6.7-6.0. ";
CM_ SG_ 2047 SingleData5 "TRANSPORT_CANDIDATE: normal-addressing ISO-TP. PSA-RE bits 6.7-6.0. ";
CM_ SG_ 2047 FlowPadding2 "TRANSPORT_CANDIDATE: normal-addressing ISO-TP. PSA-RE bits 5.7-5.0. ";
CM_ SG_ 2047 FirstData3 "TRANSPORT_CANDIDATE: normal-addressing ISO-TP. PSA-RE bits 5.7-5.0. ";
CM_ SG_ 2047 UnknownData4 "TRANSPORT_CANDIDATE: normal-addressing ISO-TP. PSA-RE bits 5.7-5.0. ";
CM_ SG_ 2047 ConsecutiveData4 "TRANSPORT_CANDIDATE: normal-addressing ISO-TP. PSA-RE bits 5.7-5.0. ";
CM_ SG_ 2047 SingleData4 "TRANSPORT_CANDIDATE: normal-addressing ISO-TP. PSA-RE bits 5.7-5.0. ";
CM_ SG_ 2047 FlowPadding1 "TRANSPORT_CANDIDATE: normal-addressing ISO-TP. PSA-RE bits 4.7-4.0. ";
CM_ SG_ 2047 FirstData2 "TRANSPORT_CANDIDATE: normal-addressing ISO-TP. PSA-RE bits 4.7-4.0. ";
CM_ SG_ 2047 UnknownData3 "TRANSPORT_CANDIDATE: normal-addressing ISO-TP. PSA-RE bits 4.7-4.0. ";
CM_ SG_ 2047 ConsecutiveData3 "TRANSPORT_CANDIDATE: normal-addressing ISO-TP. PSA-RE bits 4.7-4.0. ";
CM_ SG_ 2047 SingleData3 "TRANSPORT_CANDIDATE: normal-addressing ISO-TP. PSA-RE bits 4.7-4.0. ";
CM_ SG_ 2047 FirstData1 "TRANSPORT_CANDIDATE: normal-addressing ISO-TP. PSA-RE bits 3.7-3.0. ";
CM_ SG_ 2047 UnknownData2 "TRANSPORT_CANDIDATE: normal-addressing ISO-TP. PSA-RE bits 3.7-3.0. ";
CM_ SG_ 2047 ConsecutiveData2 "TRANSPORT_CANDIDATE: normal-addressing ISO-TP. PSA-RE bits 3.7-3.0. ";
CM_ SG_ 2047 SingleData2 "TRANSPORT_CANDIDATE: normal-addressing ISO-TP. PSA-RE bits 3.7-3.0. ";
CM_ SG_ 2047 SeparationTimeRaw "TRANSPORT_CANDIDATE: normal-addressing ISO-TP. PSA-RE bits 3.7-3.0. Raw STmin code; 0xF1..0xF9 are not milliseconds.";
CM_ SG_ 2047 UnknownData1 "TRANSPORT_CANDIDATE: normal-addressing ISO-TP. PSA-RE bits 2.7-2.0. ";
CM_ SG_ 2047 ConsecutiveData1 "TRANSPORT_CANDIDATE: normal-addressing ISO-TP. PSA-RE bits 2.7-2.0. ";
CM_ SG_ 2047 SingleData1 "TRANSPORT_CANDIDATE: normal-addressing ISO-TP. PSA-RE bits 2.7-2.0. ";
CM_ SG_ 2047 BlockSize "TRANSPORT_CANDIDATE: normal-addressing ISO-TP. PSA-RE bits 2.7-2.0. ";
CM_ SG_ 2047 UnknownPciLow "TRANSPORT_CANDIDATE: normal-addressing ISO-TP. PSA-RE bits 1.3-1.0. ";
CM_ SG_ 2047 FlowStatus "TRANSPORT_CANDIDATE: normal-addressing ISO-TP. PSA-RE bits 1.3-1.0. ";
CM_ SG_ 2047 ConsecutiveSequence "TRANSPORT_CANDIDATE: normal-addressing ISO-TP. PSA-RE bits 1.3-1.0. ";
CM_ SG_ 2047 FirstFrameLength "TRANSPORT_CANDIDATE: normal-addressing ISO-TP. PSA-RE bits 1.3-2.0. 12-bit declared PDU length; not a reassembled value.";
CM_ SG_ 2047 SingleFrameLength "TRANSPORT_CANDIDATE: normal-addressing ISO-TP. PSA-RE bits 1.3-1.0. Declared data length; not a validity check.";
CM_ SG_ 2047 IsoTpFrameType "TRANSPORT_CANDIDATE: normal-addressing ISO-TP. PSA-RE bits 1.7-1.4. PCI high nibble; normal addressing candidate.";
CM_ BO_ 2415919104 "DATABASE_CANDIDATE: physical interpretation unverified; capture/layout evidence reported separately. INFO-DIV CAN, 125000 bit/s; CAN ID 0x10000000. PSA-RE title: ARTIV_AND_HYBRID_STATUS_2. Adaptive cruise control (target detection and gap) and hybrid system status: alert, detected target, display mode, gap setpoint. Source: https://github.com/prototux/PSA-RE/blob/67f7581e7622410efdbb29c7eda3b86982b9b450/buses/AEE2010.full/LS.INFO-DIV/10000000.yml. Source sender alternatives: BSI; physical TX/gateway forwarding not verified. ";
CM_ SG_ 2415919104 LpaHaloDisplay "DATABASE_CANDIDATE: physical interpretation unverified; capture/layout evidence reported separately. PSA-RE bits 8.0. HALO LPA display presence in the handset";
CM_ SG_ 2415919104 ZtepPowerRatio "DATABASE_CANDIDATE: physical interpretation unverified; capture/layout evidence reported separately. PSA-RE bits 8.7-8.1. Percentage of vehicle power relative to ZTEP available power Raw invalid=63; numeric DBC decoders may still scale it: check raw before use.";
CM_ SG_ 2415919104 DaaLateralControlState "DATABASE_CANDIDATE: physical interpretation unverified; capture/layout evidence reported separately. PSA-RE bits 7.0. Operational state of the DAA lateral control indicator";
CM_ SG_ 2415919104 LpaReadyWhenSelected "DATABASE_CANDIDATE: physical interpretation unverified; capture/layout evidence reported separately. PSA-RE bits 7.1. Indicates, once the function is selected, whether it will become active when ACC is active";
CM_ SG_ 2415919104 LpaStateStatus "DATABASE_CANDIDATE: physical interpretation unverified; capture/layout evidence reported separately. PSA-RE bits 7.3-7.2. Continuous status information for the driver: function not selected, selected (chosen but unable to operate), or active (in progress, suspended or faulty)";
CM_ SG_ 2415919104 PlugIndicatorLampRequest "DATABASE_CANDIDATE: physical interpretation unverified; capture/layout evidence reported separately. PSA-RE bits 7.5-7.4. Request to light the charging plug indicator lamp";
CM_ SG_ 2415919104 LkaStateStatus "DATABASE_CANDIDATE: physical interpretation unverified; capture/layout evidence reported separately. PSA-RE bits 7.7-7.6. Status information for the driver indicating the state of the lane keeping assist function";
CM_ SG_ 2415919104 LkaLeftLineStatus "DATABASE_CANDIDATE: physical interpretation unverified; capture/layout evidence reported separately. PSA-RE bits 6.1-6.0. Continuous status information for the driver about the lane keeping function on the left line";
CM_ SG_ 2415919104 LkaRightLineStatus "DATABASE_CANDIDATE: physical interpretation unverified; capture/layout evidence reported separately. PSA-RE bits 6.3-6.2. Continuous status information for the driver about the lane keeping function on the right line";
CM_ SG_ 2415919104 DaaLateralControlLevel "DATABASE_CANDIDATE: physical interpretation unverified; capture/layout evidence reported separately. PSA-RE bits 6.7-6.4. Driver alertness level information for lateral control";
CM_ SG_ 2415919104 HybridPowerTraction "DATABASE_CANDIDATE: physical interpretation unverified; capture/layout evidence reported separately. PSA-RE bits 4.0-5.0. Power delivered by the hybrid powertrain Raw invalid=511; numeric DBC decoders may still scale it: check raw before use.";
CM_ SG_ 2415919104 PowerBatteryHt "DATABASE_CANDIDATE: physical interpretation unverified; capture/layout evidence reported separately. PSA-RE bits 4.7-4.1. High-voltage battery power balance Raw invalid=127; numeric DBC decoders may still scale it: check raw before use.";
CM_ SG_ 2415919104 TivTarget "DATABASE_CANDIDATE: physical interpretation unverified; capture/layout evidence reported separately. PSA-RE bits 3.7-3.0. Target time interval to the vehicle ahead (TIV) Raw invalid=255; numeric DBC decoders may still scale it: check raw before use.";
CM_ SG_ 2415919104 TivSetpoint "DATABASE_CANDIDATE: physical interpretation unverified; capture/layout evidence reported separately. PSA-RE bits 2.7-2.0. Setpoint time interval to the vehicle ahead (TIV) Raw invalid=255; numeric DBC decoders may still scale it: check raw before use.";
CM_ SG_ 2415919104 RawBits7_7 "RAW. PSA-RE bits 1.0-1.0. Unmapped/padding bits, no physical interpretation.";
CM_ SG_ 2415919104 ArtivTargetDetected "DATABASE_CANDIDATE: physical interpretation unverified; capture/layout evidence reported separately. PSA-RE bits 1.1. ARTIV target detected";
CM_ SG_ 2415919104 ArtivAlertAdjustment "DATABASE_CANDIDATE: physical interpretation unverified; capture/layout evidence reported separately. PSA-RE bits 1.2. ARTIV alert adjustment";
CM_ SG_ 2415919104 ArtivAlert "DATABASE_CANDIDATE: physical interpretation unverified; capture/layout evidence reported separately. PSA-RE bits 1.3. ARTIV alert";
CM_ SG_ 2415919104 IhmArtivStatus "DATABASE_CANDIDATE: physical interpretation unverified; capture/layout evidence reported separately. PSA-RE bits 1.5-1.4. ARTIV display status";
CM_ SG_ 2415919104 ArtivSelectionStatus "DATABASE_CANDIDATE: physical interpretation unverified; capture/layout evidence reported separately. PSA-RE bits 1.7-1.6. ARTIV selection status";
VAL_ 1894 FlowStatus 0 "ContinueToSend" 1 "Wait" 2 "Overflow" ;
VAL_ 1894 IsoTpFrameType 0 "SingleFrame" 1 "FirstFrame" 2 "ConsecutiveFrame" 3 "FlowControl" ;
VAL_ 1899 FlowStatus 0 "ContinueToSend" 1 "Wait" 2 "Overflow" ;
VAL_ 1899 IsoTpFrameType 0 "SingleFrame" 1 "FirstFrame" 2 "ConsecutiveFrame" 3 "FlowControl" ;
VAL_ 1900 FlowStatus 0 "ContinueToSend" 1 "Wait" 2 "Overflow" ;
VAL_ 1900 IsoTpFrameType 0 "SingleFrame" 1 "FirstFrame" 2 "ConsecutiveFrame" 3 "FlowControl" ;
VAL_ 1901 FlowStatus 0 "ContinueToSend" 1 "Wait" 2 "Overflow" ;
VAL_ 1901 IsoTpFrameType 0 "SingleFrame" 1 "FirstFrame" 2 "ConsecutiveFrame" 3 "FlowControl" ;
VAL_ 1902 FlowStatus 0 "ContinueToSend" 1 "Wait" 2 "Overflow" ;
VAL_ 1902 IsoTpFrameType 0 "SingleFrame" 1 "FirstFrame" 2 "ConsecutiveFrame" 3 "FlowControl" ;
VAL_ 1903 FlowStatus 0 "ContinueToSend" 1 "Wait" 2 "Overflow" ;
VAL_ 1903 IsoTpFrameType 0 "SingleFrame" 1 "FirstFrame" 2 "ConsecutiveFrame" 3 "FlowControl" ;
VAL_ 1904 FlowStatus 0 "ContinueToSend" 1 "Wait" 2 "Overflow" ;
VAL_ 1904 IsoTpFrameType 0 "SingleFrame" 1 "FirstFrame" 2 "ConsecutiveFrame" 3 "FlowControl" ;
VAL_ 1905 FlowStatus 0 "ContinueToSend" 1 "Wait" 2 "Overflow" ;
VAL_ 1905 IsoTpFrameType 0 "SingleFrame" 1 "FirstFrame" 2 "ConsecutiveFrame" 3 "FlowControl" ;
VAL_ 1906 FlowStatus 0 "ContinueToSend" 1 "Wait" 2 "Overflow" ;
VAL_ 1906 IsoTpFrameType 0 "SingleFrame" 1 "FirstFrame" 2 "ConsecutiveFrame" 3 "FlowControl" ;
VAL_ 1907 FlowStatus 0 "ContinueToSend" 1 "Wait" 2 "Overflow" ;
VAL_ 1907 IsoTpFrameType 0 "SingleFrame" 1 "FirstFrame" 2 "ConsecutiveFrame" 3 "FlowControl" ;
VAL_ 1908 FlowStatus 0 "ContinueToSend" 1 "Wait" 2 "Overflow" ;
VAL_ 1908 IsoTpFrameType 0 "SingleFrame" 1 "FirstFrame" 2 "ConsecutiveFrame" 3 "FlowControl" ;
VAL_ 1912 FlowStatus 0 "ContinueToSend" 1 "Wait" 2 "Overflow" ;
VAL_ 1912 IsoTpFrameType 0 "SingleFrame" 1 "FirstFrame" 2 "ConsecutiveFrame" 3 "FlowControl" ;
VAL_ 1915 FlowStatus 0 "ContinueToSend" 1 "Wait" 2 "Overflow" ;
VAL_ 1915 IsoTpFrameType 0 "SingleFrame" 1 "FirstFrame" 2 "ConsecutiveFrame" 3 "FlowControl" ;
VAL_ 1916 FlowStatus 0 "ContinueToSend" 1 "Wait" 2 "Overflow" ;
VAL_ 1916 IsoTpFrameType 0 "SingleFrame" 1 "FirstFrame" 2 "ConsecutiveFrame" 3 "FlowControl" ;
VAL_ 1917 FlowStatus 0 "ContinueToSend" 1 "Wait" 2 "Overflow" ;
VAL_ 1917 IsoTpFrameType 0 "SingleFrame" 1 "FirstFrame" 2 "ConsecutiveFrame" 3 "FlowControl" ;
VAL_ 2047 FlowStatus 0 "ContinueToSend" 1 "Wait" 2 "Overflow" ;
VAL_ 2047 IsoTpFrameType 0 "SingleFrame" 1 "FirstFrame" 2 "ConsecutiveFrame" 3 "FlowControl" ;
VAL_ 2415919104 LpaHaloDisplay 0 "With" 1 "Without" ;
VAL_ 2415919104 ZtepPowerRatio 63 "Not_available" ;
VAL_ 2415919104 DaaLateralControlState 0 "Not operational" 1 "Operational" ;
VAL_ 2415919104 LpaReadyWhenSelected 0 "Not ready" 1 "Ready" ;
VAL_ 2415919104 LpaStateStatus 0 "Off" 1 "On fixed selected" 2 "On fixed active" 3 "On, fixed fault" ;
VAL_ 2415919104 PlugIndicatorLampRequest 0 "No request" 1 "Fixed request" 2 "Flashing request" ;
VAL_ 2415919104 LkaStateStatus 0 "Off" 1 "Lit steady, not ready" 2 "On, blinking" 3 "On steady, ready" ;
VAL_ 2415919104 LkaLeftLineStatus 0 "Not selected" 1 "Not allowed" 2 "Allowed" 3 "Correction in progress" ;
VAL_ 2415919104 LkaRightLineStatus 0 "Not selected" 1 "Not allowed" 2 "Allowed" 3 "Correction in progress" ;
VAL_ 2415919104 DaaLateralControlLevel 0 "Unavailable" 1 "Level 1" 2 "Level 2" 3 "Level 3" 4 "Level 4" 5 "Level 5" 6 "Level 6" 7 "Level 7" 8 "Level 8" ;
VAL_ 2415919104 HybridPowerTraction 511 "Not_available" ;
VAL_ 2415919104 PowerBatteryHt 127 "Not_available" ;
VAL_ 2415919104 TivTarget 255 "Not_available" ;
VAL_ 2415919104 TivSetpoint 255 "Not_available" ;
VAL_ 2415919104 ArtivTargetDetected 0 "Target not detected" 1 "Target detected" ;
VAL_ 2415919104 ArtivAlertAdjustment 0 "No adjustment" 1 "Adjustment" ;
VAL_ 2415919104 ArtivAlert 0 "No alert" 1 "Alert" ;
VAL_ 2415919104 IhmArtivStatus 0 "Inappropriate speed" 1 "Active" 2 "Low visibility" 3 "Learning" ;
VAL_ 2415919104 ArtivSelectionStatus 0 "Not selected" 1 "Selected" 2 "Selected but unavailable" 3 "Invalid" ;
SG_MUL_VAL_ 1894 SingleFrameLength IsoTpFrameType 0-0;
SG_MUL_VAL_ 1894 FirstFrameLength IsoTpFrameType 1-1;
SG_MUL_VAL_ 1894 ConsecutiveSequence IsoTpFrameType 2-2;
SG_MUL_VAL_ 1894 FlowStatus IsoTpFrameType 3-3;
SG_MUL_VAL_ 1894 UnknownPciLow IsoTpFrameType 4-15;
SG_MUL_VAL_ 1894 BlockSize IsoTpFrameType 3-3;
SG_MUL_VAL_ 1894 SingleData1 IsoTpFrameType 0-0;
SG_MUL_VAL_ 1894 ConsecutiveData1 IsoTpFrameType 2-2;
SG_MUL_VAL_ 1894 UnknownData1 IsoTpFrameType 4-15;
SG_MUL_VAL_ 1894 SeparationTimeRaw IsoTpFrameType 3-3;
SG_MUL_VAL_ 1894 SingleData2 IsoTpFrameType 0-0;
SG_MUL_VAL_ 1894 ConsecutiveData2 IsoTpFrameType 2-2;
SG_MUL_VAL_ 1894 UnknownData2 IsoTpFrameType 4-15;
SG_MUL_VAL_ 1894 FirstData1 IsoTpFrameType 1-1;
SG_MUL_VAL_ 1894 SingleData3 IsoTpFrameType 0-0;
SG_MUL_VAL_ 1894 ConsecutiveData3 IsoTpFrameType 2-2;
SG_MUL_VAL_ 1894 UnknownData3 IsoTpFrameType 4-15;
SG_MUL_VAL_ 1894 FirstData2 IsoTpFrameType 1-1;
SG_MUL_VAL_ 1894 FlowPadding1 IsoTpFrameType 3-3;
SG_MUL_VAL_ 1894 SingleData4 IsoTpFrameType 0-0;
SG_MUL_VAL_ 1894 ConsecutiveData4 IsoTpFrameType 2-2;
SG_MUL_VAL_ 1894 UnknownData4 IsoTpFrameType 4-15;
SG_MUL_VAL_ 1894 FirstData3 IsoTpFrameType 1-1;
SG_MUL_VAL_ 1894 FlowPadding2 IsoTpFrameType 3-3;
SG_MUL_VAL_ 1894 SingleData5 IsoTpFrameType 0-0;
SG_MUL_VAL_ 1894 ConsecutiveData5 IsoTpFrameType 2-2;
SG_MUL_VAL_ 1894 UnknownData5 IsoTpFrameType 4-15;
SG_MUL_VAL_ 1894 FirstData4 IsoTpFrameType 1-1;
SG_MUL_VAL_ 1894 FlowPadding3 IsoTpFrameType 3-3;
SG_MUL_VAL_ 1894 SingleData6 IsoTpFrameType 0-0;
SG_MUL_VAL_ 1894 ConsecutiveData6 IsoTpFrameType 2-2;
SG_MUL_VAL_ 1894 UnknownData6 IsoTpFrameType 4-15;
SG_MUL_VAL_ 1894 FirstData5 IsoTpFrameType 1-1;
SG_MUL_VAL_ 1894 FlowPadding4 IsoTpFrameType 3-3;
SG_MUL_VAL_ 1894 SingleData7 IsoTpFrameType 0-0;
SG_MUL_VAL_ 1894 ConsecutiveData7 IsoTpFrameType 2-2;
SG_MUL_VAL_ 1894 UnknownData7 IsoTpFrameType 4-15;
SG_MUL_VAL_ 1894 FirstData6 IsoTpFrameType 1-1;
SG_MUL_VAL_ 1894 FlowPadding5 IsoTpFrameType 3-3;
SG_MUL_VAL_ 1899 SingleFrameLength IsoTpFrameType 0-0;
SG_MUL_VAL_ 1899 FirstFrameLength IsoTpFrameType 1-1;
SG_MUL_VAL_ 1899 ConsecutiveSequence IsoTpFrameType 2-2;
SG_MUL_VAL_ 1899 FlowStatus IsoTpFrameType 3-3;
SG_MUL_VAL_ 1899 UnknownPciLow IsoTpFrameType 4-15;
SG_MUL_VAL_ 1899 BlockSize IsoTpFrameType 3-3;
SG_MUL_VAL_ 1899 SingleData1 IsoTpFrameType 0-0;
SG_MUL_VAL_ 1899 ConsecutiveData1 IsoTpFrameType 2-2;
SG_MUL_VAL_ 1899 UnknownData1 IsoTpFrameType 4-15;
SG_MUL_VAL_ 1899 SeparationTimeRaw IsoTpFrameType 3-3;
SG_MUL_VAL_ 1899 SingleData2 IsoTpFrameType 0-0;
SG_MUL_VAL_ 1899 ConsecutiveData2 IsoTpFrameType 2-2;
SG_MUL_VAL_ 1899 UnknownData2 IsoTpFrameType 4-15;
SG_MUL_VAL_ 1899 FirstData1 IsoTpFrameType 1-1;
SG_MUL_VAL_ 1899 SingleData3 IsoTpFrameType 0-0;
SG_MUL_VAL_ 1899 ConsecutiveData3 IsoTpFrameType 2-2;
SG_MUL_VAL_ 1899 UnknownData3 IsoTpFrameType 4-15;
SG_MUL_VAL_ 1899 FirstData2 IsoTpFrameType 1-1;
SG_MUL_VAL_ 1899 FlowPadding1 IsoTpFrameType 3-3;
SG_MUL_VAL_ 1899 SingleData4 IsoTpFrameType 0-0;
SG_MUL_VAL_ 1899 ConsecutiveData4 IsoTpFrameType 2-2;
SG_MUL_VAL_ 1899 UnknownData4 IsoTpFrameType 4-15;
SG_MUL_VAL_ 1899 FirstData3 IsoTpFrameType 1-1;
SG_MUL_VAL_ 1899 FlowPadding2 IsoTpFrameType 3-3;
SG_MUL_VAL_ 1899 SingleData5 IsoTpFrameType 0-0;
SG_MUL_VAL_ 1899 ConsecutiveData5 IsoTpFrameType 2-2;
SG_MUL_VAL_ 1899 UnknownData5 IsoTpFrameType 4-15;
SG_MUL_VAL_ 1899 FirstData4 IsoTpFrameType 1-1;
SG_MUL_VAL_ 1899 FlowPadding3 IsoTpFrameType 3-3;
SG_MUL_VAL_ 1899 SingleData6 IsoTpFrameType 0-0;
SG_MUL_VAL_ 1899 ConsecutiveData6 IsoTpFrameType 2-2;
SG_MUL_VAL_ 1899 UnknownData6 IsoTpFrameType 4-15;
SG_MUL_VAL_ 1899 FirstData5 IsoTpFrameType 1-1;
SG_MUL_VAL_ 1899 FlowPadding4 IsoTpFrameType 3-3;
SG_MUL_VAL_ 1899 SingleData7 IsoTpFrameType 0-0;
SG_MUL_VAL_ 1899 ConsecutiveData7 IsoTpFrameType 2-2;
SG_MUL_VAL_ 1899 UnknownData7 IsoTpFrameType 4-15;
SG_MUL_VAL_ 1899 FirstData6 IsoTpFrameType 1-1;
SG_MUL_VAL_ 1899 FlowPadding5 IsoTpFrameType 3-3;
SG_MUL_VAL_ 1900 SingleFrameLength IsoTpFrameType 0-0;
SG_MUL_VAL_ 1900 FirstFrameLength IsoTpFrameType 1-1;
SG_MUL_VAL_ 1900 ConsecutiveSequence IsoTpFrameType 2-2;
SG_MUL_VAL_ 1900 FlowStatus IsoTpFrameType 3-3;
SG_MUL_VAL_ 1900 UnknownPciLow IsoTpFrameType 4-15;
SG_MUL_VAL_ 1900 BlockSize IsoTpFrameType 3-3;
SG_MUL_VAL_ 1900 SingleData1 IsoTpFrameType 0-0;
SG_MUL_VAL_ 1900 ConsecutiveData1 IsoTpFrameType 2-2;
SG_MUL_VAL_ 1900 UnknownData1 IsoTpFrameType 4-15;
SG_MUL_VAL_ 1900 SeparationTimeRaw IsoTpFrameType 3-3;
SG_MUL_VAL_ 1900 SingleData2 IsoTpFrameType 0-0;
SG_MUL_VAL_ 1900 ConsecutiveData2 IsoTpFrameType 2-2;
SG_MUL_VAL_ 1900 UnknownData2 IsoTpFrameType 4-15;
SG_MUL_VAL_ 1900 FirstData1 IsoTpFrameType 1-1;
SG_MUL_VAL_ 1900 SingleData3 IsoTpFrameType 0-0;
SG_MUL_VAL_ 1900 ConsecutiveData3 IsoTpFrameType 2-2;
SG_MUL_VAL_ 1900 UnknownData3 IsoTpFrameType 4-15;
SG_MUL_VAL_ 1900 FirstData2 IsoTpFrameType 1-1;
SG_MUL_VAL_ 1900 FlowPadding1 IsoTpFrameType 3-3;
SG_MUL_VAL_ 1900 SingleData4 IsoTpFrameType 0-0;
SG_MUL_VAL_ 1900 ConsecutiveData4 IsoTpFrameType 2-2;
SG_MUL_VAL_ 1900 UnknownData4 IsoTpFrameType 4-15;
SG_MUL_VAL_ 1900 FirstData3 IsoTpFrameType 1-1;
SG_MUL_VAL_ 1900 FlowPadding2 IsoTpFrameType 3-3;
SG_MUL_VAL_ 1900 SingleData5 IsoTpFrameType 0-0;
SG_MUL_VAL_ 1900 ConsecutiveData5 IsoTpFrameType 2-2;
SG_MUL_VAL_ 1900 UnknownData5 IsoTpFrameType 4-15;
SG_MUL_VAL_ 1900 FirstData4 IsoTpFrameType 1-1;
SG_MUL_VAL_ 1900 FlowPadding3 IsoTpFrameType 3-3;
SG_MUL_VAL_ 1900 SingleData6 IsoTpFrameType 0-0;
SG_MUL_VAL_ 1900 ConsecutiveData6 IsoTpFrameType 2-2;
SG_MUL_VAL_ 1900 UnknownData6 IsoTpFrameType 4-15;
SG_MUL_VAL_ 1900 FirstData5 IsoTpFrameType 1-1;
SG_MUL_VAL_ 1900 FlowPadding4 IsoTpFrameType 3-3;
SG_MUL_VAL_ 1900 SingleData7 IsoTpFrameType 0-0;
SG_MUL_VAL_ 1900 ConsecutiveData7 IsoTpFrameType 2-2;
SG_MUL_VAL_ 1900 UnknownData7 IsoTpFrameType 4-15;
SG_MUL_VAL_ 1900 FirstData6 IsoTpFrameType 1-1;
SG_MUL_VAL_ 1900 FlowPadding5 IsoTpFrameType 3-3;
SG_MUL_VAL_ 1901 SingleFrameLength IsoTpFrameType 0-0;
SG_MUL_VAL_ 1901 FirstFrameLength IsoTpFrameType 1-1;
SG_MUL_VAL_ 1901 ConsecutiveSequence IsoTpFrameType 2-2;
SG_MUL_VAL_ 1901 FlowStatus IsoTpFrameType 3-3;
SG_MUL_VAL_ 1901 UnknownPciLow IsoTpFrameType 4-15;
SG_MUL_VAL_ 1901 BlockSize IsoTpFrameType 3-3;
SG_MUL_VAL_ 1901 SingleData1 IsoTpFrameType 0-0;
SG_MUL_VAL_ 1901 ConsecutiveData1 IsoTpFrameType 2-2;
SG_MUL_VAL_ 1901 UnknownData1 IsoTpFrameType 4-15;
SG_MUL_VAL_ 1901 SeparationTimeRaw IsoTpFrameType 3-3;
SG_MUL_VAL_ 1901 SingleData2 IsoTpFrameType 0-0;
SG_MUL_VAL_ 1901 ConsecutiveData2 IsoTpFrameType 2-2;
SG_MUL_VAL_ 1901 UnknownData2 IsoTpFrameType 4-15;
SG_MUL_VAL_ 1901 FirstData1 IsoTpFrameType 1-1;
SG_MUL_VAL_ 1901 SingleData3 IsoTpFrameType 0-0;
SG_MUL_VAL_ 1901 ConsecutiveData3 IsoTpFrameType 2-2;
SG_MUL_VAL_ 1901 UnknownData3 IsoTpFrameType 4-15;
SG_MUL_VAL_ 1901 FirstData2 IsoTpFrameType 1-1;
SG_MUL_VAL_ 1901 FlowPadding1 IsoTpFrameType 3-3;
SG_MUL_VAL_ 1901 SingleData4 IsoTpFrameType 0-0;
SG_MUL_VAL_ 1901 ConsecutiveData4 IsoTpFrameType 2-2;
SG_MUL_VAL_ 1901 UnknownData4 IsoTpFrameType 4-15;
SG_MUL_VAL_ 1901 FirstData3 IsoTpFrameType 1-1;
SG_MUL_VAL_ 1901 FlowPadding2 IsoTpFrameType 3-3;
SG_MUL_VAL_ 1901 SingleData5 IsoTpFrameType 0-0;
SG_MUL_VAL_ 1901 ConsecutiveData5 IsoTpFrameType 2-2;
SG_MUL_VAL_ 1901 UnknownData5 IsoTpFrameType 4-15;
SG_MUL_VAL_ 1901 FirstData4 IsoTpFrameType 1-1;
SG_MUL_VAL_ 1901 FlowPadding3 IsoTpFrameType 3-3;
SG_MUL_VAL_ 1901 SingleData6 IsoTpFrameType 0-0;
SG_MUL_VAL_ 1901 ConsecutiveData6 IsoTpFrameType 2-2;
SG_MUL_VAL_ 1901 UnknownData6 IsoTpFrameType 4-15;
SG_MUL_VAL_ 1901 FirstData5 IsoTpFrameType 1-1;
SG_MUL_VAL_ 1901 FlowPadding4 IsoTpFrameType 3-3;
SG_MUL_VAL_ 1901 SingleData7 IsoTpFrameType 0-0;
SG_MUL_VAL_ 1901 ConsecutiveData7 IsoTpFrameType 2-2;
SG_MUL_VAL_ 1901 UnknownData7 IsoTpFrameType 4-15;
SG_MUL_VAL_ 1901 FirstData6 IsoTpFrameType 1-1;
SG_MUL_VAL_ 1901 FlowPadding5 IsoTpFrameType 3-3;
SG_MUL_VAL_ 1902 SingleFrameLength IsoTpFrameType 0-0;
SG_MUL_VAL_ 1902 FirstFrameLength IsoTpFrameType 1-1;
SG_MUL_VAL_ 1902 ConsecutiveSequence IsoTpFrameType 2-2;
SG_MUL_VAL_ 1902 FlowStatus IsoTpFrameType 3-3;
SG_MUL_VAL_ 1902 UnknownPciLow IsoTpFrameType 4-15;
SG_MUL_VAL_ 1902 BlockSize IsoTpFrameType 3-3;
SG_MUL_VAL_ 1902 SingleData1 IsoTpFrameType 0-0;
SG_MUL_VAL_ 1902 ConsecutiveData1 IsoTpFrameType 2-2;
SG_MUL_VAL_ 1902 UnknownData1 IsoTpFrameType 4-15;
SG_MUL_VAL_ 1902 SeparationTimeRaw IsoTpFrameType 3-3;
SG_MUL_VAL_ 1902 SingleData2 IsoTpFrameType 0-0;
SG_MUL_VAL_ 1902 ConsecutiveData2 IsoTpFrameType 2-2;
SG_MUL_VAL_ 1902 UnknownData2 IsoTpFrameType 4-15;
SG_MUL_VAL_ 1902 FirstData1 IsoTpFrameType 1-1;
SG_MUL_VAL_ 1902 SingleData3 IsoTpFrameType 0-0;
SG_MUL_VAL_ 1902 ConsecutiveData3 IsoTpFrameType 2-2;
SG_MUL_VAL_ 1902 UnknownData3 IsoTpFrameType 4-15;
SG_MUL_VAL_ 1902 FirstData2 IsoTpFrameType 1-1;
SG_MUL_VAL_ 1902 FlowPadding1 IsoTpFrameType 3-3;
SG_MUL_VAL_ 1902 SingleData4 IsoTpFrameType 0-0;
SG_MUL_VAL_ 1902 ConsecutiveData4 IsoTpFrameType 2-2;
SG_MUL_VAL_ 1902 UnknownData4 IsoTpFrameType 4-15;
SG_MUL_VAL_ 1902 FirstData3 IsoTpFrameType 1-1;
SG_MUL_VAL_ 1902 FlowPadding2 IsoTpFrameType 3-3;
SG_MUL_VAL_ 1902 SingleData5 IsoTpFrameType 0-0;
SG_MUL_VAL_ 1902 ConsecutiveData5 IsoTpFrameType 2-2;
SG_MUL_VAL_ 1902 UnknownData5 IsoTpFrameType 4-15;
SG_MUL_VAL_ 1902 FirstData4 IsoTpFrameType 1-1;
SG_MUL_VAL_ 1902 FlowPadding3 IsoTpFrameType 3-3;
SG_MUL_VAL_ 1902 SingleData6 IsoTpFrameType 0-0;
SG_MUL_VAL_ 1902 ConsecutiveData6 IsoTpFrameType 2-2;
SG_MUL_VAL_ 1902 UnknownData6 IsoTpFrameType 4-15;
SG_MUL_VAL_ 1902 FirstData5 IsoTpFrameType 1-1;
SG_MUL_VAL_ 1902 FlowPadding4 IsoTpFrameType 3-3;
SG_MUL_VAL_ 1902 SingleData7 IsoTpFrameType 0-0;
SG_MUL_VAL_ 1902 ConsecutiveData7 IsoTpFrameType 2-2;
SG_MUL_VAL_ 1902 UnknownData7 IsoTpFrameType 4-15;
SG_MUL_VAL_ 1902 FirstData6 IsoTpFrameType 1-1;
SG_MUL_VAL_ 1902 FlowPadding5 IsoTpFrameType 3-3;
SG_MUL_VAL_ 1903 SingleFrameLength IsoTpFrameType 0-0;
SG_MUL_VAL_ 1903 FirstFrameLength IsoTpFrameType 1-1;
SG_MUL_VAL_ 1903 ConsecutiveSequence IsoTpFrameType 2-2;
SG_MUL_VAL_ 1903 FlowStatus IsoTpFrameType 3-3;
SG_MUL_VAL_ 1903 UnknownPciLow IsoTpFrameType 4-15;
SG_MUL_VAL_ 1903 BlockSize IsoTpFrameType 3-3;
SG_MUL_VAL_ 1903 SingleData1 IsoTpFrameType 0-0;
SG_MUL_VAL_ 1903 ConsecutiveData1 IsoTpFrameType 2-2;
SG_MUL_VAL_ 1903 UnknownData1 IsoTpFrameType 4-15;
SG_MUL_VAL_ 1903 SeparationTimeRaw IsoTpFrameType 3-3;
SG_MUL_VAL_ 1903 SingleData2 IsoTpFrameType 0-0;
SG_MUL_VAL_ 1903 ConsecutiveData2 IsoTpFrameType 2-2;
SG_MUL_VAL_ 1903 UnknownData2 IsoTpFrameType 4-15;
SG_MUL_VAL_ 1903 FirstData1 IsoTpFrameType 1-1;
SG_MUL_VAL_ 1903 SingleData3 IsoTpFrameType 0-0;
SG_MUL_VAL_ 1903 ConsecutiveData3 IsoTpFrameType 2-2;
SG_MUL_VAL_ 1903 UnknownData3 IsoTpFrameType 4-15;
SG_MUL_VAL_ 1903 FirstData2 IsoTpFrameType 1-1;
SG_MUL_VAL_ 1903 FlowPadding1 IsoTpFrameType 3-3;
SG_MUL_VAL_ 1903 SingleData4 IsoTpFrameType 0-0;
SG_MUL_VAL_ 1903 ConsecutiveData4 IsoTpFrameType 2-2;
SG_MUL_VAL_ 1903 UnknownData4 IsoTpFrameType 4-15;
SG_MUL_VAL_ 1903 FirstData3 IsoTpFrameType 1-1;
SG_MUL_VAL_ 1903 FlowPadding2 IsoTpFrameType 3-3;
SG_MUL_VAL_ 1903 SingleData5 IsoTpFrameType 0-0;
SG_MUL_VAL_ 1903 ConsecutiveData5 IsoTpFrameType 2-2;
SG_MUL_VAL_ 1903 UnknownData5 IsoTpFrameType 4-15;
SG_MUL_VAL_ 1903 FirstData4 IsoTpFrameType 1-1;
SG_MUL_VAL_ 1903 FlowPadding3 IsoTpFrameType 3-3;
SG_MUL_VAL_ 1903 SingleData6 IsoTpFrameType 0-0;
SG_MUL_VAL_ 1903 ConsecutiveData6 IsoTpFrameType 2-2;
SG_MUL_VAL_ 1903 UnknownData6 IsoTpFrameType 4-15;
SG_MUL_VAL_ 1903 FirstData5 IsoTpFrameType 1-1;
SG_MUL_VAL_ 1903 FlowPadding4 IsoTpFrameType 3-3;
SG_MUL_VAL_ 1903 SingleData7 IsoTpFrameType 0-0;
SG_MUL_VAL_ 1903 ConsecutiveData7 IsoTpFrameType 2-2;
SG_MUL_VAL_ 1903 UnknownData7 IsoTpFrameType 4-15;
SG_MUL_VAL_ 1903 FirstData6 IsoTpFrameType 1-1;
SG_MUL_VAL_ 1903 FlowPadding5 IsoTpFrameType 3-3;
SG_MUL_VAL_ 1904 SingleFrameLength IsoTpFrameType 0-0;
SG_MUL_VAL_ 1904 FirstFrameLength IsoTpFrameType 1-1;
SG_MUL_VAL_ 1904 ConsecutiveSequence IsoTpFrameType 2-2;
SG_MUL_VAL_ 1904 FlowStatus IsoTpFrameType 3-3;
SG_MUL_VAL_ 1904 UnknownPciLow IsoTpFrameType 4-15;
SG_MUL_VAL_ 1904 BlockSize IsoTpFrameType 3-3;
SG_MUL_VAL_ 1904 SingleData1 IsoTpFrameType 0-0;
SG_MUL_VAL_ 1904 ConsecutiveData1 IsoTpFrameType 2-2;
SG_MUL_VAL_ 1904 UnknownData1 IsoTpFrameType 4-15;
SG_MUL_VAL_ 1904 SeparationTimeRaw IsoTpFrameType 3-3;
SG_MUL_VAL_ 1904 SingleData2 IsoTpFrameType 0-0;
SG_MUL_VAL_ 1904 ConsecutiveData2 IsoTpFrameType 2-2;
SG_MUL_VAL_ 1904 UnknownData2 IsoTpFrameType 4-15;
SG_MUL_VAL_ 1904 FirstData1 IsoTpFrameType 1-1;
SG_MUL_VAL_ 1904 SingleData3 IsoTpFrameType 0-0;
SG_MUL_VAL_ 1904 ConsecutiveData3 IsoTpFrameType 2-2;
SG_MUL_VAL_ 1904 UnknownData3 IsoTpFrameType 4-15;
SG_MUL_VAL_ 1904 FirstData2 IsoTpFrameType 1-1;
SG_MUL_VAL_ 1904 FlowPadding1 IsoTpFrameType 3-3;
SG_MUL_VAL_ 1904 SingleData4 IsoTpFrameType 0-0;
SG_MUL_VAL_ 1904 ConsecutiveData4 IsoTpFrameType 2-2;
SG_MUL_VAL_ 1904 UnknownData4 IsoTpFrameType 4-15;
SG_MUL_VAL_ 1904 FirstData3 IsoTpFrameType 1-1;
SG_MUL_VAL_ 1904 FlowPadding2 IsoTpFrameType 3-3;
SG_MUL_VAL_ 1904 SingleData5 IsoTpFrameType 0-0;
SG_MUL_VAL_ 1904 ConsecutiveData5 IsoTpFrameType 2-2;
SG_MUL_VAL_ 1904 UnknownData5 IsoTpFrameType 4-15;
SG_MUL_VAL_ 1904 FirstData4 IsoTpFrameType 1-1;
SG_MUL_VAL_ 1904 FlowPadding3 IsoTpFrameType 3-3;
SG_MUL_VAL_ 1904 SingleData6 IsoTpFrameType 0-0;
SG_MUL_VAL_ 1904 ConsecutiveData6 IsoTpFrameType 2-2;
SG_MUL_VAL_ 1904 UnknownData6 IsoTpFrameType 4-15;
SG_MUL_VAL_ 1904 FirstData5 IsoTpFrameType 1-1;
SG_MUL_VAL_ 1904 FlowPadding4 IsoTpFrameType 3-3;
SG_MUL_VAL_ 1904 SingleData7 IsoTpFrameType 0-0;
SG_MUL_VAL_ 1904 ConsecutiveData7 IsoTpFrameType 2-2;
SG_MUL_VAL_ 1904 UnknownData7 IsoTpFrameType 4-15;
SG_MUL_VAL_ 1904 FirstData6 IsoTpFrameType 1-1;
SG_MUL_VAL_ 1904 FlowPadding5 IsoTpFrameType 3-3;
SG_MUL_VAL_ 1905 SingleFrameLength IsoTpFrameType 0-0;
SG_MUL_VAL_ 1905 FirstFrameLength IsoTpFrameType 1-1;
SG_MUL_VAL_ 1905 ConsecutiveSequence IsoTpFrameType 2-2;
SG_MUL_VAL_ 1905 FlowStatus IsoTpFrameType 3-3;
SG_MUL_VAL_ 1905 UnknownPciLow IsoTpFrameType 4-15;
SG_MUL_VAL_ 1905 BlockSize IsoTpFrameType 3-3;
SG_MUL_VAL_ 1905 SingleData1 IsoTpFrameType 0-0;
SG_MUL_VAL_ 1905 ConsecutiveData1 IsoTpFrameType 2-2;
SG_MUL_VAL_ 1905 UnknownData1 IsoTpFrameType 4-15;
SG_MUL_VAL_ 1905 SeparationTimeRaw IsoTpFrameType 3-3;
SG_MUL_VAL_ 1905 SingleData2 IsoTpFrameType 0-0;
SG_MUL_VAL_ 1905 ConsecutiveData2 IsoTpFrameType 2-2;
SG_MUL_VAL_ 1905 UnknownData2 IsoTpFrameType 4-15;
SG_MUL_VAL_ 1905 FirstData1 IsoTpFrameType 1-1;
SG_MUL_VAL_ 1905 SingleData3 IsoTpFrameType 0-0;
SG_MUL_VAL_ 1905 ConsecutiveData3 IsoTpFrameType 2-2;
SG_MUL_VAL_ 1905 UnknownData3 IsoTpFrameType 4-15;
SG_MUL_VAL_ 1905 FirstData2 IsoTpFrameType 1-1;
SG_MUL_VAL_ 1905 FlowPadding1 IsoTpFrameType 3-3;
SG_MUL_VAL_ 1905 SingleData4 IsoTpFrameType 0-0;
SG_MUL_VAL_ 1905 ConsecutiveData4 IsoTpFrameType 2-2;
SG_MUL_VAL_ 1905 UnknownData4 IsoTpFrameType 4-15;
SG_MUL_VAL_ 1905 FirstData3 IsoTpFrameType 1-1;
SG_MUL_VAL_ 1905 FlowPadding2 IsoTpFrameType 3-3;
SG_MUL_VAL_ 1905 SingleData5 IsoTpFrameType 0-0;
SG_MUL_VAL_ 1905 ConsecutiveData5 IsoTpFrameType 2-2;
SG_MUL_VAL_ 1905 UnknownData5 IsoTpFrameType 4-15;
SG_MUL_VAL_ 1905 FirstData4 IsoTpFrameType 1-1;
SG_MUL_VAL_ 1905 FlowPadding3 IsoTpFrameType 3-3;
SG_MUL_VAL_ 1905 SingleData6 IsoTpFrameType 0-0;
SG_MUL_VAL_ 1905 ConsecutiveData6 IsoTpFrameType 2-2;
SG_MUL_VAL_ 1905 UnknownData6 IsoTpFrameType 4-15;
SG_MUL_VAL_ 1905 FirstData5 IsoTpFrameType 1-1;
SG_MUL_VAL_ 1905 FlowPadding4 IsoTpFrameType 3-3;
SG_MUL_VAL_ 1905 SingleData7 IsoTpFrameType 0-0;
SG_MUL_VAL_ 1905 ConsecutiveData7 IsoTpFrameType 2-2;
SG_MUL_VAL_ 1905 UnknownData7 IsoTpFrameType 4-15;
SG_MUL_VAL_ 1905 FirstData6 IsoTpFrameType 1-1;
SG_MUL_VAL_ 1905 FlowPadding5 IsoTpFrameType 3-3;
SG_MUL_VAL_ 1906 SingleFrameLength IsoTpFrameType 0-0;
SG_MUL_VAL_ 1906 FirstFrameLength IsoTpFrameType 1-1;
SG_MUL_VAL_ 1906 ConsecutiveSequence IsoTpFrameType 2-2;
SG_MUL_VAL_ 1906 FlowStatus IsoTpFrameType 3-3;
SG_MUL_VAL_ 1906 UnknownPciLow IsoTpFrameType 4-15;
SG_MUL_VAL_ 1906 BlockSize IsoTpFrameType 3-3;
SG_MUL_VAL_ 1906 SingleData1 IsoTpFrameType 0-0;
SG_MUL_VAL_ 1906 ConsecutiveData1 IsoTpFrameType 2-2;
SG_MUL_VAL_ 1906 UnknownData1 IsoTpFrameType 4-15;
SG_MUL_VAL_ 1906 SeparationTimeRaw IsoTpFrameType 3-3;
SG_MUL_VAL_ 1906 SingleData2 IsoTpFrameType 0-0;
SG_MUL_VAL_ 1906 ConsecutiveData2 IsoTpFrameType 2-2;
SG_MUL_VAL_ 1906 UnknownData2 IsoTpFrameType 4-15;
SG_MUL_VAL_ 1906 FirstData1 IsoTpFrameType 1-1;
SG_MUL_VAL_ 1906 SingleData3 IsoTpFrameType 0-0;
SG_MUL_VAL_ 1906 ConsecutiveData3 IsoTpFrameType 2-2;
SG_MUL_VAL_ 1906 UnknownData3 IsoTpFrameType 4-15;
SG_MUL_VAL_ 1906 FirstData2 IsoTpFrameType 1-1;
SG_MUL_VAL_ 1906 FlowPadding1 IsoTpFrameType 3-3;
SG_MUL_VAL_ 1906 SingleData4 IsoTpFrameType 0-0;
SG_MUL_VAL_ 1906 ConsecutiveData4 IsoTpFrameType 2-2;
SG_MUL_VAL_ 1906 UnknownData4 IsoTpFrameType 4-15;
SG_MUL_VAL_ 1906 FirstData3 IsoTpFrameType 1-1;
SG_MUL_VAL_ 1906 FlowPadding2 IsoTpFrameType 3-3;
SG_MUL_VAL_ 1906 SingleData5 IsoTpFrameType 0-0;
SG_MUL_VAL_ 1906 ConsecutiveData5 IsoTpFrameType 2-2;
SG_MUL_VAL_ 1906 UnknownData5 IsoTpFrameType 4-15;
SG_MUL_VAL_ 1906 FirstData4 IsoTpFrameType 1-1;
SG_MUL_VAL_ 1906 FlowPadding3 IsoTpFrameType 3-3;
SG_MUL_VAL_ 1906 SingleData6 IsoTpFrameType 0-0;
SG_MUL_VAL_ 1906 ConsecutiveData6 IsoTpFrameType 2-2;
SG_MUL_VAL_ 1906 UnknownData6 IsoTpFrameType 4-15;
SG_MUL_VAL_ 1906 FirstData5 IsoTpFrameType 1-1;
SG_MUL_VAL_ 1906 FlowPadding4 IsoTpFrameType 3-3;
SG_MUL_VAL_ 1906 SingleData7 IsoTpFrameType 0-0;
SG_MUL_VAL_ 1906 ConsecutiveData7 IsoTpFrameType 2-2;
SG_MUL_VAL_ 1906 UnknownData7 IsoTpFrameType 4-15;
SG_MUL_VAL_ 1906 FirstData6 IsoTpFrameType 1-1;
SG_MUL_VAL_ 1906 FlowPadding5 IsoTpFrameType 3-3;
SG_MUL_VAL_ 1907 SingleFrameLength IsoTpFrameType 0-0;
SG_MUL_VAL_ 1907 FirstFrameLength IsoTpFrameType 1-1;
SG_MUL_VAL_ 1907 ConsecutiveSequence IsoTpFrameType 2-2;
SG_MUL_VAL_ 1907 FlowStatus IsoTpFrameType 3-3;
SG_MUL_VAL_ 1907 UnknownPciLow IsoTpFrameType 4-15;
SG_MUL_VAL_ 1907 BlockSize IsoTpFrameType 3-3;
SG_MUL_VAL_ 1907 SingleData1 IsoTpFrameType 0-0;
SG_MUL_VAL_ 1907 ConsecutiveData1 IsoTpFrameType 2-2;
SG_MUL_VAL_ 1907 UnknownData1 IsoTpFrameType 4-15;
SG_MUL_VAL_ 1907 SeparationTimeRaw IsoTpFrameType 3-3;
SG_MUL_VAL_ 1907 SingleData2 IsoTpFrameType 0-0;
SG_MUL_VAL_ 1907 ConsecutiveData2 IsoTpFrameType 2-2;
SG_MUL_VAL_ 1907 UnknownData2 IsoTpFrameType 4-15;
SG_MUL_VAL_ 1907 FirstData1 IsoTpFrameType 1-1;
SG_MUL_VAL_ 1907 SingleData3 IsoTpFrameType 0-0;
SG_MUL_VAL_ 1907 ConsecutiveData3 IsoTpFrameType 2-2;
SG_MUL_VAL_ 1907 UnknownData3 IsoTpFrameType 4-15;
SG_MUL_VAL_ 1907 FirstData2 IsoTpFrameType 1-1;
SG_MUL_VAL_ 1907 FlowPadding1 IsoTpFrameType 3-3;
SG_MUL_VAL_ 1907 SingleData4 IsoTpFrameType 0-0;
SG_MUL_VAL_ 1907 ConsecutiveData4 IsoTpFrameType 2-2;
SG_MUL_VAL_ 1907 UnknownData4 IsoTpFrameType 4-15;
SG_MUL_VAL_ 1907 FirstData3 IsoTpFrameType 1-1;
SG_MUL_VAL_ 1907 FlowPadding2 IsoTpFrameType 3-3;
SG_MUL_VAL_ 1907 SingleData5 IsoTpFrameType 0-0;
SG_MUL_VAL_ 1907 ConsecutiveData5 IsoTpFrameType 2-2;
SG_MUL_VAL_ 1907 UnknownData5 IsoTpFrameType 4-15;
SG_MUL_VAL_ 1907 FirstData4 IsoTpFrameType 1-1;
SG_MUL_VAL_ 1907 FlowPadding3 IsoTpFrameType 3-3;
SG_MUL_VAL_ 1907 SingleData6 IsoTpFrameType 0-0;
SG_MUL_VAL_ 1907 ConsecutiveData6 IsoTpFrameType 2-2;
SG_MUL_VAL_ 1907 UnknownData6 IsoTpFrameType 4-15;
SG_MUL_VAL_ 1907 FirstData5 IsoTpFrameType 1-1;
SG_MUL_VAL_ 1907 FlowPadding4 IsoTpFrameType 3-3;
SG_MUL_VAL_ 1907 SingleData7 IsoTpFrameType 0-0;
SG_MUL_VAL_ 1907 ConsecutiveData7 IsoTpFrameType 2-2;
SG_MUL_VAL_ 1907 UnknownData7 IsoTpFrameType 4-15;
SG_MUL_VAL_ 1907 FirstData6 IsoTpFrameType 1-1;
SG_MUL_VAL_ 1907 FlowPadding5 IsoTpFrameType 3-3;
SG_MUL_VAL_ 1908 SingleFrameLength IsoTpFrameType 0-0;
SG_MUL_VAL_ 1908 FirstFrameLength IsoTpFrameType 1-1;
SG_MUL_VAL_ 1908 ConsecutiveSequence IsoTpFrameType 2-2;
SG_MUL_VAL_ 1908 FlowStatus IsoTpFrameType 3-3;
SG_MUL_VAL_ 1908 UnknownPciLow IsoTpFrameType 4-15;
SG_MUL_VAL_ 1908 BlockSize IsoTpFrameType 3-3;
SG_MUL_VAL_ 1908 SingleData1 IsoTpFrameType 0-0;
SG_MUL_VAL_ 1908 ConsecutiveData1 IsoTpFrameType 2-2;
SG_MUL_VAL_ 1908 UnknownData1 IsoTpFrameType 4-15;
SG_MUL_VAL_ 1908 SeparationTimeRaw IsoTpFrameType 3-3;
SG_MUL_VAL_ 1908 SingleData2 IsoTpFrameType 0-0;
SG_MUL_VAL_ 1908 ConsecutiveData2 IsoTpFrameType 2-2;
SG_MUL_VAL_ 1908 UnknownData2 IsoTpFrameType 4-15;
SG_MUL_VAL_ 1908 FirstData1 IsoTpFrameType 1-1;
SG_MUL_VAL_ 1908 SingleData3 IsoTpFrameType 0-0;
SG_MUL_VAL_ 1908 ConsecutiveData3 IsoTpFrameType 2-2;
SG_MUL_VAL_ 1908 UnknownData3 IsoTpFrameType 4-15;
SG_MUL_VAL_ 1908 FirstData2 IsoTpFrameType 1-1;
SG_MUL_VAL_ 1908 FlowPadding1 IsoTpFrameType 3-3;
SG_MUL_VAL_ 1908 SingleData4 IsoTpFrameType 0-0;
SG_MUL_VAL_ 1908 ConsecutiveData4 IsoTpFrameType 2-2;
SG_MUL_VAL_ 1908 UnknownData4 IsoTpFrameType 4-15;
SG_MUL_VAL_ 1908 FirstData3 IsoTpFrameType 1-1;
SG_MUL_VAL_ 1908 FlowPadding2 IsoTpFrameType 3-3;
SG_MUL_VAL_ 1908 SingleData5 IsoTpFrameType 0-0;
SG_MUL_VAL_ 1908 ConsecutiveData5 IsoTpFrameType 2-2;
SG_MUL_VAL_ 1908 UnknownData5 IsoTpFrameType 4-15;
SG_MUL_VAL_ 1908 FirstData4 IsoTpFrameType 1-1;
SG_MUL_VAL_ 1908 FlowPadding3 IsoTpFrameType 3-3;
SG_MUL_VAL_ 1908 SingleData6 IsoTpFrameType 0-0;
SG_MUL_VAL_ 1908 ConsecutiveData6 IsoTpFrameType 2-2;
SG_MUL_VAL_ 1908 UnknownData6 IsoTpFrameType 4-15;
SG_MUL_VAL_ 1908 FirstData5 IsoTpFrameType 1-1;
SG_MUL_VAL_ 1908 FlowPadding4 IsoTpFrameType 3-3;
SG_MUL_VAL_ 1908 SingleData7 IsoTpFrameType 0-0;
SG_MUL_VAL_ 1908 ConsecutiveData7 IsoTpFrameType 2-2;
SG_MUL_VAL_ 1908 UnknownData7 IsoTpFrameType 4-15;
SG_MUL_VAL_ 1908 FirstData6 IsoTpFrameType 1-1;
SG_MUL_VAL_ 1908 FlowPadding5 IsoTpFrameType 3-3;
SG_MUL_VAL_ 1912 SingleFrameLength IsoTpFrameType 0-0;
SG_MUL_VAL_ 1912 FirstFrameLength IsoTpFrameType 1-1;
SG_MUL_VAL_ 1912 ConsecutiveSequence IsoTpFrameType 2-2;
SG_MUL_VAL_ 1912 FlowStatus IsoTpFrameType 3-3;
SG_MUL_VAL_ 1912 UnknownPciLow IsoTpFrameType 4-15;
SG_MUL_VAL_ 1912 BlockSize IsoTpFrameType 3-3;
SG_MUL_VAL_ 1912 SingleData1 IsoTpFrameType 0-0;
SG_MUL_VAL_ 1912 ConsecutiveData1 IsoTpFrameType 2-2;
SG_MUL_VAL_ 1912 UnknownData1 IsoTpFrameType 4-15;
SG_MUL_VAL_ 1912 SeparationTimeRaw IsoTpFrameType 3-3;
SG_MUL_VAL_ 1912 SingleData2 IsoTpFrameType 0-0;
SG_MUL_VAL_ 1912 ConsecutiveData2 IsoTpFrameType 2-2;
SG_MUL_VAL_ 1912 UnknownData2 IsoTpFrameType 4-15;
SG_MUL_VAL_ 1912 FirstData1 IsoTpFrameType 1-1;
SG_MUL_VAL_ 1912 SingleData3 IsoTpFrameType 0-0;
SG_MUL_VAL_ 1912 ConsecutiveData3 IsoTpFrameType 2-2;
SG_MUL_VAL_ 1912 UnknownData3 IsoTpFrameType 4-15;
SG_MUL_VAL_ 1912 FirstData2 IsoTpFrameType 1-1;
SG_MUL_VAL_ 1912 FlowPadding1 IsoTpFrameType 3-3;
SG_MUL_VAL_ 1912 SingleData4 IsoTpFrameType 0-0;
SG_MUL_VAL_ 1912 ConsecutiveData4 IsoTpFrameType 2-2;
SG_MUL_VAL_ 1912 UnknownData4 IsoTpFrameType 4-15;
SG_MUL_VAL_ 1912 FirstData3 IsoTpFrameType 1-1;
SG_MUL_VAL_ 1912 FlowPadding2 IsoTpFrameType 3-3;
SG_MUL_VAL_ 1912 SingleData5 IsoTpFrameType 0-0;
SG_MUL_VAL_ 1912 ConsecutiveData5 IsoTpFrameType 2-2;
SG_MUL_VAL_ 1912 UnknownData5 IsoTpFrameType 4-15;
SG_MUL_VAL_ 1912 FirstData4 IsoTpFrameType 1-1;
SG_MUL_VAL_ 1912 FlowPadding3 IsoTpFrameType 3-3;
SG_MUL_VAL_ 1912 SingleData6 IsoTpFrameType 0-0;
SG_MUL_VAL_ 1912 ConsecutiveData6 IsoTpFrameType 2-2;
SG_MUL_VAL_ 1912 UnknownData6 IsoTpFrameType 4-15;
SG_MUL_VAL_ 1912 FirstData5 IsoTpFrameType 1-1;
SG_MUL_VAL_ 1912 FlowPadding4 IsoTpFrameType 3-3;
SG_MUL_VAL_ 1912 SingleData7 IsoTpFrameType 0-0;
SG_MUL_VAL_ 1912 ConsecutiveData7 IsoTpFrameType 2-2;
SG_MUL_VAL_ 1912 UnknownData7 IsoTpFrameType 4-15;
SG_MUL_VAL_ 1912 FirstData6 IsoTpFrameType 1-1;
SG_MUL_VAL_ 1912 FlowPadding5 IsoTpFrameType 3-3;
SG_MUL_VAL_ 1915 SingleFrameLength IsoTpFrameType 0-0;
SG_MUL_VAL_ 1915 FirstFrameLength IsoTpFrameType 1-1;
SG_MUL_VAL_ 1915 ConsecutiveSequence IsoTpFrameType 2-2;
SG_MUL_VAL_ 1915 FlowStatus IsoTpFrameType 3-3;
SG_MUL_VAL_ 1915 UnknownPciLow IsoTpFrameType 4-15;
SG_MUL_VAL_ 1915 BlockSize IsoTpFrameType 3-3;
SG_MUL_VAL_ 1915 SingleData1 IsoTpFrameType 0-0;
SG_MUL_VAL_ 1915 ConsecutiveData1 IsoTpFrameType 2-2;
SG_MUL_VAL_ 1915 UnknownData1 IsoTpFrameType 4-15;
SG_MUL_VAL_ 1915 SeparationTimeRaw IsoTpFrameType 3-3;
SG_MUL_VAL_ 1915 SingleData2 IsoTpFrameType 0-0;
SG_MUL_VAL_ 1915 ConsecutiveData2 IsoTpFrameType 2-2;
SG_MUL_VAL_ 1915 UnknownData2 IsoTpFrameType 4-15;
SG_MUL_VAL_ 1915 FirstData1 IsoTpFrameType 1-1;
SG_MUL_VAL_ 1915 SingleData3 IsoTpFrameType 0-0;
SG_MUL_VAL_ 1915 ConsecutiveData3 IsoTpFrameType 2-2;
SG_MUL_VAL_ 1915 UnknownData3 IsoTpFrameType 4-15;
SG_MUL_VAL_ 1915 FirstData2 IsoTpFrameType 1-1;
SG_MUL_VAL_ 1915 FlowPadding1 IsoTpFrameType 3-3;
SG_MUL_VAL_ 1915 SingleData4 IsoTpFrameType 0-0;
SG_MUL_VAL_ 1915 ConsecutiveData4 IsoTpFrameType 2-2;
SG_MUL_VAL_ 1915 UnknownData4 IsoTpFrameType 4-15;
SG_MUL_VAL_ 1915 FirstData3 IsoTpFrameType 1-1;
SG_MUL_VAL_ 1915 FlowPadding2 IsoTpFrameType 3-3;
SG_MUL_VAL_ 1915 SingleData5 IsoTpFrameType 0-0;
SG_MUL_VAL_ 1915 ConsecutiveData5 IsoTpFrameType 2-2;
SG_MUL_VAL_ 1915 UnknownData5 IsoTpFrameType 4-15;
SG_MUL_VAL_ 1915 FirstData4 IsoTpFrameType 1-1;
SG_MUL_VAL_ 1915 FlowPadding3 IsoTpFrameType 3-3;
SG_MUL_VAL_ 1915 SingleData6 IsoTpFrameType 0-0;
SG_MUL_VAL_ 1915 ConsecutiveData6 IsoTpFrameType 2-2;
SG_MUL_VAL_ 1915 UnknownData6 IsoTpFrameType 4-15;
SG_MUL_VAL_ 1915 FirstData5 IsoTpFrameType 1-1;
SG_MUL_VAL_ 1915 FlowPadding4 IsoTpFrameType 3-3;
SG_MUL_VAL_ 1915 SingleData7 IsoTpFrameType 0-0;
SG_MUL_VAL_ 1915 ConsecutiveData7 IsoTpFrameType 2-2;
SG_MUL_VAL_ 1915 UnknownData7 IsoTpFrameType 4-15;
SG_MUL_VAL_ 1915 FirstData6 IsoTpFrameType 1-1;
SG_MUL_VAL_ 1915 FlowPadding5 IsoTpFrameType 3-3;
SG_MUL_VAL_ 1916 SingleFrameLength IsoTpFrameType 0-0;
SG_MUL_VAL_ 1916 FirstFrameLength IsoTpFrameType 1-1;
SG_MUL_VAL_ 1916 ConsecutiveSequence IsoTpFrameType 2-2;
SG_MUL_VAL_ 1916 FlowStatus IsoTpFrameType 3-3;
SG_MUL_VAL_ 1916 UnknownPciLow IsoTpFrameType 4-15;
SG_MUL_VAL_ 1916 BlockSize IsoTpFrameType 3-3;
SG_MUL_VAL_ 1916 SingleData1 IsoTpFrameType 0-0;
SG_MUL_VAL_ 1916 ConsecutiveData1 IsoTpFrameType 2-2;
SG_MUL_VAL_ 1916 UnknownData1 IsoTpFrameType 4-15;
SG_MUL_VAL_ 1916 SeparationTimeRaw IsoTpFrameType 3-3;
SG_MUL_VAL_ 1916 SingleData2 IsoTpFrameType 0-0;
SG_MUL_VAL_ 1916 ConsecutiveData2 IsoTpFrameType 2-2;
SG_MUL_VAL_ 1916 UnknownData2 IsoTpFrameType 4-15;
SG_MUL_VAL_ 1916 FirstData1 IsoTpFrameType 1-1;
SG_MUL_VAL_ 1916 SingleData3 IsoTpFrameType 0-0;
SG_MUL_VAL_ 1916 ConsecutiveData3 IsoTpFrameType 2-2;
SG_MUL_VAL_ 1916 UnknownData3 IsoTpFrameType 4-15;
SG_MUL_VAL_ 1916 FirstData2 IsoTpFrameType 1-1;
SG_MUL_VAL_ 1916 FlowPadding1 IsoTpFrameType 3-3;
SG_MUL_VAL_ 1916 SingleData4 IsoTpFrameType 0-0;
SG_MUL_VAL_ 1916 ConsecutiveData4 IsoTpFrameType 2-2;
SG_MUL_VAL_ 1916 UnknownData4 IsoTpFrameType 4-15;
SG_MUL_VAL_ 1916 FirstData3 IsoTpFrameType 1-1;
SG_MUL_VAL_ 1916 FlowPadding2 IsoTpFrameType 3-3;
SG_MUL_VAL_ 1916 SingleData5 IsoTpFrameType 0-0;
SG_MUL_VAL_ 1916 ConsecutiveData5 IsoTpFrameType 2-2;
SG_MUL_VAL_ 1916 UnknownData5 IsoTpFrameType 4-15;
SG_MUL_VAL_ 1916 FirstData4 IsoTpFrameType 1-1;
SG_MUL_VAL_ 1916 FlowPadding3 IsoTpFrameType 3-3;
SG_MUL_VAL_ 1916 SingleData6 IsoTpFrameType 0-0;
SG_MUL_VAL_ 1916 ConsecutiveData6 IsoTpFrameType 2-2;
SG_MUL_VAL_ 1916 UnknownData6 IsoTpFrameType 4-15;
SG_MUL_VAL_ 1916 FirstData5 IsoTpFrameType 1-1;
SG_MUL_VAL_ 1916 FlowPadding4 IsoTpFrameType 3-3;
SG_MUL_VAL_ 1916 SingleData7 IsoTpFrameType 0-0;
SG_MUL_VAL_ 1916 ConsecutiveData7 IsoTpFrameType 2-2;
SG_MUL_VAL_ 1916 UnknownData7 IsoTpFrameType 4-15;
SG_MUL_VAL_ 1916 FirstData6 IsoTpFrameType 1-1;
SG_MUL_VAL_ 1916 FlowPadding5 IsoTpFrameType 3-3;
SG_MUL_VAL_ 1917 SingleFrameLength IsoTpFrameType 0-0;
SG_MUL_VAL_ 1917 FirstFrameLength IsoTpFrameType 1-1;
SG_MUL_VAL_ 1917 ConsecutiveSequence IsoTpFrameType 2-2;
SG_MUL_VAL_ 1917 FlowStatus IsoTpFrameType 3-3;
SG_MUL_VAL_ 1917 UnknownPciLow IsoTpFrameType 4-15;
SG_MUL_VAL_ 1917 BlockSize IsoTpFrameType 3-3;
SG_MUL_VAL_ 1917 SingleData1 IsoTpFrameType 0-0;
SG_MUL_VAL_ 1917 ConsecutiveData1 IsoTpFrameType 2-2;
SG_MUL_VAL_ 1917 UnknownData1 IsoTpFrameType 4-15;
SG_MUL_VAL_ 1917 SeparationTimeRaw IsoTpFrameType 3-3;
SG_MUL_VAL_ 1917 SingleData2 IsoTpFrameType 0-0;
SG_MUL_VAL_ 1917 ConsecutiveData2 IsoTpFrameType 2-2;
SG_MUL_VAL_ 1917 UnknownData2 IsoTpFrameType 4-15;
SG_MUL_VAL_ 1917 FirstData1 IsoTpFrameType 1-1;
SG_MUL_VAL_ 1917 SingleData3 IsoTpFrameType 0-0;
SG_MUL_VAL_ 1917 ConsecutiveData3 IsoTpFrameType 2-2;
SG_MUL_VAL_ 1917 UnknownData3 IsoTpFrameType 4-15;
SG_MUL_VAL_ 1917 FirstData2 IsoTpFrameType 1-1;
SG_MUL_VAL_ 1917 FlowPadding1 IsoTpFrameType 3-3;
SG_MUL_VAL_ 1917 SingleData4 IsoTpFrameType 0-0;
SG_MUL_VAL_ 1917 ConsecutiveData4 IsoTpFrameType 2-2;
SG_MUL_VAL_ 1917 UnknownData4 IsoTpFrameType 4-15;
SG_MUL_VAL_ 1917 FirstData3 IsoTpFrameType 1-1;
SG_MUL_VAL_ 1917 FlowPadding2 IsoTpFrameType 3-3;
SG_MUL_VAL_ 1917 SingleData5 IsoTpFrameType 0-0;
SG_MUL_VAL_ 1917 ConsecutiveData5 IsoTpFrameType 2-2;
SG_MUL_VAL_ 1917 UnknownData5 IsoTpFrameType 4-15;
SG_MUL_VAL_ 1917 FirstData4 IsoTpFrameType 1-1;
SG_MUL_VAL_ 1917 FlowPadding3 IsoTpFrameType 3-3;
SG_MUL_VAL_ 1917 SingleData6 IsoTpFrameType 0-0;
SG_MUL_VAL_ 1917 ConsecutiveData6 IsoTpFrameType 2-2;
SG_MUL_VAL_ 1917 UnknownData6 IsoTpFrameType 4-15;
SG_MUL_VAL_ 1917 FirstData5 IsoTpFrameType 1-1;
SG_MUL_VAL_ 1917 FlowPadding4 IsoTpFrameType 3-3;
SG_MUL_VAL_ 1917 SingleData7 IsoTpFrameType 0-0;
SG_MUL_VAL_ 1917 ConsecutiveData7 IsoTpFrameType 2-2;
SG_MUL_VAL_ 1917 UnknownData7 IsoTpFrameType 4-15;
SG_MUL_VAL_ 1917 FirstData6 IsoTpFrameType 1-1;
SG_MUL_VAL_ 1917 FlowPadding5 IsoTpFrameType 3-3;
SG_MUL_VAL_ 2047 SingleFrameLength IsoTpFrameType 0-0;
SG_MUL_VAL_ 2047 FirstFrameLength IsoTpFrameType 1-1;
SG_MUL_VAL_ 2047 ConsecutiveSequence IsoTpFrameType 2-2;
SG_MUL_VAL_ 2047 FlowStatus IsoTpFrameType 3-3;
SG_MUL_VAL_ 2047 UnknownPciLow IsoTpFrameType 4-15;
SG_MUL_VAL_ 2047 BlockSize IsoTpFrameType 3-3;
SG_MUL_VAL_ 2047 SingleData1 IsoTpFrameType 0-0;
SG_MUL_VAL_ 2047 ConsecutiveData1 IsoTpFrameType 2-2;
SG_MUL_VAL_ 2047 UnknownData1 IsoTpFrameType 4-15;
SG_MUL_VAL_ 2047 SeparationTimeRaw IsoTpFrameType 3-3;
SG_MUL_VAL_ 2047 SingleData2 IsoTpFrameType 0-0;
SG_MUL_VAL_ 2047 ConsecutiveData2 IsoTpFrameType 2-2;
SG_MUL_VAL_ 2047 UnknownData2 IsoTpFrameType 4-15;
SG_MUL_VAL_ 2047 FirstData1 IsoTpFrameType 1-1;
SG_MUL_VAL_ 2047 SingleData3 IsoTpFrameType 0-0;
SG_MUL_VAL_ 2047 ConsecutiveData3 IsoTpFrameType 2-2;
SG_MUL_VAL_ 2047 UnknownData3 IsoTpFrameType 4-15;
SG_MUL_VAL_ 2047 FirstData2 IsoTpFrameType 1-1;
SG_MUL_VAL_ 2047 FlowPadding1 IsoTpFrameType 3-3;
SG_MUL_VAL_ 2047 SingleData4 IsoTpFrameType 0-0;
SG_MUL_VAL_ 2047 ConsecutiveData4 IsoTpFrameType 2-2;
SG_MUL_VAL_ 2047 UnknownData4 IsoTpFrameType 4-15;
SG_MUL_VAL_ 2047 FirstData3 IsoTpFrameType 1-1;
SG_MUL_VAL_ 2047 FlowPadding2 IsoTpFrameType 3-3;
SG_MUL_VAL_ 2047 SingleData5 IsoTpFrameType 0-0;
SG_MUL_VAL_ 2047 ConsecutiveData5 IsoTpFrameType 2-2;
SG_MUL_VAL_ 2047 UnknownData5 IsoTpFrameType 4-15;
SG_MUL_VAL_ 2047 FirstData4 IsoTpFrameType 1-1;
SG_MUL_VAL_ 2047 FlowPadding3 IsoTpFrameType 3-3;
SG_MUL_VAL_ 2047 SingleData6 IsoTpFrameType 0-0;
SG_MUL_VAL_ 2047 ConsecutiveData6 IsoTpFrameType 2-2;
SG_MUL_VAL_ 2047 UnknownData6 IsoTpFrameType 4-15;
SG_MUL_VAL_ 2047 FirstData5 IsoTpFrameType 1-1;
SG_MUL_VAL_ 2047 FlowPadding4 IsoTpFrameType 3-3;
SG_MUL_VAL_ 2047 SingleData7 IsoTpFrameType 0-0;
SG_MUL_VAL_ 2047 ConsecutiveData7 IsoTpFrameType 2-2;
SG_MUL_VAL_ 2047 UnknownData7 IsoTpFrameType 4-15;
SG_MUL_VAL_ 2047 FirstData6 IsoTpFrameType 1-1;
SG_MUL_VAL_ 2047 FlowPadding5 IsoTpFrameType 3-3;
